BU_:  Airbag BAP_Tester ICAS1_Gateway ICAS1_KommunikationsServer LE1 LE2 Motor_BEV Schaltbetaetigung

BU_:  Airbag BAP_Tester ICAS1_Gateway ICAS1_KommunikationsServer LE1 LE2 Motor_BEV Schaltbetaetigung

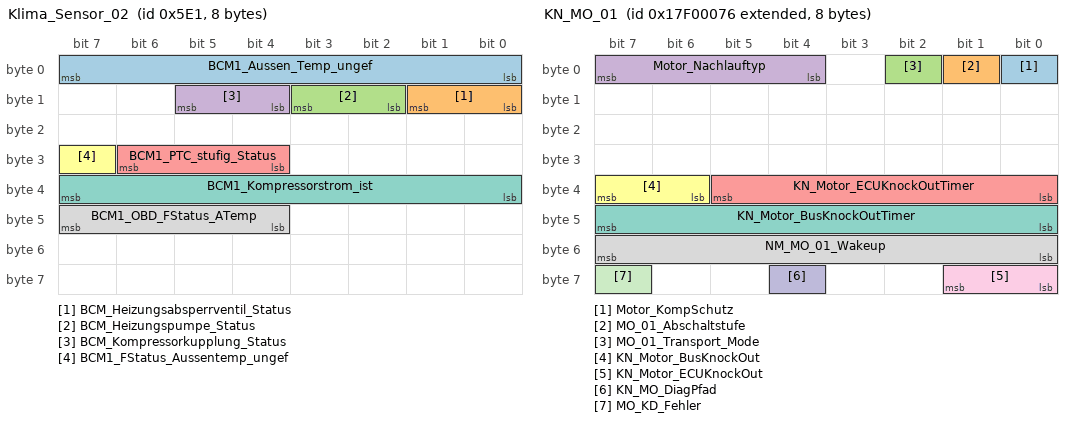
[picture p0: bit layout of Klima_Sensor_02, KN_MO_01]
BO_ 1505 Klima_Sensor_02: 8 ICAS1_Gateway
 SG_ BCM1_Aussen_Temp_ungef  : 0|8@1+ (0.500000,-50.000000) [-50.000000|76.000000] "Unit_DegreCelsi" LE1 LE2 Motor_BEV
 SG_ BCM_Heizungsabsperrventil_Status  : 8|2@1+ (1.000000,0.000000) [0.000000|3.000000] "" Vector__XXX
 SG_ BCM_Heizungspumpe_Status  : 10|2@1+ (1.000000,0.000000) [0.000000|3.000000] "" Vector__XXX
 SG_ BCM_Kompressorkupplung_Status  : 12|2@1+ (1.000000,0.000000) [0.000000|3.000000] "" Vector__XXX
 SG_ BCM1_PTC_stufig_Status  : 28|3@1+ (1.000000,0.000000) [0.000000|7.000000] "" Vector__XXX
 SG_ BCM1_FStatus_Aussentemp_ungef  : 31|1@1+ (1.000000,0.000000) [0.000000|1.000000] "" Vector__XXX
 SG_ BCM1_Kompressorstrom_ist  : 32|8@1+ (4.000000,0.000000) [0.000000|1000.000000] "Unit_MilliAmper" Vector__XXX
 SG_ BCM1_OBD_FStatus_ATemp  : 44|4@1+ (1.000000,0.000000) [0.000000|15.000000] "" Vector__XXX

BO_ 2549088277 KN_Airbag_01: 8 Airbag
 SG_ Airbag_01_KompSchutz  : 0|1@1+ (1.000000,0.000000) [0.000000|1.000000] "" Vector__XXX
 SG_ Airbag_01_Abschaltstufe  : 1|1@1+ (1.000000,0.000000) [0.000000|1.000000] "" Vector__XXX
 SG_ Airbag_01_Transport_Mode  : 2|1@1+ (1.000000,0.000000) [0.000000|1.000000] "" Vector__XXX
 SG_ Airbag_01_Nachlauftyp  : 4|4@1+ (1.000000,0.000000) [0.000000|15.000000] "" ICAS1_Gateway
 SG_ NM_Airbag_01_Wakeup  : 48|8@1+ (1.000000,0.000000) [0.000000|255.000000] "" Vector__XXX
 SG_ KN_AB_DiagPfad  : 60|1@1+ (1.000000,0.000000) [0.000000|1.000000] "" ICAS1_Gateway
 SG_ AB_KD_Fehler  : 63|1@1+ (1.000000,0.000000) [0.000000|1.000000] "" ICAS1_Gateway

BO_ 2549088380 KN_EMotor_01: 8 LE1
 SG_ EMotor_KompSchutz  : 0|1@1+ (1.000000,0.000000) [0.000000|1.000000] "" Vector__XXX
 SG_ EMotor_01_Abschaltstufe  : 1|1@1+ (1.000000,0.000000) [0.000000|1.000000] "" Vector__XXX
 SG_ EMotor_01_Transport_Mode  : 2|1@1+ (1.000000,0.000000) [0.000000|1.000000] "" Vector__XXX
 SG_ EMotor_Nachlauftyp  : 4|4@1+ (1.000000,0.000000) [0.000000|15.000000] "" ICAS1_Gateway
 SG_ NM_EMotor_01_Wakeup  : 48|8@1+ (1.000000,0.000000) [0.000000|255.000000] "" Vector__XXX
 SG_ KN_EM_HYB_DiagPfad  : 60|1@1+ (1.000000,0.000000) [0.000000|1.000000] "" ICAS1_Gateway
 SG_ EM_HYB_KD_Fehler  : 63|1@1+ (1.000000,0.000000) [0.000000|1.000000] "" ICAS1_Gateway

BO_ 2549088272 KN_Gateway: 8 ICAS1_Gateway
 SG_ Gateway_KompSchutz  : 0|1@1+ (1.000000,0.000000) [0.000000|1.000000] "" Vector__XXX
 SG_ Gateway_Abschaltstufe  : 1|1@1+ (1.000000,0.000000) [0.000000|1.000000] "" Vector__XXX
 SG_ Gateway_Transport_Mode  : 2|1@1+ (1.000000,0.000000) [0.000000|1.000000] "" Vector__XXX
 SG_ Gateway_Nachlauftyp  : 4|4@1+ (1.000000,0.000000) [0.000000|15.000000] "" Vector__XXX
 SG_ NM_Gateway_Wakeup  : 48|8@1+ (1.000000,0.000000) [0.000000|255.000000] "" Vector__XXX
 SG_ KN_GW_DiagPfad  : 60|1@1+ (1.000000,0.000000) [0.000000|1.000000] "" Vector__XXX
 SG_ GW_KD_Fehler  : 63|1@1+ (1.000000,0.000000) [0.000000|1.000000] "" Vector__XXX

BO_ 2549088440 KN_LE2: 8 LE2
 SG_ LE2_KompSchutz  : 0|1@1+ (1.000000,0.000000) [0.000000|1.000000] "" Vector__XXX
 SG_ LE2_Abschaltstufe  : 1|1@1+ (1.000000,0.000000) [0.000000|1.000000] "" Vector__XXX
 SG_ LE2_Transport_Mode  : 2|1@1+ (1.000000,0.000000) [0.000000|1.000000] "" Vector__XXX
 SG_ LE2_Nachlauftyp  : 4|4@1+ (1.000000,0.000000) [0.000000|15.000000] "" ICAS1_Gateway
 SG_ NM_LE2_Wakeup  : 48|8@1+ (1.000000,0.000000) [0.000000|255.000000] "" Vector__XXX
 SG_ KN_LE2_DiagPfad  : 60|1@1+ (1.000000,0.000000) [0.000000|1.000000] "" ICAS1_Gateway
 SG_ LE2_KD_Fehler  : 63|1@1+ (1.000000,0.000000) [0.000000|1.000000] "" ICAS1_Gateway

BO_ 2549088374 KN_MO_01: 8 Motor_BEV
 SG_ Motor_KompSchutz  : 0|1@1+ (1.000000,0.000000) [0.000000|1.000000] "" Vector__XXX
 SG_ MO_01_Abschaltstufe  : 1|1@1+ (1.000000,0.000000) [0.000000|1.000000] "" Vector__XXX
 SG_ MO_01_Transport_Mode  : 2|1@1+ (1.000000,0.000000) [0.000000|1.000000] "" Vector__XXX
 SG_ Motor_Nachlauftyp  : 4|4@1+ (1.000000,0.000000) [0.000000|15.000000] "" ICAS1_Gateway
 SG_ KN_Motor_ECUKnockOutTimer  : 32|6@1+ (1.000000,0.000000) [0.000000|62.000000] "Unit_Minut" Vector__XXX
 SG_ KN_Motor_BusKnockOut  : 38|2@1+ (1.000000,0.000000) [0.000000|3.000000] "" Vector__XXX
 SG_ KN_Motor_BusKnockOutTimer  : 40|8@1+ (1.000000,0.000000) [0.000000|254.000000] "" Vector__XXX
 SG_ NM_MO_01_Wakeup  : 48|8@1+ (1.000000,0.000000) [0.000000|255.000000] "" Vector__XXX
 SG_ KN_Motor_ECUKnockOut  : 56|2@1+ (1.000000,0.000000) [0.000000|3.000000] "" Vector__XXX
 SG_ KN_MO_DiagPfad  : 60|1@1+ (1.000000,0.000000) [0.000000|1.000000] "" ICAS1_Gateway
 SG_ MO_KD_Fehler  : 63|1@1+ (1.000000,0.000000) [0.000000|1.000000] "" ICAS1_Gateway

BO_ 2621440277 KS_Airbag_01_Req_FD: 16 ICAS1_Gateway
 SG_ KS_Airbag_01_Req_FD_Data  : 0|128@1+ (1.000000,0.000000) [0.000000|340282366920938463463374607431768211456.000000] "" Airbag

BO_ 2621571349 KS_Airbag_01_Resp_FD: 16 Airbag
 SG_ KS_Airbag_01_Resp_FD_Data  : 0|128@1+ (1.000000,0.000000) [0.000000|340282366920938463463374607431768211456.000000] "" ICAS1_Gateway

BO_ 982 Licht_hinten_01: 8 ICAS1_Gateway
 SG_ Licht_hinten_01_BZ  : 0|4@1+ (1.000000,0.000000) [0.000000|15.000000] "" Vector__XXX
 SG_ LH_Aussenlicht_def  : 7|1@1+ (1.000000,0.000000) [0.000000|1.000000] "" Vector__XXX
 SG_ LH_Standlicht_H_aktiv  : 8|1@1+ (1.000000,0.000000) [0.000000|1.000000] "" Vector__XXX
 SG_ LH_Parklicht_HL_aktiv  : 9|1@1+ (1.000000,0.000000) [0.000000|1.000000] "" Vector__XXX
 SG_ LH_Parklicht_HR_aktiv  : 10|1@1+ (1.000000,0.000000) [0.000000|1.000000] "" Vector__XXX
 SG_ LH_Bremslicht_H_aktiv  : 11|1@1+ (1.000000,0.000000) [0.000000|1.000000] "" Vector__XXX
 SG_ LH_Nebelschluss_aktiv  : 12|1@1+ (1.000000,0.000000) [0.000000|1.000000] "" Vector__XXX
 SG_ LH_Rueckfahrlicht_aktiv  : 13|1@1+ (1.000000,0.000000) [0.000000|1.000000] "" Vector__XXX
 SG_ LH_Blinker_HL_akt  : 14|1@1+ (1.000000,0.000000) [0.000000|1.000000] "" Vector__XXX
 SG_ LH_Blinker_HR_akt  : 15|1@1+ (1.000000,0.000000) [0.000000|1.000000] "" Vector__XXX
 SG_ LH_Blinker_li_def  : 16|1@1+ (1.000000,0.000000) [0.000000|1.000000] "" Vector__XXX
 SG_ LH_Bremsl_li_def  : 17|1@1+ (1.000000,0.000000) [0.000000|1.000000] "" Vector__XXX
 SG_ LH_Schlusslicht_li_def  : 18|1@1+ (1.000000,0.000000) [0.000000|1.000000] "" Vector__XXX
 SG_ LH_Rueckf_li_def  : 19|1@1+ (1.000000,0.000000) [0.000000|1.000000] "" Vector__XXX
 SG_ LH_Nebel_li_def  : 20|1@1+ (1.000000,0.000000) [0.000000|1.000000] "" Vector__XXX
 SG_ LH_Schluss_Brems_Nebel_li_def  : 21|1@1+ (1.000000,0.000000) [0.000000|1.000000] "" Vector__XXX
 SG_ LH_Schluss_Brems_Nebel_re_def  : 22|1@1+ (1.000000,0.000000) [0.000000|1.000000] "" Vector__XXX
 SG_ LH_Zusatzschlussl_def  : 23|1@1+ (1.000000,0.000000) [0.000000|1.000000] "" Vector__XXX
 SG_ LH_Schluss_Brems_li_def  : 24|1@1+ (1.000000,0.000000) [0.000000|1.000000] "" Vector__XXX
 SG_ LH_Schluss_Nebel_li_def  : 25|1@1+ (1.000000,0.000000) [0.000000|1.000000] "" Vector__XXX
 SG_ LH_SL_BRL_BLK_li_def  : 26|1@1+ (1.000000,0.000000) [0.000000|1.000000] "" Vector__XXX
 SG_ LH_Brems_Blk_li_def  : 27|1@1+ (1.000000,0.000000) [0.000000|1.000000] "" Vector__XXX
 SG_ LH_Diag_Status_re_def  : 28|1@1+ (1.000000,0.000000) [0.000000|1.000000] "" Vector__XXX
 SG_ LH_Diag_Status_li_def  : 29|1@1+ (1.000000,0.000000) [0.000000|1.000000] "" Vector__XXX
 SG_ LH_Diag_LED_li_def  : 30|1@1+ (1.000000,0.000000) [0.000000|1.000000] "" Vector__XXX
 SG_ LH_Diag_LED_re_def  : 31|1@1+ (1.000000,0.000000) [0.000000|1.000000] "" Vector__XXX
 SG_ LH_Blinker_re_def  : 32|1@1+ (1.000000,0.000000) [0.000000|1.000000] "" Vector__XXX
 SG_ LH_Bremsl_re_def  : 33|1@1+ (1.000000,0.000000) [0.000000|1.000000] "" Vector__XXX
 SG_ LH_Schlusslicht_re_def  : 34|1@1+ (1.000000,0.000000) [0.000000|1.000000] "" Vector__XXX
 SG_ LH_Rueckf_re_def  : 35|1@1+ (1.000000,0.000000) [0.000000|1.000000] "" Vector__XXX
 SG_ LH_Nebel_re_def  : 36|1@1+ (1.000000,0.000000) [0.000000|1.000000] "" Vector__XXX
 SG_ LH_Schluss_Brems_mi_def  : 37|1@1+ (1.000000,0.000000) [0.000000|1.000000] "" Vector__XXX
 SG_ LH_Schluss_Brems_re_def  : 40|1@1+ (1.000000,0.000000) [0.000000|1.000000] "" Vector__XXX
 SG_ LH_Schluss_Nebel_re_def  : 41|1@1+ (1.000000,0.000000) [0.000000|1.000000] "" Vector__XXX
 SG_ LH_SL_BRL_BLK_re_def  : 42|1@1+ (1.000000,0.000000) [0.000000|1.000000] "" Vector__XXX
 SG_ LH_Brems_Blk_re_def  : 43|1@1+ (1.000000,0.000000) [0.000000|1.000000] "" Vector__XXX
 SG_ LH_Kennzl_def  : 48|1@1+ (1.000000,0.000000) [0.000000|1.000000] "" Vector__XXX
 SG_ LH_3_Bremsl_def  : 49|1@1+ (1.000000,0.000000) [0.000000|1.000000] "" Motor_BEV
 SG_ LH_Nebel_mi_def  : 50|1@1+ (1.000000,0.000000) [0.000000|1.000000] "" Vector__XXX
 SG_ LH_Rueckf_mi_def  : 51|1@1+ (1.000000,0.000000) [0.000000|1.000000] "" Vector__XXX
 SG_ LH_Schlusslicht_mi_def  : 52|1@1+ (1.000000,0.000000) [0.000000|1.000000] "" Vector__XXX
 SG_ LH_Bremsl_li_ges_def  : 54|1@1+ (1.000000,0.000000) [0.000000|1.000000] "" Motor_BEV
 SG_ LH_Bremsl_re_ges_def  : 55|1@1+ (1.000000,0.000000) [0.000000|1.000000] "" Motor_BEV
 SG_ LH_Bremsl_mi_def  : 61|1@1+ (1.000000,0.000000) [0.000000|1.000000] "" Vector__XXX
 SG_ BRL_als_SHL  : 62|1@1+ (1.000000,0.000000) [0.000000|1.000000] "" Vector__XXX

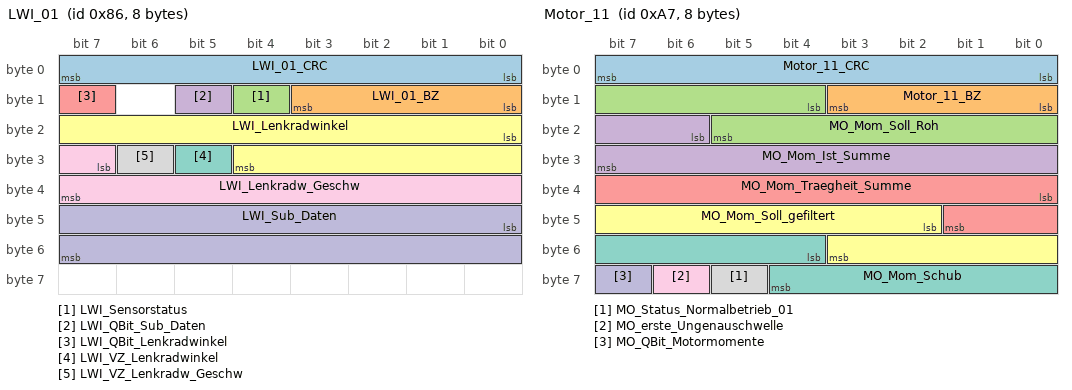
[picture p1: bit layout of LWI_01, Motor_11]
BO_ 134 LWI_01: 8 ICAS1_Gateway
 SG_ LWI_01_CRC  : 0|8@1+ (1.000000,0.000000) [0.000000|255.000000] "" Airbag Motor_BEV
 SG_ LWI_01_BZ  : 8|4@1+ (1.000000,0.000000) [0.000000|15.000000] "" Airbag Motor_BEV
 SG_ LWI_Sensorstatus  : 12|1@1+ (1.000000,0.000000) [0.000000|1.000000] "" Airbag Motor_BEV
 SG_ LWI_QBit_Sub_Daten  : 13|1@1+ (1.000000,0.000000) [0.000000|1.000000] "" Vector__XXX
 SG_ LWI_QBit_Lenkradwinkel  : 15|1@1+ (1.000000,0.000000) [0.000000|1.000000] "" Airbag Motor_BEV
 SG_ LWI_Lenkradwinkel  : 16|13@1+ (0.100000,0.000000) [0.000000|800.000000] "Unit_DegreOfArc" Airbag Motor_BEV
 SG_ LWI_VZ_Lenkradwinkel  : 29|1@1+ (1.000000,0.000000) [0.000000|1.000000] "" Airbag Motor_BEV
 SG_ LWI_VZ_Lenkradw_Geschw  : 30|1@1+ (1.000000,0.000000) [0.000000|1.000000] "" Vector__XXX
 SG_ LWI_Lenkradw_Geschw  : 31|9@1+ (5.000000,0.000000) [0.000000|2500.000000] "Unit_DegreOfArcPerSecon" Airbag
 SG_ LWI_Sub_Daten  : 40|16@1+ (1.000000,0.000000) [0.000000|65535.000000] "" Vector__XXX

BO_ 817 MFL_01: 8 ICAS1_Gateway
 SG_ MFL_Zaehler  : 0|4@1+ (1.000000,0.000000) [0.000000|15.000000] "" Vector__XXX
 SG_ MFL_Toggle  : 4|1@1+ (1.000000,0.000000) [0.000000|1.000000] "" Vector__XXX
 SG_ MFL_Lokalaktiv  : 5|1@1+ (1.000000,0.000000) [0.000000|1.000000] "" Vector__XXX
 SG_ MFL_M_Taste  : 6|1@1+ (1.000000,0.000000) [0.000000|1.000000] "" Vector__XXX
 SG_ MFL_Paddle_Verbau  : 7|1@1+ (1.000000,0.000000) [0.000000|1.000000] "" Vector__XXX
 SG_ MFL_Tastencode_1  : 8|8@1+ (1.000000,0.000000) [0.000000|255.000000] "" Vector__XXX
 SG_ MFL_Tastencode_2  : 16|8@1+ (1.000000,0.000000) [0.000000|255.000000] "" Vector__XXX
 SG_ MFL_Eventcode_1  : 24|4@1+ (1.000000,0.000000) [0.000000|15.000000] "" Vector__XXX
 SG_ MFL_Eventcode_2  : 28|4@1+ (1.000000,0.000000) [0.000000|15.000000] "" Vector__XXX
 SG_ MFL_Marke  : 32|4@1+ (1.000000,0.000000) [0.000000|15.000000] "" Vector__XXX
 SG_ MFL_Variante  : 36|4@1+ (1.000000,0.000000) [0.000000|15.000000] "" Vector__XXX
 SG_ MFL_Dummy_0_Signal_1  : 40|8@1+ (1.000000,0.000000) [0.000000|255.000000] "" Vector__XXX
 SG_ MFL_Tip_Down  : 48|1@1+ (1.000000,0.000000) [0.000000|1.000000] "" Motor_BEV
 SG_ MFL_Tip_Up  : 49|1@1+ (1.000000,0.000000) [0.000000|1.000000] "" Motor_BEV
 SG_ MFL_SatModul_links_Err  : 50|1@1+ (1.000000,0.000000) [0.000000|1.000000] "" Vector__XXX
 SG_ MFL_SatModul_rechts_Err  : 51|1@1+ (1.000000,0.000000) [0.000000|1.000000] "" Vector__XXX
 SG_ MFL_Dummy_0_Signal_2  : 52|1@1+ (1.000000,0.000000) [0.000000|1.000000] "" Vector__XXX
 SG_ MFL_Dummy_0_Signal_3  : 53|1@1+ (1.000000,0.000000) [0.000000|1.000000] "" Vector__XXX
 SG_ MFL_LR_HZG_Status  : 54|1@1+ (1.000000,0.000000) [0.000000|1.000000] "" Vector__XXX
 SG_ MFL_LR_HZG_Err  : 55|1@1+ (1.000000,0.000000) [0.000000|1.000000] "" Vector__XXX
 SG_ MFL_Signalhorn  : 56|1@1+ (1.000000,0.000000) [0.000000|1.000000] "" Vector__XXX
 SG_ MFL_Signalhorn_Err  : 57|1@1+ (1.000000,0.000000) [0.000000|1.000000] "" Vector__XXX
 SG_ MFL_Tip_links_Err  : 58|1@1+ (1.000000,0.000000) [0.000000|1.000000] "" Vector__XXX
 SG_ MFL_Tip_rechts_Err  : 59|1@1+ (1.000000,0.000000) [0.000000|1.000000] "" Vector__XXX
 SG_ MFL_Taste_links_Err  : 60|1@1+ (1.000000,0.000000) [0.000000|1.000000] "" Vector__XXX
 SG_ MFL_Taste_rechts_Err  : 61|1@1+ (1.000000,0.000000) [0.000000|1.000000] "" Vector__XXX
 SG_ MFL_ECU_Err  : 62|1@1+ (1.000000,0.000000) [0.000000|1.000000] "" Vector__XXX
 SG_ MFL_Response_Err  : 63|1@1+ (1.000000,0.000000) [0.000000|1.000000] "" Vector__XXX

BO_ 15 MO_SOPC: 1 Motor_BEV
 SG_ MO_SOPC  : 0|1@1+ (1.000000,0.000000) [0.000000|1.000000] "" Vector__XXX

BO_ 1600 Motor_07: 8 Motor_BEV
 SG_ MO_QBit_Ansaugluft_Temp  : 0|1@1+ (1.000000,0.000000) [0.000000|1.000000] "" Vector__XXX
 SG_ MO_QBit_Oel_Temp  : 1|1@1+ (1.000000,0.000000) [0.000000|1.000000] "" Vector__XXX
 SG_ MO_QBit_Kuehlmittel_Temp  : 2|1@1+ (1.000000,0.000000) [0.000000|1.000000] "" Vector__XXX
 SG_ MO_KL15_Abschaltempfehlung  : 3|1@1+ (1.000000,0.000000) [0.000000|1.000000] "" Vector__XXX
 SG_ MO_HYB_Fehler_HV_Netz  : 4|1@1+ (1.000000,0.000000) [0.000000|1.000000] "" Vector__XXX
 SG_ MO_aktives_Getriebeheizen  : 5|1@1+ (1.000000,0.000000) [0.000000|1.000000] "" Vector__XXX
 SG_ MO_Absperrventil_oeffnen  : 6|2@1+ (1.000000,0.000000) [0.000000|3.000000] "" Vector__XXX
 SG_ MO_Ansaugluft_Temp  : 8|8@1+ (0.750000,-48.000000) [-48.000000|141.750000] "Unit_DegreCelsi" Vector__XXX
 SG_ MO_Oel_Temp  : 16|8@1+ (1.000000,-60.000000) [-60.000000|192.000000] "Unit_DegreCelsi" Vector__XXX
 SG_ MO_Kuehlmittel_Temp  : 24|8@1+ (0.750000,-48.000000) [-48.000000|141.750000] "Unit_DegreCelsi" Vector__XXX
 SG_ MO_Hoeheninfo  : 32|8@1+ (0.007810,0.000000) [0.000000|1.983740] "" Vector__XXX
 SG_ MO_Kennfeldk  : 40|1@1+ (1.000000,0.000000) [0.000000|1.000000] "" Vector__XXX
 SG_ MO_Versionsinfo_02  : 41|5@1+ (1.000000,0.000000) [0.000000|31.000000] "" Vector__XXX
 SG_ MO_QBit_Hoeheninfo  : 46|1@1+ (1.000000,0.000000) [0.000000|1.000000] "" Vector__XXX
 SG_ MO_Getriebe_kuehlen  : 47|1@1+ (1.000000,0.000000) [0.000000|1.000000] "" Vector__XXX
 SG_ MO_Mom_Traegheit_02  : 48|5@1+ (0.010000,0.000000) [0.000000|0.310000] "Unit_KiloGramMeterSquar" Vector__XXX
 SG_ MO_Heizungspumpenansteuerung  : 53|4@1+ (10.000000,0.000000) [0.000000|100.000000] "Unit_PerCent" Vector__XXX
 SG_ MO_SpannungsAnf  : 57|1@1+ (1.000000,0.000000) [0.000000|1.000000] "" Vector__XXX
 SG_ MO_Nachlaufzeit_Heizungspumpe  : 58|6@1+ (15.000000,0.000000) [0.000000|945.000000] "Unit_Secon" Vector__XXX

BO_ 167 Motor_11: 8 Motor_BEV
 SG_ Motor_11_CRC  : 0|8@1+ (1.000000,0.000000) [0.000000|255.000000] "" ICAS1_Gateway
 SG_ Motor_11_BZ  : 8|4@1+ (1.000000,0.000000) [0.000000|15.000000] "" ICAS1_Gateway
 SG_ MO_Mom_Soll_Roh  : 12|10@1+ (1.000000,-509.000000) [-509.000000|509.000000] "" ICAS1_Gateway
 SG_ MO_Mom_Ist_Summe  : 22|10@1+ (1.000000,-509.000000) [-509.000000|509.000000] "" ICAS1_Gateway
 SG_ MO_Mom_Traegheit_Summe  : 32|10@1+ (1.000000,-509.000000) [-509.000000|509.000000] "" ICAS1_Gateway
 SG_ MO_Mom_Soll_gefiltert  : 42|10@1+ (1.000000,-509.000000) [-509.000000|509.000000] "" ICAS1_Gateway
 SG_ MO_Mom_Schub  : 52|9@1+ (1.000000,-509.000000) [-509.000000|0.000000] "" ICAS1_Gateway
 SG_ MO_Status_Normalbetrieb_01  : 61|1@1+ (1.000000,0.000000) [0.000000|1.000000] "" ICAS1_Gateway
 SG_ MO_erste_Ungenauschwelle  : 62|1@1+ (1.000000,0.000000) [0.000000|1.000000] "" ICAS1_Gateway
 SG_ MO_QBit_Motormomente  : 63|1@1+ (1.000000,0.000000) [0.000000|1.000000] "" ICAS1_Gateway

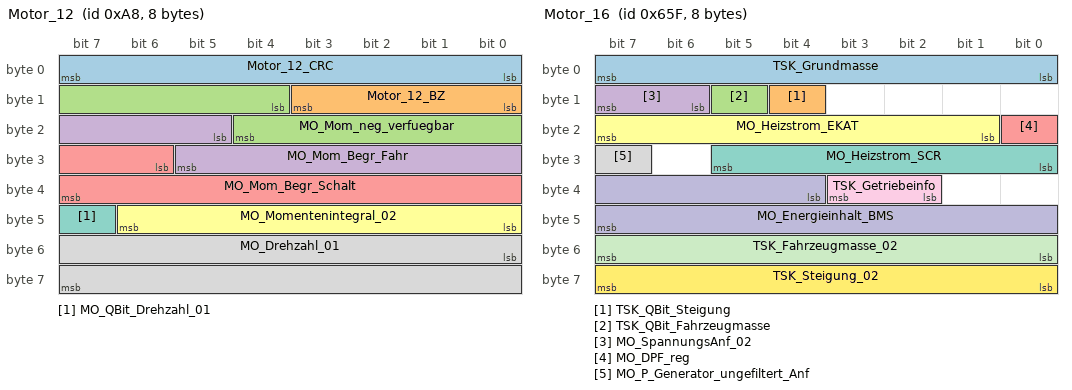
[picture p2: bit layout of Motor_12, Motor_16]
BO_ 168 Motor_12: 8 Motor_BEV
 SG_ Motor_12_CRC  : 0|8@1+ (1.000000,0.000000) [0.000000|255.000000] "" ICAS1_Gateway
 SG_ Motor_12_BZ  : 8|4@1+ (1.000000,0.000000) [0.000000|15.000000] "" ICAS1_Gateway
 SG_ MO_Mom_neg_verfuegbar  : 12|9@1+ (1.000000,-509.000000) [-509.000000|0.000000] "" ICAS1_Gateway
 SG_ MO_Mom_Begr_Fahr  : 21|9@1+ (1.000000,0.000000) [0.000000|509.000000] "" ICAS1_Gateway
 SG_ MO_Mom_Begr_Schalt  : 30|10@1+ (1.000000,-509.000000) [-509.000000|509.000000] "" ICAS1_Gateway
 SG_ MO_Momentenintegral_02  : 40|7@1+ (1.000000,0.000000) [0.000000|100.000000] "Unit_PerCent" ICAS1_Gateway
 SG_ MO_QBit_Drehzahl_01  : 47|1@1+ (1.000000,0.000000) [0.000000|1.000000] "" Airbag ICAS1_Gateway LE2
 SG_ MO_Drehzahl_01  : 48|16@1+ (0.250000,0.000000) [0.000000|16383.000000] "Unit_MinutInver" ICAS1_Gateway

BO_ 958 Motor_14: 8 Motor_BEV
 SG_ Motor_14_CRC  : 0|8@1+ (1.000000,0.000000) [0.000000|255.000000] "" ICAS1_Gateway
 SG_ Motor_14_BZ  : 8|4@1+ (1.000000,0.000000) [0.000000|15.000000] "" ICAS1_Gateway
 SG_ MO_StartStopp_Status  : 12|2@1+ (1.000000,0.000000) [0.000000|3.000000] "" ICAS1_Gateway
 SG_ MO_StartStopp_Wiederstart  : 14|1@1+ (1.000000,0.000000) [0.000000|1.000000] "" ICAS1_Gateway
 SG_ MO_StartStopp_Motorstopp  : 15|1@1+ (1.000000,0.000000) [0.000000|1.000000] "" ICAS1_Gateway
 SG_ MO_Freig_Reku  : 16|2@1+ (1.000000,0.000000) [0.000000|3.000000] "" ICAS1_Gateway
 SG_ MO_Kl_75  : 18|1@1+ (1.000000,0.000000) [0.000000|1.000000] "" ICAS1_Gateway
 SG_ MO_Kl_50  : 19|1@1+ (1.000000,0.000000) [0.000000|1.000000] "" ICAS1_Gateway
 SG_ MO_Gangposition  : 20|4@1+ (1.000000,0.000000) [0.000000|15.000000] "" ICAS1_Gateway
 SG_ MO_StartStopp_Fahrerwunsch  : 24|2@1+ (1.000000,0.000000) [0.000000|3.000000] "" ICAS1_Gateway
 SG_ MO_HYB_Fahrbereitschaft  : 26|1@1+ (1.000000,0.000000) [0.000000|1.000000] "" ICAS1_Gateway
 SG_ MO_Ext_E_Fahrt_aktiv  : 27|1@1+ (1.000000,0.000000) [0.000000|1.000000] "" ICAS1_Gateway
 SG_ MO_Fahrer_bremst  : 28|1@1+ (1.000000,0.000000) [0.000000|1.000000] "" Airbag ICAS1_Gateway
 SG_ MO_QBit_Fahrer_bremst  : 29|1@1+ (1.000000,0.000000) [0.000000|1.000000] "" Airbag ICAS1_Gateway
 SG_ MO_BLS  : 30|1@1+ (1.000000,0.000000) [0.000000|1.000000] "" Airbag ICAS1_Gateway
 SG_ MO_Konsistenz_Bremsped  : 31|1@1+ (1.000000,0.000000) [0.000000|1.000000] "" ICAS1_Gateway
 SG_ MO_Timeout_ESP  : 32|1@1+ (1.000000,0.000000) [0.000000|1.000000] "" ICAS1_Gateway
 SG_ MO_Klima_Eingr  : 33|2@1+ (1.000000,0.000000) [0.000000|3.000000] "" ICAS1_Gateway
 SG_ MO_Aussp_Anlass  : 35|1@1+ (1.000000,0.000000) [0.000000|1.000000] "" ICAS1_Gateway
 SG_ MO_Freig_Anlass  : 36|1@1+ (1.000000,0.000000) [0.000000|1.000000] "" ICAS1_Gateway
 SG_ MO_Kuppl_schalter  : 37|1@1+ (1.000000,0.000000) [0.000000|1.000000] "" ICAS1_Gateway
 SG_ MO_Interlock  : 38|1@1+ (1.000000,0.000000) [0.000000|1.000000] "" ICAS1_Gateway
 SG_ MO_Motor_laeuft  : 39|1@1+ (1.000000,0.000000) [0.000000|1.000000] "" ICAS1_Gateway
 SG_ MO_Kickdown  : 40|1@1+ (1.000000,0.000000) [0.000000|1.000000] "" ICAS1_Gateway ICAS1_KommunikationsServer
 SG_ MO_QBit_KL_75  : 41|1@1+ (1.000000,0.000000) [0.000000|1.000000] "" ICAS1_Gateway
 SG_ MO_EKlKomLeiRed  : 42|2@1+ (1.000000,0.000000) [0.000000|3.000000] "" ICAS1_Gateway
 SG_ MO_Handshake_STH  : 44|1@1+ (1.000000,0.000000) [0.000000|1.000000] "" ICAS1_Gateway
 SG_ MO_BKV_Unterdruckwarnung  : 45|1@1+ (1.000000,0.000000) [0.000000|1.000000] "" ICAS1_Gateway
 SG_ MO_Freigabe_Segeln  : 46|1@1+ (1.000000,0.000000) [0.000000|1.000000] "" ICAS1_Gateway
 SG_ MO_PTC_Status  : 47|3@1+ (1.000000,0.000000) [0.000000|7.000000] "" ICAS1_Gateway
 SG_ MO_QBit_Gangposition  : 50|1@1+ (1.000000,0.000000) [0.000000|1.000000] "" ICAS1_Gateway
 SG_ MO_Signalquelle_Gangposition  : 51|1@1+ (1.000000,0.000000) [0.000000|1.000000] "" ICAS1_Gateway
 SG_ MO_Remotestart_Betrieb  : 52|1@1+ (1.000000,0.000000) [0.000000|1.000000] "" ICAS1_Gateway
 SG_ MO_Remotestart_moeglich  : 53|1@1+ (1.000000,0.000000) [0.000000|1.000000] "" ICAS1_Gateway
 SG_ MO_FMAus_aktiv  : 55|1@1+ (1.000000,0.000000) [0.000000|1.000000] "" ICAS1_Gateway
 SG_ MO_FMAus_Startvariante  : 56|2@1+ (1.000000,0.000000) [0.000000|3.000000] "" ICAS1_Gateway
 SG_ MO_BMS_NV_Anf_stuetzen  : 58|1@1+ (1.000000,0.000000) [0.000000|1.000000] "" ICAS1_Gateway
 SG_ MO_Zylinderabschaltung  : 59|2@1+ (1.000000,0.000000) [0.000000|3.000000] "" ICAS1_Gateway
 SG_ MO_HYB_VM_aktiv  : 61|1@1+ (1.000000,0.000000) [0.000000|1.000000] "" ICAS1_Gateway
 SG_ MO_StartVorauss_erfuellt  : 62|2@1+ (1.000000,0.000000) [0.000000|3.000000] "" ICAS1_Gateway

BO_ 1631 Motor_16: 8 Motor_BEV
 SG_ TSK_Grundmasse  : 0|8@1+ (32.000000,0.000000) [0.000000|8128.000000] "Unit_KiloGram" ICAS1_Gateway
 SG_ TSK_QBit_Steigung  : 12|1@1+ (1.000000,0.000000) [0.000000|1.000000] "" ICAS1_Gateway
 SG_ TSK_QBit_Fahrzeugmasse  : 13|1@1+ (1.000000,0.000000) [0.000000|1.000000] "" ICAS1_Gateway
 SG_ MO_SpannungsAnf_02  : 14|2@1+ (1.000000,0.000000) [0.000000|3.000000] "" ICAS1_Gateway
 SG_ MO_DPF_reg  : 16|1@1+ (1.000000,0.000000) [0.000000|1.000000] "" ICAS1_Gateway
 SG_ MO_Heizstrom_EKAT  : 17|7@1+ (1.000000,0.000000) [0.000000|126.000000] "Unit_Amper" ICAS1_Gateway
 SG_ MO_Heizstrom_SCR  : 24|6@1+ (1.000000,0.000000) [0.000000|62.000000] "Unit_Amper" ICAS1_Gateway
 SG_ MO_P_Generator_ungefiltert_Anf  : 31|1@1+ (1.000000,0.000000) [0.000000|1.000000] "" ICAS1_Gateway
 SG_ TSK_Getriebeinfo  : 34|2@1+ (1.000000,0.000000) [0.000000|3.000000] "" ICAS1_Gateway
 SG_ MO_Energieinhalt_BMS  : 36|12@1+ (25.000000,0.000000) [0.000000|102325.000000] "Unit_WattHour" ICAS1_Gateway
 SG_ TSK_Fahrzeugmasse_02  : 48|8@1+ (32.000000,0.000000) [0.000000|8128.000000] "Unit_KiloGram" ICAS1_Gateway
 SG_ TSK_Steigung_02  : 56|8@1+ (0.800000,-101.600000) [-100.800000|101.600000] "Unit_PerCent" ICAS1_Gateway

BO_ 1648 Motor_18: 8 Motor_BEV
 SG_ MO_max_Ladedruck  : 0|6@1+ (0.100000,0.000000) [0.000000|6.300000] "Unit_Bar" ICAS1_Gateway
 SG_ MO_ANC_Kennfeld_Anf  : 6|2@1+ (1.000000,0.000000) [0.000000|3.000000] "" ICAS1_Gateway
 SG_ MO_Bremslicht_Reku  : 8|1@1+ (1.000000,0.000000) [0.000000|1.000000] "" ICAS1_Gateway
 SG_ MO_StartStopp_PopUp  : 9|2@1+ (1.000000,0.000000) [0.000000|3.000000] "" ICAS1_Gateway
 SG_ MO1_Sperr_Info_WFS  : 11|1@1+ (1.000000,0.000000) [0.000000|1.000000] "" ICAS1_Gateway
 SG_ MO1_Freigabe_Info_WFS  : 12|1@1+ (1.000000,0.000000) [0.000000|1.000000] "" ICAS1_Gateway
 SG_ MO_EPCL  : 13|3@1+ (1.000000,0.000000) [0.000000|7.000000] "" ICAS1_Gateway ICAS1_KommunikationsServer
 SG_ MO_Zylabsch_Texte_02  : 16|4@1+ (1.000000,0.000000) [0.000000|15.000000] "" ICAS1_Gateway
 SG_ MO_Fahrzeugtyp  : 20|3@1+ (1.000000,0.000000) [0.000000|7.000000] "" ICAS1_Gateway ICAS1_KommunikationsServer
 SG_ MO_NMAX_Schaltanzeige  : 23|9@1+ (25.000000,0.000000) [0.000000|12775.000000] "Unit_MinutInver" ICAS1_Gateway
 SG_ MO_Abstellzeit  : 32|8@1+ (8.000000,0.000000) [0.000000|2024.000000] "Unit_Minut" ICAS1_Gateway
 SG_ MO_Abstellzeit_Status  : 40|2@1+ (1.000000,0.000000) [0.000000|3.000000] "" ICAS1_Gateway
 SG_ MO1_Freigabe_Verfallsinfo_WFS  : 42|1@1+ (1.000000,0.000000) [0.000000|1.000000] "" ICAS1_Gateway
 SG_ MO_Hybrid_StartStopp_LED  : 43|2@1+ (1.000000,0.000000) [0.000000|3.000000] "" ICAS1_Gateway
 SG_ MO_Fehler_Zylabsch  : 45|2@1+ (1.000000,0.000000) [0.000000|3.000000] "" ICAS1_Gateway
 SG_ MO_Anzahl_Abgesch_Zyl  : 47|3@1+ (1.000000,0.000000) [0.000000|7.000000] "" ICAS1_Gateway
 SG_ MO_Zylabsch_Texte  : 50|2@1+ (1.000000,0.000000) [0.000000|3.000000] "" ICAS1_Gateway
 SG_ MO_Ethanol_BS_Texte  : 52|3@1+ (1.000000,0.000000) [0.000000|7.000000] "" ICAS1_Gateway
 SG_ MO_Drehzahl_Warnung  : 55|1@1+ (1.000000,0.000000) [0.000000|1.000000] "" ICAS1_Gateway
 SG_ MO_obere_Drehzahlgrenze  : 56|8@1+ (50.000000,0.000000) [50.000000|12750.000000] "Unit_MinutInver" ICAS1_Gateway

BU_:  Airbag BAP_Tester ICAS1_Gateway ICAS1_KommunikationsServer LE1 LE2 Motor_BEV Schaltbetaetigung

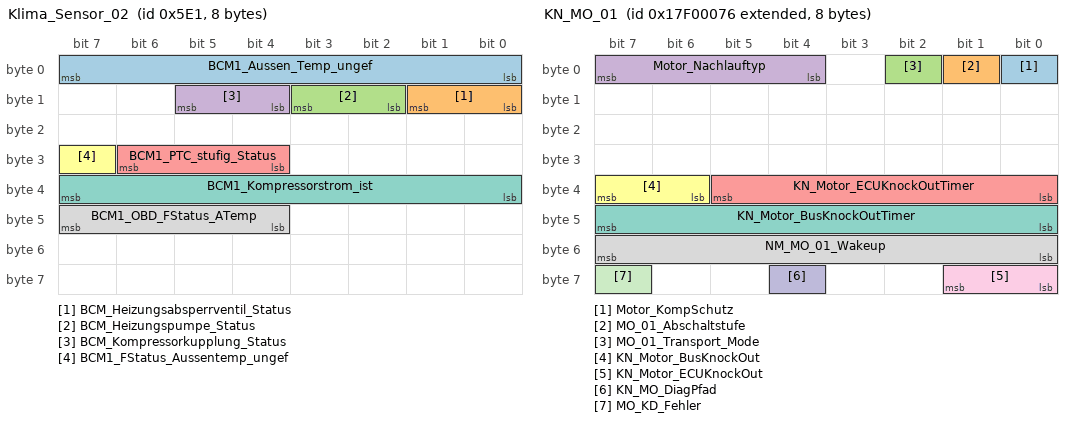
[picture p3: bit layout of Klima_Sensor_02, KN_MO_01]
BO_ 1505 Klima_Sensor_02: 8 ICAS1_Gateway
 SG_ BCM1_Aussen_Temp_ungef  : 0|8@1+ (0.500000,-50.000000) [-50.000000|76.000000] "Unit_DegreCelsi" LE1 LE2 Motor_BEV
 SG_ BCM_Heizungsabsperrventil_Status  : 8|2@1+ (1.000000,0.000000) [0.000000|3.000000] "" Vector__XXX
 SG_ BCM_Heizungspumpe_Status  : 10|2@1+ (1.000000,0.000000) [0.000000|3.000000] "" Vector__XXX
 SG_ BCM_Kompressorkupplung_Status  : 12|2@1+ (1.000000,0.000000) [0.000000|3.000000] "" Vector__XXX
 SG_ BCM1_PTC_stufig_Status  : 28|3@1+ (1.000000,0.000000) [0.000000|7.000000] "" Vector__XXX
 SG_ BCM1_FStatus_Aussentemp_ungef  : 31|1@1+ (1.000000,0.000000) [0.000000|1.000000] "" Vector__XXX
 SG_ BCM1_Kompressorstrom_ist  : 32|8@1+ (4.000000,0.000000) [0.000000|1000.000000] "Unit_MilliAmper" Vector__XXX
 SG_ BCM1_OBD_FStatus_ATemp  : 44|4@1+ (1.000000,0.000000) [0.000000|15.000000] "" Vector__XXX

BO_ 2549088277 KN_Airbag_01: 8 Airbag
 SG_ Airbag_01_KompSchutz  : 0|1@1+ (1.000000,0.000000) [0.000000|1.000000] "" Vector__XXX
 SG_ Airbag_01_Abschaltstufe  : 1|1@1+ (1.000000,0.000000) [0.000000|1.000000] "" Vector__XXX
 SG_ Airbag_01_Transport_Mode  : 2|1@1+ (1.000000,0.000000) [0.000000|1.000000] "" Vector__XXX
 SG_ Airbag_01_Nachlauftyp  : 4|4@1+ (1.000000,0.000000) [0.000000|15.000000] "" ICAS1_Gateway
 SG_ NM_Airbag_01_Wakeup  : 48|8@1+ (1.000000,0.000000) [0.000000|255.000000] "" Vector__XXX
 SG_ KN_AB_DiagPfad  : 60|1@1+ (1.000000,0.000000) [0.000000|1.000000] "" ICAS1_Gateway
 SG_ AB_KD_Fehler  : 63|1@1+ (1.000000,0.000000) [0.000000|1.000000] "" ICAS1_Gateway

BO_ 2549088380 KN_EMotor_01: 8 LE1
 SG_ EMotor_KompSchutz  : 0|1@1+ (1.000000,0.000000) [0.000000|1.000000] "" Vector__XXX
 SG_ EMotor_01_Abschaltstufe  : 1|1@1+ (1.000000,0.000000) [0.000000|1.000000] "" Vector__XXX
 SG_ EMotor_01_Transport_Mode  : 2|1@1+ (1.000000,0.000000) [0.000000|1.000000] "" Vector__XXX
 SG_ EMotor_Nachlauftyp  : 4|4@1+ (1.000000,0.000000) [0.000000|15.000000] "" ICAS1_Gateway
 SG_ NM_EMotor_01_Wakeup  : 48|8@1+ (1.000000,0.000000) [0.000000|255.000000] "" Vector__XXX
 SG_ KN_EM_HYB_DiagPfad  : 60|1@1+ (1.000000,0.000000) [0.000000|1.000000] "" ICAS1_Gateway
 SG_ EM_HYB_KD_Fehler  : 63|1@1+ (1.000000,0.000000) [0.000000|1.000000] "" ICAS1_Gateway

BO_ 2549088272 KN_Gateway: 8 ICAS1_Gateway
 SG_ Gateway_KompSchutz  : 0|1@1+ (1.000000,0.000000) [0.000000|1.000000] "" Vector__XXX
 SG_ Gateway_Abschaltstufe  : 1|1@1+ (1.000000,0.000000) [0.000000|1.000000] "" Vector__XXX
 SG_ Gateway_Transport_Mode  : 2|1@1+ (1.000000,0.000000) [0.000000|1.000000] "" Vector__XXX
 SG_ Gateway_Nachlauftyp  : 4|4@1+ (1.000000,0.000000) [0.000000|15.000000] "" Vector__XXX
 SG_ NM_Gateway_Wakeup  : 48|8@1+ (1.000000,0.000000) [0.000000|255.000000] "" Vector__XXX
 SG_ KN_GW_DiagPfad  : 60|1@1+ (1.000000,0.000000) [0.000000|1.000000] "" Vector__XXX
 SG_ GW_KD_Fehler  : 63|1@1+ (1.000000,0.000000) [0.000000|1.000000] "" Vector__XXX

BO_ 2549088440 KN_LE2: 8 LE2
 SG_ LE2_KompSchutz  : 0|1@1+ (1.000000,0.000000) [0.000000|1.000000] "" Vector__XXX
 SG_ LE2_Abschaltstufe  : 1|1@1+ (1.000000,0.000000) [0.000000|1.000000] "" Vector__XXX
 SG_ LE2_Transport_Mode  : 2|1@1+ (1.000000,0.000000) [0.000000|1.000000] "" Vector__XXX
 SG_ LE2_Nachlauftyp  : 4|4@1+ (1.000000,0.000000) [0.000000|15.000000] "" ICAS1_Gateway
 SG_ NM_LE2_Wakeup  : 48|8@1+ (1.000000,0.000000) [0.000000|255.000000] "" Vector__XXX
 SG_ KN_LE2_DiagPfad  : 60|1@1+ (1.000000,0.000000) [0.000000|1.000000] "" ICAS1_Gateway
 SG_ LE2_KD_Fehler  : 63|1@1+ (1.000000,0.000000) [0.000000|1.000000] "" ICAS1_Gateway

BO_ 2549088374 KN_MO_01: 8 Motor_BEV
 SG_ Motor_KompSchutz  : 0|1@1+ (1.000000,0.000000) [0.000000|1.000000] "" Vector__XXX
 SG_ MO_01_Abschaltstufe  : 1|1@1+ (1.000000,0.000000) [0.000000|1.000000] "" Vector__XXX
 SG_ MO_01_Transport_Mode  : 2|1@1+ (1.000000,0.000000) [0.000000|1.000000] "" Vector__XXX
 SG_ Motor_Nachlauftyp  : 4|4@1+ (1.000000,0.000000) [0.000000|15.000000] "" ICAS1_Gateway
 SG_ KN_Motor_ECUKnockOutTimer  : 32|6@1+ (1.000000,0.000000) [0.000000|62.000000] "Unit_Minut" Vector__XXX
 SG_ KN_Motor_BusKnockOut  : 38|2@1+ (1.000000,0.000000) [0.000000|3.000000] "" Vector__XXX
 SG_ KN_Motor_BusKnockOutTimer  : 40|8@1+ (1.000000,0.000000) [0.000000|254.000000] "" Vector__XXX
 SG_ NM_MO_01_Wakeup  : 48|8@1+ (1.000000,0.000000) [0.000000|255.000000] "" Vector__XXX
 SG_ KN_Motor_ECUKnockOut  : 56|2@1+ (1.000000,0.000000) [0.000000|3.000000] "" Vector__XXX
 SG_ KN_MO_DiagPfad  : 60|1@1+ (1.000000,0.000000) [0.000000|1.000000] "" ICAS1_Gateway
 SG_ MO_KD_Fehler  : 63|1@1+ (1.000000,0.000000) [0.000000|1.000000] "" ICAS1_Gateway

BO_ 2621440277 KS_Airbag_01_Req_FD: 16 ICAS1_Gateway
 SG_ KS_Airbag_01_Req_FD_Data  : 0|128@1+ (1.000000,0.000000) [0.000000|340282366920938463463374607431768211456.000000] "" Airbag

BO_ 2621571349 KS_Airbag_01_Resp_FD: 16 Airbag
 SG_ KS_Airbag_01_Resp_FD_Data  : 0|128@1+ (1.000000,0.000000) [0.000000|340282366920938463463374607431768211456.000000] "" ICAS1_Gateway

BO_ 982 Licht_hinten_01: 8 ICAS1_Gateway
 SG_ Licht_hinten_01_BZ  : 0|4@1+ (1.000000,0.000000) [0.000000|15.000000] "" Vector__XXX
 SG_ LH_Aussenlicht_def  : 7|1@1+ (1.000000,0.000000) [0.000000|1.000000] "" Vector__XXX
 SG_ LH_Standlicht_H_aktiv  : 8|1@1+ (1.000000,0.000000) [0.000000|1.000000] "" Vector__XXX
 SG_ LH_Parklicht_HL_aktiv  : 9|1@1+ (1.000000,0.000000) [0.000000|1.000000] "" Vector__XXX
 SG_ LH_Parklicht_HR_aktiv  : 10|1@1+ (1.000000,0.000000) [0.000000|1.000000] "" Vector__XXX
 SG_ LH_Bremslicht_H_aktiv  : 11|1@1+ (1.000000,0.000000) [0.000000|1.000000] "" Vector__XXX
 SG_ LH_Nebelschluss_aktiv  : 12|1@1+ (1.000000,0.000000) [0.000000|1.000000] "" Vector__XXX
 SG_ LH_Rueckfahrlicht_aktiv  : 13|1@1+ (1.000000,0.000000) [0.000000|1.000000] "" Vector__XXX
 SG_ LH_Blinker_HL_akt  : 14|1@1+ (1.000000,0.000000) [0.000000|1.000000] "" Vector__XXX
 SG_ LH_Blinker_HR_akt  : 15|1@1+ (1.000000,0.000000) [0.000000|1.000000] "" Vector__XXX
 SG_ LH_Blinker_li_def  : 16|1@1+ (1.000000,0.000000) [0.000000|1.000000] "" Vector__XXX
 SG_ LH_Bremsl_li_def  : 17|1@1+ (1.000000,0.000000) [0.000000|1.000000] "" Vector__XXX
 SG_ LH_Schlusslicht_li_def  : 18|1@1+ (1.000000,0.000000) [0.000000|1.000000] "" Vector__XXX
 SG_ LH_Rueckf_li_def  : 19|1@1+ (1.000000,0.000000) [0.000000|1.000000] "" Vector__XXX
 SG_ LH_Nebel_li_def  : 20|1@1+ (1.000000,0.000000) [0.000000|1.000000] "" Vector__XXX
 SG_ LH_Schluss_Brems_Nebel_li_def  : 21|1@1+ (1.000000,0.000000) [0.000000|1.000000] "" Vector__XXX
 SG_ LH_Schluss_Brems_Nebel_re_def  : 22|1@1+ (1.000000,0.000000) [0.000000|1.000000] "" Vector__XXX
 SG_ LH_Zusatzschlussl_def  : 23|1@1+ (1.000000,0.000000) [0.000000|1.000000] "" Vector__XXX
 SG_ LH_Schluss_Brems_li_def  : 24|1@1+ (1.000000,0.000000) [0.000000|1.000000] "" Vector__XXX
 SG_ LH_Schluss_Nebel_li_def  : 25|1@1+ (1.000000,0.000000) [0.000000|1.000000] "" Vector__XXX
 SG_ LH_SL_BRL_BLK_li_def  : 26|1@1+ (1.000000,0.000000) [0.000000|1.000000] "" Vector__XXX
 SG_ LH_Brems_Blk_li_def  : 27|1@1+ (1.000000,0.000000) [0.000000|1.000000] "" Vector__XXX
 SG_ LH_Diag_Status_re_def  : 28|1@1+ (1.000000,0.000000) [0.000000|1.000000] "" Vector__XXX
 SG_ LH_Diag_Status_li_def  : 29|1@1+ (1.000000,0.000000) [0.000000|1.000000] "" Vector__XXX
 SG_ LH_Diag_LED_li_def  : 30|1@1+ (1.000000,0.000000) [0.000000|1.000000] "" Vector__XXX
 SG_ LH_Diag_LED_re_def  : 31|1@1+ (1.000000,0.000000) [0.000000|1.000000] "" Vector__XXX
 SG_ LH_Blinker_re_def  : 32|1@1+ (1.000000,0.000000) [0.000000|1.000000] "" Vector__XXX
 SG_ LH_Bremsl_re_def  : 33|1@1+ (1.000000,0.000000) [0.000000|1.000000] "" Vector__XXX
 SG_ LH_Schlusslicht_re_def  : 34|1@1+ (1.000000,0.000000) [0.000000|1.000000] "" Vector__XXX
 SG_ LH_Rueckf_re_def  : 35|1@1+ (1.000000,0.000000) [0.000000|1.000000] "" Vector__XXX
 SG_ LH_Nebel_re_def  : 36|1@1+ (1.000000,0.000000) [0.000000|1.000000] "" Vector__XXX
 SG_ LH_Schluss_Brems_mi_def  : 37|1@1+ (1.000000,0.000000) [0.000000|1.000000] "" Vector__XXX
 SG_ LH_Schluss_Brems_re_def  : 40|1@1+ (1.000000,0.000000) [0.000000|1.000000] "" Vector__XXX
 SG_ LH_Schluss_Nebel_re_def  : 41|1@1+ (1.000000,0.000000) [0.000000|1.000000] "" Vector__XXX
 SG_ LH_SL_BRL_BLK_re_def  : 42|1@1+ (1.000000,0.000000) [0.000000|1.000000] "" Vector__XXX
 SG_ LH_Brems_Blk_re_def  : 43|1@1+ (1.000000,0.000000) [0.000000|1.000000] "" Vector__XXX
 SG_ LH_Kennzl_def  : 48|1@1+ (1.000000,0.000000) [0.000000|1.000000] "" Vector__XXX
 SG_ LH_3_Bremsl_def  : 49|1@1+ (1.000000,0.000000) [0.000000|1.000000] "" Motor_BEV
 SG_ LH_Nebel_mi_def  : 50|1@1+ (1.000000,0.000000) [0.000000|1.000000] "" Vector__XXX
 SG_ LH_Rueckf_mi_def  : 51|1@1+ (1.000000,0.000000) [0.000000|1.000000] "" Vector__XXX
 SG_ LH_Schlusslicht_mi_def  : 52|1@1+ (1.000000,0.000000) [0.000000|1.000000] "" Vector__XXX
 SG_ LH_Bremsl_li_ges_def  : 54|1@1+ (1.000000,0.000000) [0.000000|1.000000] "" Motor_BEV
 SG_ LH_Bremsl_re_ges_def  : 55|1@1+ (1.000000,0.000000) [0.000000|1.000000] "" Motor_BEV
 SG_ LH_Bremsl_mi_def  : 61|1@1+ (1.000000,0.000000) [0.000000|1.000000] "" Vector__XXX
 SG_ BRL_als_SHL  : 62|1@1+ (1.000000,0.000000) [0.000000|1.000000] "" Vector__XXX

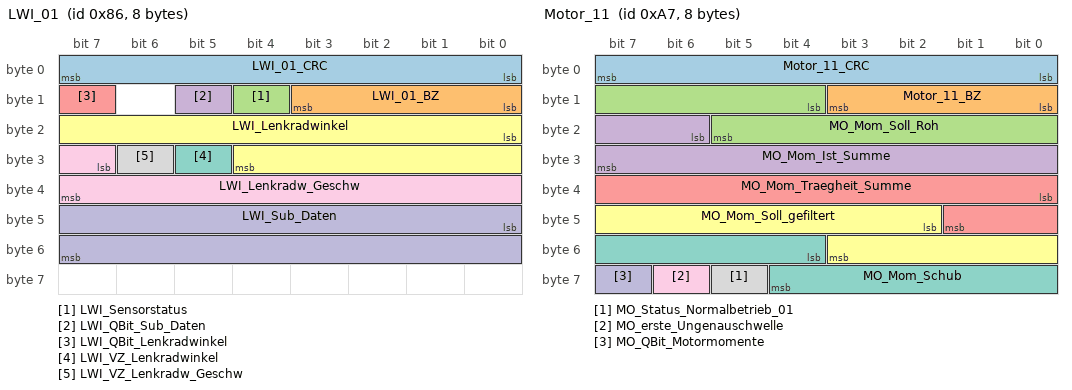
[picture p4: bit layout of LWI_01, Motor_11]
BO_ 134 LWI_01: 8 ICAS1_Gateway
 SG_ LWI_01_CRC  : 0|8@1+ (1.000000,0.000000) [0.000000|255.000000] "" Airbag Motor_BEV
 SG_ LWI_01_BZ  : 8|4@1+ (1.000000,0.000000) [0.000000|15.000000] "" Airbag Motor_BEV
 SG_ LWI_Sensorstatus  : 12|1@1+ (1.000000,0.000000) [0.000000|1.000000] "" Airbag Motor_BEV
 SG_ LWI_QBit_Sub_Daten  : 13|1@1+ (1.000000,0.000000) [0.000000|1.000000] "" Vector__XXX
 SG_ LWI_QBit_Lenkradwinkel  : 15|1@1+ (1.000000,0.000000) [0.000000|1.000000] "" Airbag Motor_BEV
 SG_ LWI_Lenkradwinkel  : 16|13@1+ (0.100000,0.000000) [0.000000|800.000000] "Unit_DegreOfArc" Airbag Motor_BEV
 SG_ LWI_VZ_Lenkradwinkel  : 29|1@1+ (1.000000,0.000000) [0.000000|1.000000] "" Airbag Motor_BEV
 SG_ LWI_VZ_Lenkradw_Geschw  : 30|1@1+ (1.000000,0.000000) [0.000000|1.000000] "" Vector__XXX
 SG_ LWI_Lenkradw_Geschw  : 31|9@1+ (5.000000,0.000000) [0.000000|2500.000000] "Unit_DegreOfArcPerSecon" Airbag
 SG_ LWI_Sub_Daten  : 40|16@1+ (1.000000,0.000000) [0.000000|65535.000000] "" Vector__XXX

BO_ 817 MFL_01: 8 ICAS1_Gateway
 SG_ MFL_Zaehler  : 0|4@1+ (1.000000,0.000000) [0.000000|15.000000] "" Vector__XXX
 SG_ MFL_Toggle  : 4|1@1+ (1.000000,0.000000) [0.000000|1.000000] "" Vector__XXX
 SG_ MFL_Lokalaktiv  : 5|1@1+ (1.000000,0.000000) [0.000000|1.000000] "" Vector__XXX
 SG_ MFL_M_Taste  : 6|1@1+ (1.000000,0.000000) [0.000000|1.000000] "" Vector__XXX
 SG_ MFL_Paddle_Verbau  : 7|1@1+ (1.000000,0.000000) [0.000000|1.000000] "" Vector__XXX
 SG_ MFL_Tastencode_1  : 8|8@1+ (1.000000,0.000000) [0.000000|255.000000] "" Vector__XXX
 SG_ MFL_Tastencode_2  : 16|8@1+ (1.000000,0.000000) [0.000000|255.000000] "" Vector__XXX
 SG_ MFL_Eventcode_1  : 24|4@1+ (1.000000,0.000000) [0.000000|15.000000] "" Vector__XXX
 SG_ MFL_Eventcode_2  : 28|4@1+ (1.000000,0.000000) [0.000000|15.000000] "" Vector__XXX
 SG_ MFL_Marke  : 32|4@1+ (1.000000,0.000000) [0.000000|15.000000] "" Vector__XXX
 SG_ MFL_Variante  : 36|4@1+ (1.000000,0.000000) [0.000000|15.000000] "" Vector__XXX
 SG_ MFL_Dummy_0_Signal_1  : 40|8@1+ (1.000000,0.000000) [0.000000|255.000000] "" Vector__XXX
 SG_ MFL_Tip_Down  : 48|1@1+ (1.000000,0.000000) [0.000000|1.000000] "" Motor_BEV
 SG_ MFL_Tip_Up  : 49|1@1+ (1.000000,0.000000) [0.000000|1.000000] "" Motor_BEV
 SG_ MFL_SatModul_links_Err  : 50|1@1+ (1.000000,0.000000) [0.000000|1.000000] "" Vector__XXX
 SG_ MFL_SatModul_rechts_Err  : 51|1@1+ (1.000000,0.000000) [0.000000|1.000000] "" Vector__XXX
 SG_ MFL_Dummy_0_Signal_2  : 52|1@1+ (1.000000,0.000000) [0.000000|1.000000] "" Vector__XXX
 SG_ MFL_Dummy_0_Signal_3  : 53|1@1+ (1.000000,0.000000) [0.000000|1.000000] "" Vector__XXX
 SG_ MFL_LR_HZG_Status  : 54|1@1+ (1.000000,0.000000) [0.000000|1.000000] "" Vector__XXX
 SG_ MFL_LR_HZG_Err  : 55|1@1+ (1.000000,0.000000) [0.000000|1.000000] "" Vector__XXX
 SG_ MFL_Signalhorn  : 56|1@1+ (1.000000,0.000000) [0.000000|1.000000] "" Vector__XXX
 SG_ MFL_Signalhorn_Err  : 57|1@1+ (1.000000,0.000000) [0.000000|1.000000] "" Vector__XXX
 SG_ MFL_Tip_links_Err  : 58|1@1+ (1.000000,0.000000) [0.000000|1.000000] "" Vector__XXX
 SG_ MFL_Tip_rechts_Err  : 59|1@1+ (1.000000,0.000000) [0.000000|1.000000] "" Vector__XXX
 SG_ MFL_Taste_links_Err  : 60|1@1+ (1.000000,0.000000) [0.000000|1.000000] "" Vector__XXX
 SG_ MFL_Taste_rechts_Err  : 61|1@1+ (1.000000,0.000000) [0.000000|1.000000] "" Vector__XXX
 SG_ MFL_ECU_Err  : 62|1@1+ (1.000000,0.000000) [0.000000|1.000000] "" Vector__XXX
 SG_ MFL_Response_Err  : 63|1@1+ (1.000000,0.000000) [0.000000|1.000000] "" Vector__XXX

BO_ 15 MO_SOPC: 1 Motor_BEV
 SG_ MO_SOPC  : 0|1@1+ (1.000000,0.000000) [0.000000|1.000000] "" Vector__XXX

BO_ 1600 Motor_07: 8 Motor_BEV
 SG_ MO_QBit_Ansaugluft_Temp  : 0|1@1+ (1.000000,0.000000) [0.000000|1.000000] "" Vector__XXX
 SG_ MO_QBit_Oel_Temp  : 1|1@1+ (1.000000,0.000000) [0.000000|1.000000] "" Vector__XXX
 SG_ MO_QBit_Kuehlmittel_Temp  : 2|1@1+ (1.000000,0.000000) [0.000000|1.000000] "" Vector__XXX
 SG_ MO_KL15_Abschaltempfehlung  : 3|1@1+ (1.000000,0.000000) [0.000000|1.000000] "" Vector__XXX
 SG_ MO_HYB_Fehler_HV_Netz  : 4|1@1+ (1.000000,0.000000) [0.000000|1.000000] "" Vector__XXX
 SG_ MO_aktives_Getriebeheizen  : 5|1@1+ (1.000000,0.000000) [0.000000|1.000000] "" Vector__XXX
 SG_ MO_Absperrventil_oeffnen  : 6|2@1+ (1.000000,0.000000) [0.000000|3.000000] "" Vector__XXX
 SG_ MO_Ansaugluft_Temp  : 8|8@1+ (0.750000,-48.000000) [-48.000000|141.750000] "Unit_DegreCelsi" Vector__XXX
 SG_ MO_Oel_Temp  : 16|8@1+ (1.000000,-60.000000) [-60.000000|192.000000] "Unit_DegreCelsi" Vector__XXX
 SG_ MO_Kuehlmittel_Temp  : 24|8@1+ (0.750000,-48.000000) [-48.000000|141.750000] "Unit_DegreCelsi" Vector__XXX
 SG_ MO_Hoeheninfo  : 32|8@1+ (0.007810,0.000000) [0.000000|1.983740] "" Vector__XXX
 SG_ MO_Kennfeldk  : 40|1@1+ (1.000000,0.000000) [0.000000|1.000000] "" Vector__XXX
 SG_ MO_Versionsinfo_02  : 41|5@1+ (1.000000,0.000000) [0.000000|31.000000] "" Vector__XXX
 SG_ MO_QBit_Hoeheninfo  : 46|1@1+ (1.000000,0.000000) [0.000000|1.000000] "" Vector__XXX
 SG_ MO_Getriebe_kuehlen  : 47|1@1+ (1.000000,0.000000) [0.000000|1.000000] "" Vector__XXX
 SG_ MO_Mom_Traegheit_02  : 48|5@1+ (0.010000,0.000000) [0.000000|0.310000] "Unit_KiloGramMeterSquar" Vector__XXX
 SG_ MO_Heizungspumpenansteuerung  : 53|4@1+ (10.000000,0.000000) [0.000000|100.000000] "Unit_PerCent" Vector__XXX
 SG_ MO_SpannungsAnf  : 57|1@1+ (1.000000,0.000000) [0.000000|1.000000] "" Vector__XXX
 SG_ MO_Nachlaufzeit_Heizungspumpe  : 58|6@1+ (15.000000,0.000000) [0.000000|945.000000] "Unit_Secon" Vector__XXX

BO_ 167 Motor_11: 8 Motor_BEV
 SG_ Motor_11_CRC  : 0|8@1+ (1.000000,0.000000) [0.000000|255.000000] "" ICAS1_Gateway
 SG_ Motor_11_BZ  : 8|4@1+ (1.000000,0.000000) [0.000000|15.000000] "" ICAS1_Gateway
 SG_ MO_Mom_Soll_Roh  : 12|10@1+ (1.000000,-509.000000) [-509.000000|509.000000] "" ICAS1_Gateway
 SG_ MO_Mom_Ist_Summe  : 22|10@1+ (1.000000,-509.000000) [-509.000000|509.000000] "" ICAS1_Gateway
 SG_ MO_Mom_Traegheit_Summe  : 32|10@1+ (1.000000,-509.000000) [-509.000000|509.000000] "" ICAS1_Gateway
 SG_ MO_Mom_Soll_gefiltert  : 42|10@1+ (1.000000,-509.000000) [-509.000000|509.000000] "" ICAS1_Gateway
 SG_ MO_Mom_Schub  : 52|9@1+ (1.000000,-509.000000) [-509.000000|0.000000] "" ICAS1_Gateway
 SG_ MO_Status_Normalbetrieb_01  : 61|1@1+ (1.000000,0.000000) [0.000000|1.000000] "" ICAS1_Gateway
 SG_ MO_erste_Ungenauschwelle  : 62|1@1+ (1.000000,0.000000) [0.000000|1.000000] "" ICAS1_Gateway
 SG_ MO_QBit_Motormomente  : 63|1@1+ (1.000000,0.000000) [0.000000|1.000000] "" ICAS1_Gateway

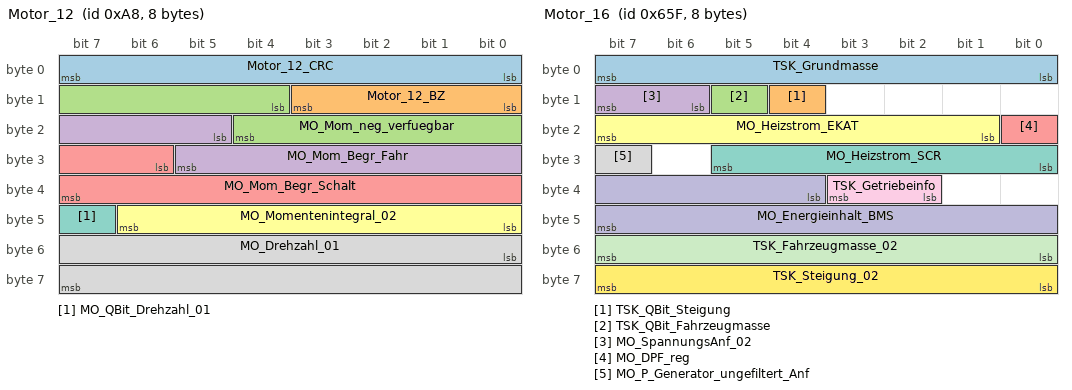
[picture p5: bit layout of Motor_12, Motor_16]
BO_ 168 Motor_12: 8 Motor_BEV
 SG_ Motor_12_CRC  : 0|8@1+ (1.000000,0.000000) [0.000000|255.000000] "" ICAS1_Gateway
 SG_ Motor_12_BZ  : 8|4@1+ (1.000000,0.000000) [0.000000|15.000000] "" ICAS1_Gateway
 SG_ MO_Mom_neg_verfuegbar  : 12|9@1+ (1.000000,-509.000000) [-509.000000|0.000000] "" ICAS1_Gateway
 SG_ MO_Mom_Begr_Fahr  : 21|9@1+ (1.000000,0.000000) [0.000000|509.000000] "" ICAS1_Gateway
 SG_ MO_Mom_Begr_Schalt  : 30|10@1+ (1.000000,-509.000000) [-509.000000|509.000000] "" ICAS1_Gateway
 SG_ MO_Momentenintegral_02  : 40|7@1+ (1.000000,0.000000) [0.000000|100.000000] "Unit_PerCent" ICAS1_Gateway
 SG_ MO_QBit_Drehzahl_01  : 47|1@1+ (1.000000,0.000000) [0.000000|1.000000] "" Airbag ICAS1_Gateway LE2
 SG_ MO_Drehzahl_01  : 48|16@1+ (0.250000,0.000000) [0.000000|16383.000000] "Unit_MinutInver" ICAS1_Gateway

BO_ 958 Motor_14: 8 Motor_BEV
 SG_ Motor_14_CRC  : 0|8@1+ (1.000000,0.000000) [0.000000|255.000000] "" ICAS1_Gateway
 SG_ Motor_14_BZ  : 8|4@1+ (1.000000,0.000000) [0.000000|15.000000] "" ICAS1_Gateway
 SG_ MO_StartStopp_Status  : 12|2@1+ (1.000000,0.000000) [0.000000|3.000000] "" ICAS1_Gateway
 SG_ MO_StartStopp_Wiederstart  : 14|1@1+ (1.000000,0.000000) [0.000000|1.000000] "" ICAS1_Gateway
 SG_ MO_StartStopp_Motorstopp  : 15|1@1+ (1.000000,0.000000) [0.000000|1.000000] "" ICAS1_Gateway
 SG_ MO_Freig_Reku  : 16|2@1+ (1.000000,0.000000) [0.000000|3.000000] "" ICAS1_Gateway
 SG_ MO_Kl_75  : 18|1@1+ (1.000000,0.000000) [0.000000|1.000000] "" ICAS1_Gateway
 SG_ MO_Kl_50  : 19|1@1+ (1.000000,0.000000) [0.000000|1.000000] "" ICAS1_Gateway
 SG_ MO_Gangposition  : 20|4@1+ (1.000000,0.000000) [0.000000|15.000000] "" ICAS1_Gateway
 SG_ MO_StartStopp_Fahrerwunsch  : 24|2@1+ (1.000000,0.000000) [0.000000|3.000000] "" ICAS1_Gateway
 SG_ MO_HYB_Fahrbereitschaft  : 26|1@1+ (1.000000,0.000000) [0.000000|1.000000] "" ICAS1_Gateway
 SG_ MO_Ext_E_Fahrt_aktiv  : 27|1@1+ (1.000000,0.000000) [0.000000|1.000000] "" ICAS1_Gateway
 SG_ MO_Fahrer_bremst  : 28|1@1+ (1.000000,0.000000) [0.000000|1.000000] "" Airbag ICAS1_Gateway
 SG_ MO_QBit_Fahrer_bremst  : 29|1@1+ (1.000000,0.000000) [0.000000|1.000000] "" Airbag ICAS1_Gateway
 SG_ MO_BLS  : 30|1@1+ (1.000000,0.000000) [0.000000|1.000000] "" Airbag ICAS1_Gateway
 SG_ MO_Konsistenz_Bremsped  : 31|1@1+ (1.000000,0.000000) [0.000000|1.000000] "" ICAS1_Gateway
 SG_ MO_Timeout_ESP  : 32|1@1+ (1.000000,0.000000) [0.000000|1.000000] "" ICAS1_Gateway
 SG_ MO_Klima_Eingr  : 33|2@1+ (1.000000,0.000000) [0.000000|3.000000] "" ICAS1_Gateway
 SG_ MO_Aussp_Anlass  : 35|1@1+ (1.000000,0.000000) [0.000000|1.000000] "" ICAS1_Gateway
 SG_ MO_Freig_Anlass  : 36|1@1+ (1.000000,0.000000) [0.000000|1.000000] "" ICAS1_Gateway
 SG_ MO_Kuppl_schalter  : 37|1@1+ (1.000000,0.000000) [0.000000|1.000000] "" ICAS1_Gateway
 SG_ MO_Interlock  : 38|1@1+ (1.000000,0.000000) [0.000000|1.000000] "" ICAS1_Gateway
 SG_ MO_Motor_laeuft  : 39|1@1+ (1.000000,0.000000) [0.000000|1.000000] "" ICAS1_Gateway
 SG_ MO_Kickdown  : 40|1@1+ (1.000000,0.000000) [0.000000|1.000000] "" ICAS1_Gateway ICAS1_KommunikationsServer
 SG_ MO_QBit_KL_75  : 41|1@1+ (1.000000,0.000000) [0.000000|1.000000] "" ICAS1_Gateway
 SG_ MO_EKlKomLeiRed  : 42|2@1+ (1.000000,0.000000) [0.000000|3.000000] "" ICAS1_Gateway
 SG_ MO_Handshake_STH  : 44|1@1+ (1.000000,0.000000) [0.000000|1.000000] "" ICAS1_Gateway
 SG_ MO_BKV_Unterdruckwarnung  : 45|1@1+ (1.000000,0.000000) [0.000000|1.000000] "" ICAS1_Gateway
 SG_ MO_Freigabe_Segeln  : 46|1@1+ (1.000000,0.000000) [0.000000|1.000000] "" ICAS1_Gateway
 SG_ MO_PTC_Status  : 47|3@1+ (1.000000,0.000000) [0.000000|7.000000] "" ICAS1_Gateway
 SG_ MO_QBit_Gangposition  : 50|1@1+ (1.000000,0.000000) [0.000000|1.000000] "" ICAS1_Gateway
 SG_ MO_Signalquelle_Gangposition  : 51|1@1+ (1.000000,0.000000) [0.000000|1.000000] "" ICAS1_Gateway
 SG_ MO_Remotestart_Betrieb  : 52|1@1+ (1.000000,0.000000) [0.000000|1.000000] "" ICAS1_Gateway
 SG_ MO_Remotestart_moeglich  : 53|1@1+ (1.000000,0.000000) [0.000000|1.000000] "" ICAS1_Gateway
 SG_ MO_FMAus_aktiv  : 55|1@1+ (1.000000,0.000000) [0.000000|1.000000] "" ICAS1_Gateway
 SG_ MO_FMAus_Startvariante  : 56|2@1+ (1.000000,0.000000) [0.000000|3.000000] "" ICAS1_Gateway
 SG_ MO_BMS_NV_Anf_stuetzen  : 58|1@1+ (1.000000,0.000000) [0.000000|1.000000] "" ICAS1_Gateway
 SG_ MO_Zylinderabschaltung  : 59|2@1+ (1.000000,0.000000) [0.000000|3.000000] "" ICAS1_Gateway
 SG_ MO_HYB_VM_aktiv  : 61|1@1+ (1.000000,0.000000) [0.000000|1.000000] "" ICAS1_Gateway
 SG_ MO_StartVorauss_erfuellt  : 62|2@1+ (1.000000,0.000000) [0.000000|3.000000] "" ICAS1_Gateway

BO_ 1631 Motor_16: 8 Motor_BEV
 SG_ TSK_Grundmasse  : 0|8@1+ (32.000000,0.000000) [0.000000|8128.000000] "Unit_KiloGram" ICAS1_Gateway
 SG_ TSK_QBit_Steigung  : 12|1@1+ (1.000000,0.000000) [0.000000|1.000000] "" ICAS1_Gateway
 SG_ TSK_QBit_Fahrzeugmasse  : 13|1@1+ (1.000000,0.000000) [0.000000|1.000000] "" ICAS1_Gateway
 SG_ MO_SpannungsAnf_02  : 14|2@1+ (1.000000,0.000000) [0.000000|3.000000] "" ICAS1_Gateway
 SG_ MO_DPF_reg  : 16|1@1+ (1.000000,0.000000) [0.000000|1.000000] "" ICAS1_Gateway
 SG_ MO_Heizstrom_EKAT  : 17|7@1+ (1.000000,0.000000) [0.000000|126.000000] "Unit_Amper" ICAS1_Gateway
 SG_ MO_Heizstrom_SCR  : 24|6@1+ (1.000000,0.000000) [0.000000|62.000000] "Unit_Amper" ICAS1_Gateway
 SG_ MO_P_Generator_ungefiltert_Anf  : 31|1@1+ (1.000000,0.000000) [0.000000|1.000000] "" ICAS1_Gateway
 SG_ TSK_Getriebeinfo  : 34|2@1+ (1.000000,0.000000) [0.000000|3.000000] "" ICAS1_Gateway
 SG_ MO_Energieinhalt_BMS  : 36|12@1+ (25.000000,0.000000) [0.000000|102325.000000] "Unit_WattHour" ICAS1_Gateway
 SG_ TSK_Fahrzeugmasse_02  : 48|8@1+ (32.000000,0.000000) [0.000000|8128.000000] "Unit_KiloGram" ICAS1_Gateway
 SG_ TSK_Steigung_02  : 56|8@1+ (0.800000,-101.600000) [-100.800000|101.600000] "Unit_PerCent" ICAS1_Gateway

BO_ 1648 Motor_18: 8 Motor_BEV
 SG_ MO_max_Ladedruck  : 0|6@1+ (0.100000,0.000000) [0.000000|6.300000] "Unit_Bar" ICAS1_Gateway
 SG_ MO_ANC_Kennfeld_Anf  : 6|2@1+ (1.000000,0.000000) [0.000000|3.000000] "" ICAS1_Gateway
 SG_ MO_Bremslicht_Reku  : 8|1@1+ (1.000000,0.000000) [0.000000|1.000000] "" ICAS1_Gateway
 SG_ MO_StartStopp_PopUp  : 9|2@1+ (1.000000,0.000000) [0.000000|3.000000] "" ICAS1_Gateway
 SG_ MO1_Sperr_Info_WFS  : 11|1@1+ (1.000000,0.000000) [0.000000|1.000000] "" ICAS1_Gateway
 SG_ MO1_Freigabe_Info_WFS  : 12|1@1+ (1.000000,0.000000) [0.000000|1.000000] "" ICAS1_Gateway
 SG_ MO_EPCL  : 13|3@1+ (1.000000,0.000000) [0.000000|7.000000] "" ICAS1_Gateway ICAS1_KommunikationsServer
 SG_ MO_Zylabsch_Texte_02  : 16|4@1+ (1.000000,0.000000) [0.000000|15.000000] "" ICAS1_Gateway
 SG_ MO_Fahrzeugtyp  : 20|3@1+ (1.000000,0.000000) [0.000000|7.000000] "" ICAS1_Gateway ICAS1_KommunikationsServer
 SG_ MO_NMAX_Schaltanzeige  : 23|9@1+ (25.000000,0.000000) [0.000000|12775.000000] "Unit_MinutInver" ICAS1_Gateway
 SG_ MO_Abstellzeit  : 32|8@1+ (8.000000,0.000000) [0.000000|2024.000000] "Unit_Minut" ICAS1_Gateway
 SG_ MO_Abstellzeit_Status  : 40|2@1+ (1.000000,0.000000) [0.000000|3.000000] "" ICAS1_Gateway
 SG_ MO1_Freigabe_Verfallsinfo_WFS  : 42|1@1+ (1.000000,0.000000) [0.000000|1.000000] "" ICAS1_Gateway
 SG_ MO_Hybrid_StartStopp_LED  : 43|2@1+ (1.000000,0.000000) [0.000000|3.000000] "" ICAS1_Gateway
 SG_ MO_Fehler_Zylabsch  : 45|2@1+ (1.000000,0.000000) [0.000000|3.000000] "" ICAS1_Gateway
 SG_ MO_Anzahl_Abgesch_Zyl  : 47|3@1+ (1.000000,0.000000) [0.000000|7.000000] "" ICAS1_Gateway
 SG_ MO_Zylabsch_Texte  : 50|2@1+ (1.000000,0.000000) [0.000000|3.000000] "" ICAS1_Gateway
 SG_ MO_Ethanol_BS_Texte  : 52|3@1+ (1.000000,0.000000) [0.000000|7.000000] "" ICAS1_Gateway
 SG_ MO_Drehzahl_Warnung  : 55|1@1+ (1.000000,0.000000) [0.000000|1.000000] "" ICAS1_Gateway
 SG_ MO_obere_Drehzahlgrenze  : 56|8@1+ (50.000000,0.000000) [50.000000|12750.000000] "Unit_MinutInver" ICAS1_Gateway

BU_:  Airbag BAP_Tester ICAS1_Gateway ICAS1_KommunikationsServer LE1 LE2 Motor_BEV Schaltbetaetigung

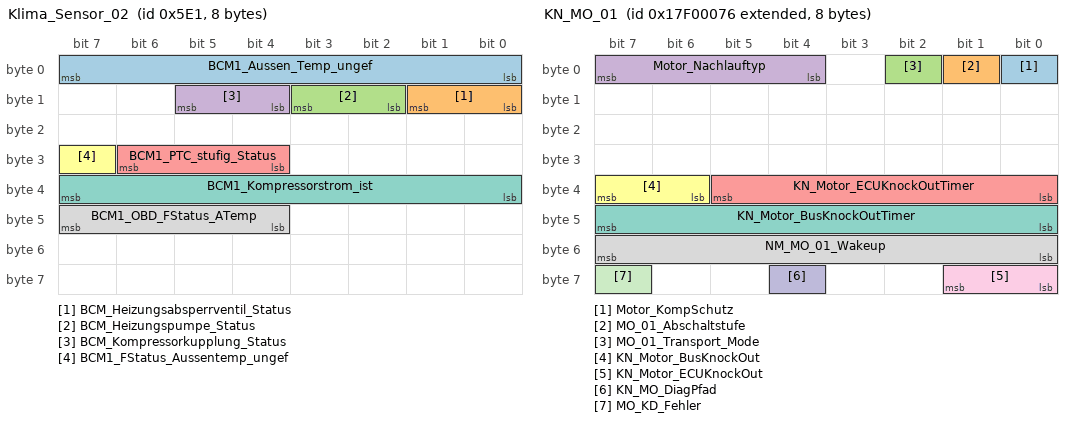
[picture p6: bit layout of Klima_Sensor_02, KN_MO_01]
BO_ 1505 Klima_Sensor_02: 8 ICAS1_Gateway
 SG_ BCM1_Aussen_Temp_ungef  : 0|8@1+ (0.500000,-50.000000) [-50.000000|76.000000] "Unit_DegreCelsi" LE1 LE2 Motor_BEV
 SG_ BCM_Heizungsabsperrventil_Status  : 8|2@1+ (1.000000,0.000000) [0.000000|3.000000] "" Vector__XXX
 SG_ BCM_Heizungspumpe_Status  : 10|2@1+ (1.000000,0.000000) [0.000000|3.000000] "" Vector__XXX
 SG_ BCM_Kompressorkupplung_Status  : 12|2@1+ (1.000000,0.000000) [0.000000|3.000000] "" Vector__XXX
 SG_ BCM1_PTC_stufig_Status  : 28|3@1+ (1.000000,0.000000) [0.000000|7.000000] "" Vector__XXX
 SG_ BCM1_FStatus_Aussentemp_ungef  : 31|1@1+ (1.000000,0.000000) [0.000000|1.000000] "" Vector__XXX
 SG_ BCM1_Kompressorstrom_ist  : 32|8@1+ (4.000000,0.000000) [0.000000|1000.000000] "Unit_MilliAmper" Vector__XXX
 SG_ BCM1_OBD_FStatus_ATemp  : 44|4@1+ (1.000000,0.000000) [0.000000|15.000000] "" Vector__XXX

BO_ 2549088277 KN_Airbag_01: 8 Airbag
 SG_ Airbag_01_KompSchutz  : 0|1@1+ (1.000000,0.000000) [0.000000|1.000000] "" Vector__XXX
 SG_ Airbag_01_Abschaltstufe  : 1|1@1+ (1.000000,0.000000) [0.000000|1.000000] "" Vector__XXX
 SG_ Airbag_01_Transport_Mode  : 2|1@1+ (1.000000,0.000000) [0.000000|1.000000] "" Vector__XXX
 SG_ Airbag_01_Nachlauftyp  : 4|4@1+ (1.000000,0.000000) [0.000000|15.000000] "" ICAS1_Gateway
 SG_ NM_Airbag_01_Wakeup  : 48|8@1+ (1.000000,0.000000) [0.000000|255.000000] "" Vector__XXX
 SG_ KN_AB_DiagPfad  : 60|1@1+ (1.000000,0.000000) [0.000000|1.000000] "" ICAS1_Gateway
 SG_ AB_KD_Fehler  : 63|1@1+ (1.000000,0.000000) [0.000000|1.000000] "" ICAS1_Gateway

BO_ 2549088380 KN_EMotor_01: 8 LE1
 SG_ EMotor_KompSchutz  : 0|1@1+ (1.000000,0.000000) [0.000000|1.000000] "" Vector__XXX
 SG_ EMotor_01_Abschaltstufe  : 1|1@1+ (1.000000,0.000000) [0.000000|1.000000] "" Vector__XXX
 SG_ EMotor_01_Transport_Mode  : 2|1@1+ (1.000000,0.000000) [0.000000|1.000000] "" Vector__XXX
 SG_ EMotor_Nachlauftyp  : 4|4@1+ (1.000000,0.000000) [0.000000|15.000000] "" ICAS1_Gateway
 SG_ NM_EMotor_01_Wakeup  : 48|8@1+ (1.000000,0.000000) [0.000000|255.000000] "" Vector__XXX
 SG_ KN_EM_HYB_DiagPfad  : 60|1@1+ (1.000000,0.000000) [0.000000|1.000000] "" ICAS1_Gateway
 SG_ EM_HYB_KD_Fehler  : 63|1@1+ (1.000000,0.000000) [0.000000|1.000000] "" ICAS1_Gateway

BO_ 2549088272 KN_Gateway: 8 ICAS1_Gateway
 SG_ Gateway_KompSchutz  : 0|1@1+ (1.000000,0.000000) [0.000000|1.000000] "" Vector__XXX
 SG_ Gateway_Abschaltstufe  : 1|1@1+ (1.000000,0.000000) [0.000000|1.000000] "" Vector__XXX
 SG_ Gateway_Transport_Mode  : 2|1@1+ (1.000000,0.000000) [0.000000|1.000000] "" Vector__XXX
 SG_ Gateway_Nachlauftyp  : 4|4@1+ (1.000000,0.000000) [0.000000|15.000000] "" Vector__XXX
 SG_ NM_Gateway_Wakeup  : 48|8@1+ (1.000000,0.000000) [0.000000|255.000000] "" Vector__XXX
 SG_ KN_GW_DiagPfad  : 60|1@1+ (1.000000,0.000000) [0.000000|1.000000] "" Vector__XXX
 SG_ GW_KD_Fehler  : 63|1@1+ (1.000000,0.000000) [0.000000|1.000000] "" Vector__XXX

BO_ 2549088440 KN_LE2: 8 LE2
 SG_ LE2_KompSchutz  : 0|1@1+ (1.000000,0.000000) [0.000000|1.000000] "" Vector__XXX
 SG_ LE2_Abschaltstufe  : 1|1@1+ (1.000000,0.000000) [0.000000|1.000000] "" Vector__XXX
 SG_ LE2_Transport_Mode  : 2|1@1+ (1.000000,0.000000) [0.000000|1.000000] "" Vector__XXX
 SG_ LE2_Nachlauftyp  : 4|4@1+ (1.000000,0.000000) [0.000000|15.000000] "" ICAS1_Gateway
 SG_ NM_LE2_Wakeup  : 48|8@1+ (1.000000,0.000000) [0.000000|255.000000] "" Vector__XXX
 SG_ KN_LE2_DiagPfad  : 60|1@1+ (1.000000,0.000000) [0.000000|1.000000] "" ICAS1_Gateway
 SG_ LE2_KD_Fehler  : 63|1@1+ (1.000000,0.000000) [0.000000|1.000000] "" ICAS1_Gateway

BO_ 2549088374 KN_MO_01: 8 Motor_BEV
 SG_ Motor_KompSchutz  : 0|1@1+ (1.000000,0.000000) [0.000000|1.000000] "" Vector__XXX
 SG_ MO_01_Abschaltstufe  : 1|1@1+ (1.000000,0.000000) [0.000000|1.000000] "" Vector__XXX
 SG_ MO_01_Transport_Mode  : 2|1@1+ (1.000000,0.000000) [0.000000|1.000000] "" Vector__XXX
 SG_ Motor_Nachlauftyp  : 4|4@1+ (1.000000,0.000000) [0.000000|15.000000] "" ICAS1_Gateway
 SG_ KN_Motor_ECUKnockOutTimer  : 32|6@1+ (1.000000,0.000000) [0.000000|62.000000] "Unit_Minut" Vector__XXX
 SG_ KN_Motor_BusKnockOut  : 38|2@1+ (1.000000,0.000000) [0.000000|3.000000] "" Vector__XXX
 SG_ KN_Motor_BusKnockOutTimer  : 40|8@1+ (1.000000,0.000000) [0.000000|254.000000] "" Vector__XXX
 SG_ NM_MO_01_Wakeup  : 48|8@1+ (1.000000,0.000000) [0.000000|255.000000] "" Vector__XXX
 SG_ KN_Motor_ECUKnockOut  : 56|2@1+ (1.000000,0.000000) [0.000000|3.000000] "" Vector__XXX
 SG_ KN_MO_DiagPfad  : 60|1@1+ (1.000000,0.000000) [0.000000|1.000000] "" ICAS1_Gateway
 SG_ MO_KD_Fehler  : 63|1@1+ (1.000000,0.000000) [0.000000|1.000000] "" ICAS1_Gateway

BO_ 2621440277 KS_Airbag_01_Req_FD: 16 ICAS1_Gateway
 SG_ KS_Airbag_01_Req_FD_Data  : 0|128@1+ (1.000000,0.000000) [0.000000|340282366920938463463374607431768211456.000000] "" Airbag

BO_ 2621571349 KS_Airbag_01_Resp_FD: 16 Airbag
 SG_ KS_Airbag_01_Resp_FD_Data  : 0|128@1+ (1.000000,0.000000) [0.000000|340282366920938463463374607431768211456.000000] "" ICAS1_Gateway

BO_ 982 Licht_hinten_01: 8 ICAS1_Gateway
 SG_ Licht_hinten_01_BZ  : 0|4@1+ (1.000000,0.000000) [0.000000|15.000000] "" Vector__XXX
 SG_ LH_Aussenlicht_def  : 7|1@1+ (1.000000,0.000000) [0.000000|1.000000] "" Vector__XXX
 SG_ LH_Standlicht_H_aktiv  : 8|1@1+ (1.000000,0.000000) [0.000000|1.000000] "" Vector__XXX
 SG_ LH_Parklicht_HL_aktiv  : 9|1@1+ (1.000000,0.000000) [0.000000|1.000000] "" Vector__XXX
 SG_ LH_Parklicht_HR_aktiv  : 10|1@1+ (1.000000,0.000000) [0.000000|1.000000] "" Vector__XXX
 SG_ LH_Bremslicht_H_aktiv  : 11|1@1+ (1.000000,0.000000) [0.000000|1.000000] "" Vector__XXX
 SG_ LH_Nebelschluss_aktiv  : 12|1@1+ (1.000000,0.000000) [0.000000|1.000000] "" Vector__XXX
 SG_ LH_Rueckfahrlicht_aktiv  : 13|1@1+ (1.000000,0.000000) [0.000000|1.000000] "" Vector__XXX
 SG_ LH_Blinker_HL_akt  : 14|1@1+ (1.000000,0.000000) [0.000000|1.000000] "" Vector__XXX
 SG_ LH_Blinker_HR_akt  : 15|1@1+ (1.000000,0.000000) [0.000000|1.000000] "" Vector__XXX
 SG_ LH_Blinker_li_def  : 16|1@1+ (1.000000,0.000000) [0.000000|1.000000] "" Vector__XXX
 SG_ LH_Bremsl_li_def  : 17|1@1+ (1.000000,0.000000) [0.000000|1.000000] "" Vector__XXX
 SG_ LH_Schlusslicht_li_def  : 18|1@1+ (1.000000,0.000000) [0.000000|1.000000] "" Vector__XXX
 SG_ LH_Rueckf_li_def  : 19|1@1+ (1.000000,0.000000) [0.000000|1.000000] "" Vector__XXX
 SG_ LH_Nebel_li_def  : 20|1@1+ (1.000000,0.000000) [0.000000|1.000000] "" Vector__XXX
 SG_ LH_Schluss_Brems_Nebel_li_def  : 21|1@1+ (1.000000,0.000000) [0.000000|1.000000] "" Vector__XXX
 SG_ LH_Schluss_Brems_Nebel_re_def  : 22|1@1+ (1.000000,0.000000) [0.000000|1.000000] "" Vector__XXX
 SG_ LH_Zusatzschlussl_def  : 23|1@1+ (1.000000,0.000000) [0.000000|1.000000] "" Vector__XXX
 SG_ LH_Schluss_Brems_li_def  : 24|1@1+ (1.000000,0.000000) [0.000000|1.000000] "" Vector__XXX
 SG_ LH_Schluss_Nebel_li_def  : 25|1@1+ (1.000000,0.000000) [0.000000|1.000000] "" Vector__XXX
 SG_ LH_SL_BRL_BLK_li_def  : 26|1@1+ (1.000000,0.000000) [0.000000|1.000000] "" Vector__XXX
 SG_ LH_Brems_Blk_li_def  : 27|1@1+ (1.000000,0.000000) [0.000000|1.000000] "" Vector__XXX
 SG_ LH_Diag_Status_re_def  : 28|1@1+ (1.000000,0.000000) [0.000000|1.000000] "" Vector__XXX
 SG_ LH_Diag_Status_li_def  : 29|1@1+ (1.000000,0.000000) [0.000000|1.000000] "" Vector__XXX
 SG_ LH_Diag_LED_li_def  : 30|1@1+ (1.000000,0.000000) [0.000000|1.000000] "" Vector__XXX
 SG_ LH_Diag_LED_re_def  : 31|1@1+ (1.000000,0.000000) [0.000000|1.000000] "" Vector__XXX
 SG_ LH_Blinker_re_def  : 32|1@1+ (1.000000,0.000000) [0.000000|1.000000] "" Vector__XXX
 SG_ LH_Bremsl_re_def  : 33|1@1+ (1.000000,0.000000) [0.000000|1.000000] "" Vector__XXX
 SG_ LH_Schlusslicht_re_def  : 34|1@1+ (1.000000,0.000000) [0.000000|1.000000] "" Vector__XXX
 SG_ LH_Rueckf_re_def  : 35|1@1+ (1.000000,0.000000) [0.000000|1.000000] "" Vector__XXX
 SG_ LH_Nebel_re_def  : 36|1@1+ (1.000000,0.000000) [0.000000|1.000000] "" Vector__XXX
 SG_ LH_Schluss_Brems_mi_def  : 37|1@1+ (1.000000,0.000000) [0.000000|1.000000] "" Vector__XXX
 SG_ LH_Schluss_Brems_re_def  : 40|1@1+ (1.000000,0.000000) [0.000000|1.000000] "" Vector__XXX
 SG_ LH_Schluss_Nebel_re_def  : 41|1@1+ (1.000000,0.000000) [0.000000|1.000000] "" Vector__XXX
 SG_ LH_SL_BRL_BLK_re_def  : 42|1@1+ (1.000000,0.000000) [0.000000|1.000000] "" Vector__XXX
 SG_ LH_Brems_Blk_re_def  : 43|1@1+ (1.000000,0.000000) [0.000000|1.000000] "" Vector__XXX
 SG_ LH_Kennzl_def  : 48|1@1+ (1.000000,0.000000) [0.000000|1.000000] "" Vector__XXX
 SG_ LH_3_Bremsl_def  : 49|1@1+ (1.000000,0.000000) [0.000000|1.000000] "" Motor_BEV
 SG_ LH_Nebel_mi_def  : 50|1@1+ (1.000000,0.000000) [0.000000|1.000000] "" Vector__XXX
 SG_ LH_Rueckf_mi_def  : 51|1@1+ (1.000000,0.000000) [0.000000|1.000000] "" Vector__XXX
 SG_ LH_Schlusslicht_mi_def  : 52|1@1+ (1.000000,0.000000) [0.000000|1.000000] "" Vector__XXX
 SG_ LH_Bremsl_li_ges_def  : 54|1@1+ (1.000000,0.000000) [0.000000|1.000000] "" Motor_BEV
 SG_ LH_Bremsl_re_ges_def  : 55|1@1+ (1.000000,0.000000) [0.000000|1.000000] "" Motor_BEV
 SG_ LH_Bremsl_mi_def  : 61|1@1+ (1.000000,0.000000) [0.000000|1.000000] "" Vector__XXX
 SG_ BRL_als_SHL  : 62|1@1+ (1.000000,0.000000) [0.000000|1.000000] "" Vector__XXX

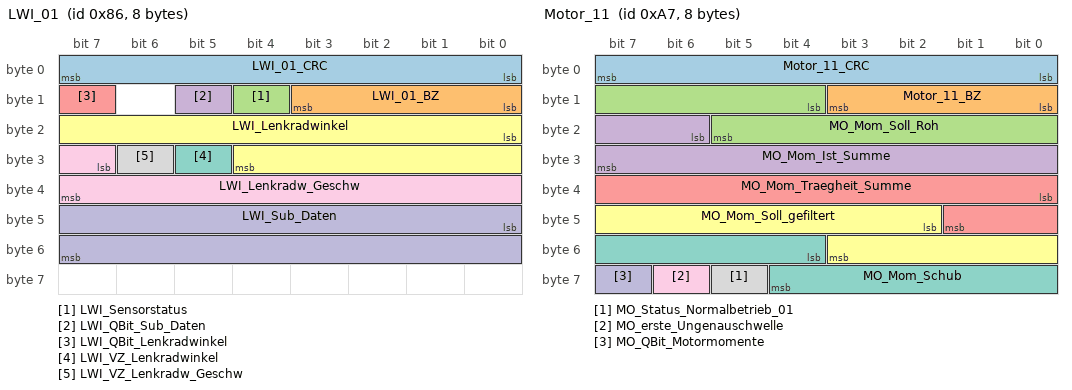
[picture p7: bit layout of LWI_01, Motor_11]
BO_ 134 LWI_01: 8 ICAS1_Gateway
 SG_ LWI_01_CRC  : 0|8@1+ (1.000000,0.000000) [0.000000|255.000000] "" Airbag Motor_BEV
 SG_ LWI_01_BZ  : 8|4@1+ (1.000000,0.000000) [0.000000|15.000000] "" Airbag Motor_BEV
 SG_ LWI_Sensorstatus  : 12|1@1+ (1.000000,0.000000) [0.000000|1.000000] "" Airbag Motor_BEV
 SG_ LWI_QBit_Sub_Daten  : 13|1@1+ (1.000000,0.000000) [0.000000|1.000000] "" Vector__XXX
 SG_ LWI_QBit_Lenkradwinkel  : 15|1@1+ (1.000000,0.000000) [0.000000|1.000000] "" Airbag Motor_BEV
 SG_ LWI_Lenkradwinkel  : 16|13@1+ (0.100000,0.000000) [0.000000|800.000000] "Unit_DegreOfArc" Airbag Motor_BEV
 SG_ LWI_VZ_Lenkradwinkel  : 29|1@1+ (1.000000,0.000000) [0.000000|1.000000] "" Airbag Motor_BEV
 SG_ LWI_VZ_Lenkradw_Geschw  : 30|1@1+ (1.000000,0.000000) [0.000000|1.000000] "" Vector__XXX
 SG_ LWI_Lenkradw_Geschw  : 31|9@1+ (5.000000,0.000000) [0.000000|2500.000000] "Unit_DegreOfArcPerSecon" Airbag
 SG_ LWI_Sub_Daten  : 40|16@1+ (1.000000,0.000000) [0.000000|65535.000000] "" Vector__XXX

BO_ 817 MFL_01: 8 ICAS1_Gateway
 SG_ MFL_Zaehler  : 0|4@1+ (1.000000,0.000000) [0.000000|15.000000] "" Vector__XXX
 SG_ MFL_Toggle  : 4|1@1+ (1.000000,0.000000) [0.000000|1.000000] "" Vector__XXX
 SG_ MFL_Lokalaktiv  : 5|1@1+ (1.000000,0.000000) [0.000000|1.000000] "" Vector__XXX
 SG_ MFL_M_Taste  : 6|1@1+ (1.000000,0.000000) [0.000000|1.000000] "" Vector__XXX
 SG_ MFL_Paddle_Verbau  : 7|1@1+ (1.000000,0.000000) [0.000000|1.000000] "" Vector__XXX
 SG_ MFL_Tastencode_1  : 8|8@1+ (1.000000,0.000000) [0.000000|255.000000] "" Vector__XXX
 SG_ MFL_Tastencode_2  : 16|8@1+ (1.000000,0.000000) [0.000000|255.000000] "" Vector__XXX
 SG_ MFL_Eventcode_1  : 24|4@1+ (1.000000,0.000000) [0.000000|15.000000] "" Vector__XXX
 SG_ MFL_Eventcode_2  : 28|4@1+ (1.000000,0.000000) [0.000000|15.000000] "" Vector__XXX
 SG_ MFL_Marke  : 32|4@1+ (1.000000,0.000000) [0.000000|15.000000] "" Vector__XXX
 SG_ MFL_Variante  : 36|4@1+ (1.000000,0.000000) [0.000000|15.000000] "" Vector__XXX
 SG_ MFL_Dummy_0_Signal_1  : 40|8@1+ (1.000000,0.000000) [0.000000|255.000000] "" Vector__XXX
 SG_ MFL_Tip_Down  : 48|1@1+ (1.000000,0.000000) [0.000000|1.000000] "" Motor_BEV
 SG_ MFL_Tip_Up  : 49|1@1+ (1.000000,0.000000) [0.000000|1.000000] "" Motor_BEV
 SG_ MFL_SatModul_links_Err  : 50|1@1+ (1.000000,0.000000) [0.000000|1.000000] "" Vector__XXX
 SG_ MFL_SatModul_rechts_Err  : 51|1@1+ (1.000000,0.000000) [0.000000|1.000000] "" Vector__XXX
 SG_ MFL_Dummy_0_Signal_2  : 52|1@1+ (1.000000,0.000000) [0.000000|1.000000] "" Vector__XXX
 SG_ MFL_Dummy_0_Signal_3  : 53|1@1+ (1.000000,0.000000) [0.000000|1.000000] "" Vector__XXX
 SG_ MFL_LR_HZG_Status  : 54|1@1+ (1.000000,0.000000) [0.000000|1.000000] "" Vector__XXX
 SG_ MFL_LR_HZG_Err  : 55|1@1+ (1.000000,0.000000) [0.000000|1.000000] "" Vector__XXX
 SG_ MFL_Signalhorn  : 56|1@1+ (1.000000,0.000000) [0.000000|1.000000] "" Vector__XXX
 SG_ MFL_Signalhorn_Err  : 57|1@1+ (1.000000,0.000000) [0.000000|1.000000] "" Vector__XXX
 SG_ MFL_Tip_links_Err  : 58|1@1+ (1.000000,0.000000) [0.000000|1.000000] "" Vector__XXX
 SG_ MFL_Tip_rechts_Err  : 59|1@1+ (1.000000,0.000000) [0.000000|1.000000] "" Vector__XXX
 SG_ MFL_Taste_links_Err  : 60|1@1+ (1.000000,0.000000) [0.000000|1.000000] "" Vector__XXX
 SG_ MFL_Taste_rechts_Err  : 61|1@1+ (1.000000,0.000000) [0.000000|1.000000] "" Vector__XXX
 SG_ MFL_ECU_Err  : 62|1@1+ (1.000000,0.000000) [0.000000|1.000000] "" Vector__XXX
 SG_ MFL_Response_Err  : 63|1@1+ (1.000000,0.000000) [0.000000|1.000000] "" Vector__XXX

BO_ 15 MO_SOPC: 1 Motor_BEV
 SG_ MO_SOPC  : 0|1@1+ (1.000000,0.000000) [0.000000|1.000000] "" Vector__XXX

BO_ 1600 Motor_07: 8 Motor_BEV
 SG_ MO_QBit_Ansaugluft_Temp  : 0|1@1+ (1.000000,0.000000) [0.000000|1.000000] "" Vector__XXX
 SG_ MO_QBit_Oel_Temp  : 1|1@1+ (1.000000,0.000000) [0.000000|1.000000] "" Vector__XXX
 SG_ MO_QBit_Kuehlmittel_Temp  : 2|1@1+ (1.000000,0.000000) [0.000000|1.000000] "" Vector__XXX
 SG_ MO_KL15_Abschaltempfehlung  : 3|1@1+ (1.000000,0.000000) [0.000000|1.000000] "" Vector__XXX
 SG_ MO_HYB_Fehler_HV_Netz  : 4|1@1+ (1.000000,0.000000) [0.000000|1.000000] "" Vector__XXX
 SG_ MO_aktives_Getriebeheizen  : 5|1@1+ (1.000000,0.000000) [0.000000|1.000000] "" Vector__XXX
 SG_ MO_Absperrventil_oeffnen  : 6|2@1+ (1.000000,0.000000) [0.000000|3.000000] "" Vector__XXX
 SG_ MO_Ansaugluft_Temp  : 8|8@1+ (0.750000,-48.000000) [-48.000000|141.750000] "Unit_DegreCelsi" Vector__XXX
 SG_ MO_Oel_Temp  : 16|8@1+ (1.000000,-60.000000) [-60.000000|192.000000] "Unit_DegreCelsi" Vector__XXX
 SG_ MO_Kuehlmittel_Temp  : 24|8@1+ (0.750000,-48.000000) [-48.000000|141.750000] "Unit_DegreCelsi" Vector__XXX
 SG_ MO_Hoeheninfo  : 32|8@1+ (0.007810,0.000000) [0.000000|1.983740] "" Vector__XXX
 SG_ MO_Kennfeldk  : 40|1@1+ (1.000000,0.000000) [0.000000|1.000000] "" Vector__XXX
 SG_ MO_Versionsinfo_02  : 41|5@1+ (1.000000,0.000000) [0.000000|31.000000] "" Vector__XXX
 SG_ MO_QBit_Hoeheninfo  : 46|1@1+ (1.000000,0.000000) [0.000000|1.000000] "" Vector__XXX
 SG_ MO_Getriebe_kuehlen  : 47|1@1+ (1.000000,0.000000) [0.000000|1.000000] "" Vector__XXX
 SG_ MO_Mom_Traegheit_02  : 48|5@1+ (0.010000,0.000000) [0.000000|0.310000] "Unit_KiloGramMeterSquar" Vector__XXX
 SG_ MO_Heizungspumpenansteuerung  : 53|4@1+ (10.000000,0.000000) [0.000000|100.000000] "Unit_PerCent" Vector__XXX
 SG_ MO_SpannungsAnf  : 57|1@1+ (1.000000,0.000000) [0.000000|1.000000] "" Vector__XXX
 SG_ MO_Nachlaufzeit_Heizungspumpe  : 58|6@1+ (15.000000,0.000000) [0.000000|945.000000] "Unit_Secon" Vector__XXX

BO_ 167 Motor_11: 8 Motor_BEV
 SG_ Motor_11_CRC  : 0|8@1+ (1.000000,0.000000) [0.000000|255.000000] "" ICAS1_Gateway
 SG_ Motor_11_BZ  : 8|4@1+ (1.000000,0.000000) [0.000000|15.000000] "" ICAS1_Gateway
 SG_ MO_Mom_Soll_Roh  : 12|10@1+ (1.000000,-509.000000) [-509.000000|509.000000] "" ICAS1_Gateway
 SG_ MO_Mom_Ist_Summe  : 22|10@1+ (1.000000,-509.000000) [-509.000000|509.000000] "" ICAS1_Gateway
 SG_ MO_Mom_Traegheit_Summe  : 32|10@1+ (1.000000,-509.000000) [-509.000000|509.000000] "" ICAS1_Gateway
 SG_ MO_Mom_Soll_gefiltert  : 42|10@1+ (1.000000,-509.000000) [-509.000000|509.000000] "" ICAS1_Gateway
 SG_ MO_Mom_Schub  : 52|9@1+ (1.000000,-509.000000) [-509.000000|0.000000] "" ICAS1_Gateway
 SG_ MO_Status_Normalbetrieb_01  : 61|1@1+ (1.000000,0.000000) [0.000000|1.000000] "" ICAS1_Gateway
 SG_ MO_erste_Ungenauschwelle  : 62|1@1+ (1.000000,0.000000) [0.000000|1.000000] "" ICAS1_Gateway
 SG_ MO_QBit_Motormomente  : 63|1@1+ (1.000000,0.000000) [0.000000|1.000000] "" ICAS1_Gateway

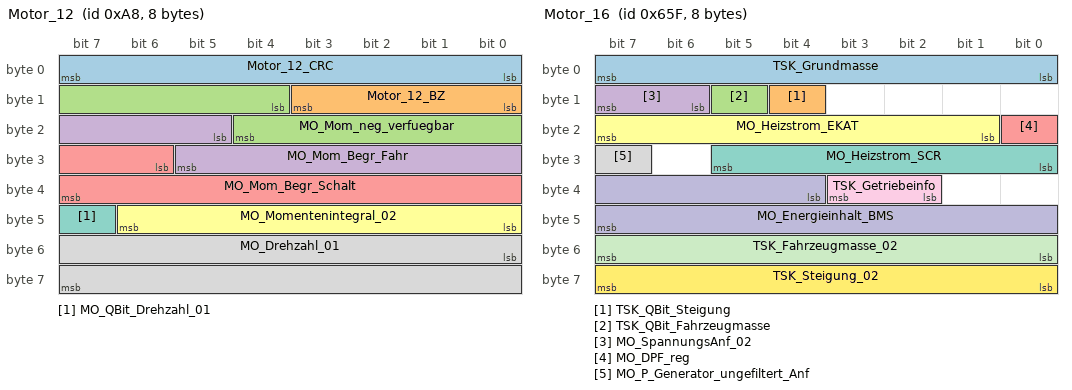
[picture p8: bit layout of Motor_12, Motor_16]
BO_ 168 Motor_12: 8 Motor_BEV
 SG_ Motor_12_CRC  : 0|8@1+ (1.000000,0.000000) [0.000000|255.000000] "" ICAS1_Gateway
 SG_ Motor_12_BZ  : 8|4@1+ (1.000000,0.000000) [0.000000|15.000000] "" ICAS1_Gateway
 SG_ MO_Mom_neg_verfuegbar  : 12|9@1+ (1.000000,-509.000000) [-509.000000|0.000000] "" ICAS1_Gateway
 SG_ MO_Mom_Begr_Fahr  : 21|9@1+ (1.000000,0.000000) [0.000000|509.000000] "" ICAS1_Gateway
 SG_ MO_Mom_Begr_Schalt  : 30|10@1+ (1.000000,-509.000000) [-509.000000|509.000000] "" ICAS1_Gateway
 SG_ MO_Momentenintegral_02  : 40|7@1+ (1.000000,0.000000) [0.000000|100.000000] "Unit_PerCent" ICAS1_Gateway
 SG_ MO_QBit_Drehzahl_01  : 47|1@1+ (1.000000,0.000000) [0.000000|1.000000] "" Airbag ICAS1_Gateway LE2
 SG_ MO_Drehzahl_01  : 48|16@1+ (0.250000,0.000000) [0.000000|16383.000000] "Unit_MinutInver" ICAS1_Gateway

BO_ 958 Motor_14: 8 Motor_BEV
 SG_ Motor_14_CRC  : 0|8@1+ (1.000000,0.000000) [0.000000|255.000000] "" ICAS1_Gateway
 SG_ Motor_14_BZ  : 8|4@1+ (1.000000,0.000000) [0.000000|15.000000] "" ICAS1_Gateway
 SG_ MO_StartStopp_Status  : 12|2@1+ (1.000000,0.000000) [0.000000|3.000000] "" ICAS1_Gateway
 SG_ MO_StartStopp_Wiederstart  : 14|1@1+ (1.000000,0.000000) [0.000000|1.000000] "" ICAS1_Gateway
 SG_ MO_StartStopp_Motorstopp  : 15|1@1+ (1.000000,0.000000) [0.000000|1.000000] "" ICAS1_Gateway
 SG_ MO_Freig_Reku  : 16|2@1+ (1.000000,0.000000) [0.000000|3.000000] "" ICAS1_Gateway
 SG_ MO_Kl_75  : 18|1@1+ (1.000000,0.000000) [0.000000|1.000000] "" ICAS1_Gateway
 SG_ MO_Kl_50  : 19|1@1+ (1.000000,0.000000) [0.000000|1.000000] "" ICAS1_Gateway
 SG_ MO_Gangposition  : 20|4@1+ (1.000000,0.000000) [0.000000|15.000000] "" ICAS1_Gateway
 SG_ MO_StartStopp_Fahrerwunsch  : 24|2@1+ (1.000000,0.000000) [0.000000|3.000000] "" ICAS1_Gateway
 SG_ MO_HYB_Fahrbereitschaft  : 26|1@1+ (1.000000,0.000000) [0.000000|1.000000] "" ICAS1_Gateway
 SG_ MO_Ext_E_Fahrt_aktiv  : 27|1@1+ (1.000000,0.000000) [0.000000|1.000000] "" ICAS1_Gateway
 SG_ MO_Fahrer_bremst  : 28|1@1+ (1.000000,0.000000) [0.000000|1.000000] "" Airbag ICAS1_Gateway
 SG_ MO_QBit_Fahrer_bremst  : 29|1@1+ (1.000000,0.000000) [0.000000|1.000000] "" Airbag ICAS1_Gateway
 SG_ MO_BLS  : 30|1@1+ (1.000000,0.000000) [0.000000|1.000000] "" Airbag ICAS1_Gateway
 SG_ MO_Konsistenz_Bremsped  : 31|1@1+ (1.000000,0.000000) [0.000000|1.000000] "" ICAS1_Gateway
 SG_ MO_Timeout_ESP  : 32|1@1+ (1.000000,0.000000) [0.000000|1.000000] "" ICAS1_Gateway
 SG_ MO_Klima_Eingr  : 33|2@1+ (1.000000,0.000000) [0.000000|3.000000] "" ICAS1_Gateway
 SG_ MO_Aussp_Anlass  : 35|1@1+ (1.000000,0.000000) [0.000000|1.000000] "" ICAS1_Gateway
 SG_ MO_Freig_Anlass  : 36|1@1+ (1.000000,0.000000) [0.000000|1.000000] "" ICAS1_Gateway
 SG_ MO_Kuppl_schalter  : 37|1@1+ (1.000000,0.000000) [0.000000|1.000000] "" ICAS1_Gateway
 SG_ MO_Interlock  : 38|1@1+ (1.000000,0.000000) [0.000000|1.000000] "" ICAS1_Gateway
 SG_ MO_Motor_laeuft  : 39|1@1+ (1.000000,0.000000) [0.000000|1.000000] "" ICAS1_Gateway
 SG_ MO_Kickdown  : 40|1@1+ (1.000000,0.000000) [0.000000|1.000000] "" ICAS1_Gateway ICAS1_KommunikationsServer
 SG_ MO_QBit_KL_75  : 41|1@1+ (1.000000,0.000000) [0.000000|1.000000] "" ICAS1_Gateway
 SG_ MO_EKlKomLeiRed  : 42|2@1+ (1.000000,0.000000) [0.000000|3.000000] "" ICAS1_Gateway
 SG_ MO_Handshake_STH  : 44|1@1+ (1.000000,0.000000) [0.000000|1.000000] "" ICAS1_Gateway
 SG_ MO_BKV_Unterdruckwarnung  : 45|1@1+ (1.000000,0.000000) [0.000000|1.000000] "" ICAS1_Gateway
 SG_ MO_Freigabe_Segeln  : 46|1@1+ (1.000000,0.000000) [0.000000|1.000000] "" ICAS1_Gateway
 SG_ MO_PTC_Status  : 47|3@1+ (1.000000,0.000000) [0.000000|7.000000] "" ICAS1_Gateway
 SG_ MO_QBit_Gangposition  : 50|1@1+ (1.000000,0.000000) [0.000000|1.000000] "" ICAS1_Gateway
 SG_ MO_Signalquelle_Gangposition  : 51|1@1+ (1.000000,0.000000) [0.000000|1.000000] "" ICAS1_Gateway
 SG_ MO_Remotestart_Betrieb  : 52|1@1+ (1.000000,0.000000) [0.000000|1.000000] "" ICAS1_Gateway
 SG_ MO_Remotestart_moeglich  : 53|1@1+ (1.000000,0.000000) [0.000000|1.000000] "" ICAS1_Gateway
 SG_ MO_FMAus_aktiv  : 55|1@1+ (1.000000,0.000000) [0.000000|1.000000] "" ICAS1_Gateway
 SG_ MO_FMAus_Startvariante  : 56|2@1+ (1.000000,0.000000) [0.000000|3.000000] "" ICAS1_Gateway
 SG_ MO_BMS_NV_Anf_stuetzen  : 58|1@1+ (1.000000,0.000000) [0.000000|1.000000] "" ICAS1_Gateway
 SG_ MO_Zylinderabschaltung  : 59|2@1+ (1.000000,0.000000) [0.000000|3.000000] "" ICAS1_Gateway
 SG_ MO_HYB_VM_aktiv  : 61|1@1+ (1.000000,0.000000) [0.000000|1.000000] "" ICAS1_Gateway
 SG_ MO_StartVorauss_erfuellt  : 62|2@1+ (1.000000,0.000000) [0.000000|3.000000] "" ICAS1_Gateway

BO_ 1631 Motor_16: 8 Motor_BEV
 SG_ TSK_Grundmasse  : 0|8@1+ (32.000000,0.000000) [0.000000|8128.000000] "Unit_KiloGram" ICAS1_Gateway
 SG_ TSK_QBit_Steigung  : 12|1@1+ (1.000000,0.000000) [0.000000|1.000000] "" ICAS1_Gateway
 SG_ TSK_QBit_Fahrzeugmasse  : 13|1@1+ (1.000000,0.000000) [0.000000|1.000000] "" ICAS1_Gateway
 SG_ MO_SpannungsAnf_02  : 14|2@1+ (1.000000,0.000000) [0.000000|3.000000] "" ICAS1_Gateway
 SG_ MO_DPF_reg  : 16|1@1+ (1.000000,0.000000) [0.000000|1.000000] "" ICAS1_Gateway
 SG_ MO_Heizstrom_EKAT  : 17|7@1+ (1.000000,0.000000) [0.000000|126.000000] "Unit_Amper" ICAS1_Gateway
 SG_ MO_Heizstrom_SCR  : 24|6@1+ (1.000000,0.000000) [0.000000|62.000000] "Unit_Amper" ICAS1_Gateway
 SG_ MO_P_Generator_ungefiltert_Anf  : 31|1@1+ (1.000000,0.000000) [0.000000|1.000000] "" ICAS1_Gateway
 SG_ TSK_Getriebeinfo  : 34|2@1+ (1.000000,0.000000) [0.000000|3.000000] "" ICAS1_Gateway
 SG_ MO_Energieinhalt_BMS  : 36|12@1+ (25.000000,0.000000) [0.000000|102325.000000] "Unit_WattHour" ICAS1_Gateway
 SG_ TSK_Fahrzeugmasse_02  : 48|8@1+ (32.000000,0.000000) [0.000000|8128.000000] "Unit_KiloGram" ICAS1_Gateway
 SG_ TSK_Steigung_02  : 56|8@1+ (0.800000,-101.600000) [-100.800000|101.600000] "Unit_PerCent" ICAS1_Gateway

BO_ 1648 Motor_18: 8 Motor_BEV
 SG_ MO_max_Ladedruck  : 0|6@1+ (0.100000,0.000000) [0.000000|6.300000] "Unit_Bar" ICAS1_Gateway
 SG_ MO_ANC_Kennfeld_Anf  : 6|2@1+ (1.000000,0.000000) [0.000000|3.000000] "" ICAS1_Gateway
 SG_ MO_Bremslicht_Reku  : 8|1@1+ (1.000000,0.000000) [0.000000|1.000000] "" ICAS1_Gateway
 SG_ MO_StartStopp_PopUp  : 9|2@1+ (1.000000,0.000000) [0.000000|3.000000] "" ICAS1_Gateway
 SG_ MO1_Sperr_Info_WFS  : 11|1@1+ (1.000000,0.000000) [0.000000|1.000000] "" ICAS1_Gateway
 SG_ MO1_Freigabe_Info_WFS  : 12|1@1+ (1.000000,0.000000) [0.000000|1.000000] "" ICAS1_Gateway
 SG_ MO_EPCL  : 13|3@1+ (1.000000,0.000000) [0.000000|7.000000] "" ICAS1_Gateway ICAS1_KommunikationsServer
 SG_ MO_Zylabsch_Texte_02  : 16|4@1+ (1.000000,0.000000) [0.000000|15.000000] "" ICAS1_Gateway
 SG_ MO_Fahrzeugtyp  : 20|3@1+ (1.000000,0.000000) [0.000000|7.000000] "" ICAS1_Gateway ICAS1_KommunikationsServer
 SG_ MO_NMAX_Schaltanzeige  : 23|9@1+ (25.000000,0.000000) [0.000000|12775.000000] "Unit_MinutInver" ICAS1_Gateway
 SG_ MO_Abstellzeit  : 32|8@1+ (8.000000,0.000000) [0.000000|2024.000000] "Unit_Minut" ICAS1_Gateway
 SG_ MO_Abstellzeit_Status  : 40|2@1+ (1.000000,0.000000) [0.000000|3.000000] "" ICAS1_Gateway
 SG_ MO1_Freigabe_Verfallsinfo_WFS  : 42|1@1+ (1.000000,0.000000) [0.000000|1.000000] "" ICAS1_Gateway
 SG_ MO_Hybrid_StartStopp_LED  : 43|2@1+ (1.000000,0.000000) [0.000000|3.000000] "" ICAS1_Gateway
 SG_ MO_Fehler_Zylabsch  : 45|2@1+ (1.000000,0.000000) [0.000000|3.000000] "" ICAS1_Gateway
 SG_ MO_Anzahl_Abgesch_Zyl  : 47|3@1+ (1.000000,0.000000) [0.000000|7.000000] "" ICAS1_Gateway
 SG_ MO_Zylabsch_Texte  : 50|2@1+ (1.000000,0.000000) [0.000000|3.000000] "" ICAS1_Gateway
 SG_ MO_Ethanol_BS_Texte  : 52|3@1+ (1.000000,0.000000) [0.000000|7.000000] "" ICAS1_Gateway
 SG_ MO_Drehzahl_Warnung  : 55|1@1+ (1.000000,0.000000) [0.000000|1.000000] "" ICAS1_Gateway
 SG_ MO_obere_Drehzahlgrenze  : 56|8@1+ (50.000000,0.000000) [50.000000|12750.000000] "Unit_MinutInver" ICAS1_Gateway

BU_:  Airbag BAP_Tester ICAS1_Gateway ICAS1_KommunikationsServer LE1 LE2 Motor_BEV Schaltbetaetigung

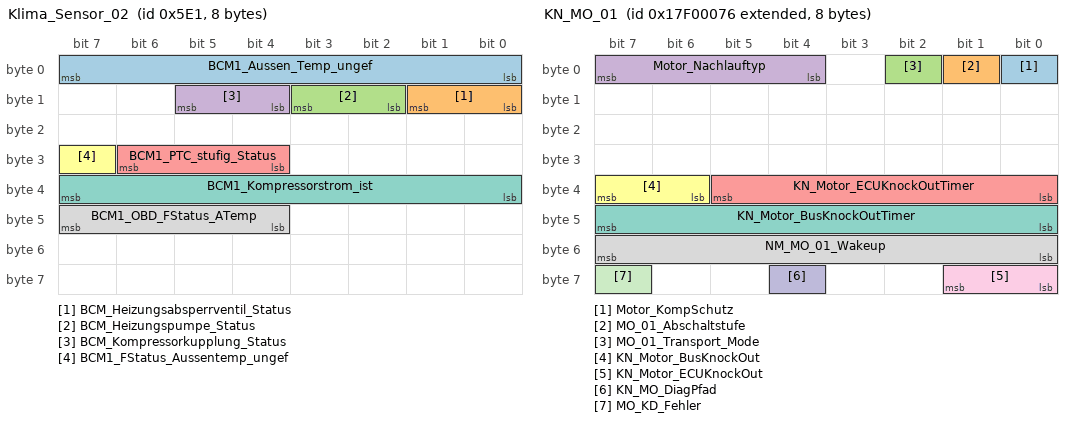
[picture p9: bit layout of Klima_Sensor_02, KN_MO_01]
BO_ 1505 Klima_Sensor_02: 8 ICAS1_Gateway
 SG_ BCM1_Aussen_Temp_ungef  : 0|8@1+ (0.500000,-50.000000) [-50.000000|76.000000] "Unit_DegreCelsi" LE1 LE2 Motor_BEV
 SG_ BCM_Heizungsabsperrventil_Status  : 8|2@1+ (1.000000,0.000000) [0.000000|3.000000] "" Vector__XXX
 SG_ BCM_Heizungspumpe_Status  : 10|2@1+ (1.000000,0.000000) [0.000000|3.000000] "" Vector__XXX
 SG_ BCM_Kompressorkupplung_Status  : 12|2@1+ (1.000000,0.000000) [0.000000|3.000000] "" Vector__XXX
 SG_ BCM1_PTC_stufig_Status  : 28|3@1+ (1.000000,0.000000) [0.000000|7.000000] "" Vector__XXX
 SG_ BCM1_FStatus_Aussentemp_ungef  : 31|1@1+ (1.000000,0.000000) [0.000000|1.000000] "" Vector__XXX
 SG_ BCM1_Kompressorstrom_ist  : 32|8@1+ (4.000000,0.000000) [0.000000|1000.000000] "Unit_MilliAmper" Vector__XXX
 SG_ BCM1_OBD_FStatus_ATemp  : 44|4@1+ (1.000000,0.000000) [0.000000|15.000000] "" Vector__XXX

BO_ 2549088277 KN_Airbag_01: 8 Airbag
 SG_ Airbag_01_KompSchutz  : 0|1@1+ (1.000000,0.000000) [0.000000|1.000000] "" Vector__XXX
 SG_ Airbag_01_Abschaltstufe  : 1|1@1+ (1.000000,0.000000) [0.000000|1.000000] "" Vector__XXX
 SG_ Airbag_01_Transport_Mode  : 2|1@1+ (1.000000,0.000000) [0.000000|1.000000] "" Vector__XXX
 SG_ Airbag_01_Nachlauftyp  : 4|4@1+ (1.000000,0.000000) [0.000000|15.000000] "" ICAS1_Gateway
 SG_ NM_Airbag_01_Wakeup  : 48|8@1+ (1.000000,0.000000) [0.000000|255.000000] "" Vector__XXX
 SG_ KN_AB_DiagPfad  : 60|1@1+ (1.000000,0.000000) [0.000000|1.000000] "" ICAS1_Gateway
 SG_ AB_KD_Fehler  : 63|1@1+ (1.000000,0.000000) [0.000000|1.000000] "" ICAS1_Gateway

BO_ 2549088380 KN_EMotor_01: 8 LE1
 SG_ EMotor_KompSchutz  : 0|1@1+ (1.000000,0.000000) [0.000000|1.000000] "" Vector__XXX
 SG_ EMotor_01_Abschaltstufe  : 1|1@1+ (1.000000,0.000000) [0.000000|1.000000] "" Vector__XXX
 SG_ EMotor_01_Transport_Mode  : 2|1@1+ (1.000000,0.000000) [0.000000|1.000000] "" Vector__XXX
 SG_ EMotor_Nachlauftyp  : 4|4@1+ (1.000000,0.000000) [0.000000|15.000000] "" ICAS1_Gateway
 SG_ NM_EMotor_01_Wakeup  : 48|8@1+ (1.000000,0.000000) [0.000000|255.000000] "" Vector__XXX
 SG_ KN_EM_HYB_DiagPfad  : 60|1@1+ (1.000000,0.000000) [0.000000|1.000000] "" ICAS1_Gateway
 SG_ EM_HYB_KD_Fehler  : 63|1@1+ (1.000000,0.000000) [0.000000|1.000000] "" ICAS1_Gateway

BO_ 2549088272 KN_Gateway: 8 ICAS1_Gateway
 SG_ Gateway_KompSchutz  : 0|1@1+ (1.000000,0.000000) [0.000000|1.000000] "" Vector__XXX
 SG_ Gateway_Abschaltstufe  : 1|1@1+ (1.000000,0.000000) [0.000000|1.000000] "" Vector__XXX
 SG_ Gateway_Transport_Mode  : 2|1@1+ (1.000000,0.000000) [0.000000|1.000000] "" Vector__XXX
 SG_ Gateway_Nachlauftyp  : 4|4@1+ (1.000000,0.000000) [0.000000|15.000000] "" Vector__XXX
 SG_ NM_Gateway_Wakeup  : 48|8@1+ (1.000000,0.000000) [0.000000|255.000000] "" Vector__XXX
 SG_ KN_GW_DiagPfad  : 60|1@1+ (1.000000,0.000000) [0.000000|1.000000] "" Vector__XXX
 SG_ GW_KD_Fehler  : 63|1@1+ (1.000000,0.000000) [0.000000|1.000000] "" Vector__XXX

BO_ 2549088440 KN_LE2: 8 LE2
 SG_ LE2_KompSchutz  : 0|1@1+ (1.000000,0.000000) [0.000000|1.000000] "" Vector__XXX
 SG_ LE2_Abschaltstufe  : 1|1@1+ (1.000000,0.000000) [0.000000|1.000000] "" Vector__XXX
 SG_ LE2_Transport_Mode  : 2|1@1+ (1.000000,0.000000) [0.000000|1.000000] "" Vector__XXX
 SG_ LE2_Nachlauftyp  : 4|4@1+ (1.000000,0.000000) [0.000000|15.000000] "" ICAS1_Gateway
 SG_ NM_LE2_Wakeup  : 48|8@1+ (1.000000,0.000000) [0.000000|255.000000] "" Vector__XXX
 SG_ KN_LE2_DiagPfad  : 60|1@1+ (1.000000,0.000000) [0.000000|1.000000] "" ICAS1_Gateway
 SG_ LE2_KD_Fehler  : 63|1@1+ (1.000000,0.000000) [0.000000|1.000000] "" ICAS1_Gateway

BO_ 2549088374 KN_MO_01: 8 Motor_BEV
 SG_ Motor_KompSchutz  : 0|1@1+ (1.000000,0.000000) [0.000000|1.000000] "" Vector__XXX
 SG_ MO_01_Abschaltstufe  : 1|1@1+ (1.000000,0.000000) [0.000000|1.000000] "" Vector__XXX
 SG_ MO_01_Transport_Mode  : 2|1@1+ (1.000000,0.000000) [0.000000|1.000000] "" Vector__XXX
 SG_ Motor_Nachlauftyp  : 4|4@1+ (1.000000,0.000000) [0.000000|15.000000] "" ICAS1_Gateway
 SG_ KN_Motor_ECUKnockOutTimer  : 32|6@1+ (1.000000,0.000000) [0.000000|62.000000] "Unit_Minut" Vector__XXX
 SG_ KN_Motor_BusKnockOut  : 38|2@1+ (1.000000,0.000000) [0.000000|3.000000] "" Vector__XXX
 SG_ KN_Motor_BusKnockOutTimer  : 40|8@1+ (1.000000,0.000000) [0.000000|254.000000] "" Vector__XXX
 SG_ NM_MO_01_Wakeup  : 48|8@1+ (1.000000,0.000000) [0.000000|255.000000] "" Vector__XXX
 SG_ KN_Motor_ECUKnockOut  : 56|2@1+ (1.000000,0.000000) [0.000000|3.000000] "" Vector__XXX
 SG_ KN_MO_DiagPfad  : 60|1@1+ (1.000000,0.000000) [0.000000|1.000000] "" ICAS1_Gateway
 SG_ MO_KD_Fehler  : 63|1@1+ (1.000000,0.000000) [0.000000|1.000000] "" ICAS1_Gateway

BO_ 2621440277 KS_Airbag_01_Req_FD: 16 ICAS1_Gateway
 SG_ KS_Airbag_01_Req_FD_Data  : 0|128@1+ (1.000000,0.000000) [0.000000|340282366920938463463374607431768211456.000000] "" Airbag

BO_ 2621571349 KS_Airbag_01_Resp_FD: 16 Airbag
 SG_ KS_Airbag_01_Resp_FD_Data  : 0|128@1+ (1.000000,0.000000) [0.000000|340282366920938463463374607431768211456.000000] "" ICAS1_Gateway

BO_ 982 Licht_hinten_01: 8 ICAS1_Gateway
 SG_ Licht_hinten_01_BZ  : 0|4@1+ (1.000000,0.000000) [0.000000|15.000000] "" Vector__XXX
 SG_ LH_Aussenlicht_def  : 7|1@1+ (1.000000,0.000000) [0.000000|1.000000] "" Vector__XXX
 SG_ LH_Standlicht_H_aktiv  : 8|1@1+ (1.000000,0.000000) [0.000000|1.000000] "" Vector__XXX
 SG_ LH_Parklicht_HL_aktiv  : 9|1@1+ (1.000000,0.000000) [0.000000|1.000000] "" Vector__XXX
 SG_ LH_Parklicht_HR_aktiv  : 10|1@1+ (1.000000,0.000000) [0.000000|1.000000] "" Vector__XXX
 SG_ LH_Bremslicht_H_aktiv  : 11|1@1+ (1.000000,0.000000) [0.000000|1.000000] "" Vector__XXX
 SG_ LH_Nebelschluss_aktiv  : 12|1@1+ (1.000000,0.000000) [0.000000|1.000000] "" Vector__XXX
 SG_ LH_Rueckfahrlicht_aktiv  : 13|1@1+ (1.000000,0.000000) [0.000000|1.000000] "" Vector__XXX
 SG_ LH_Blinker_HL_akt  : 14|1@1+ (1.000000,0.000000) [0.000000|1.000000] "" Vector__XXX
 SG_ LH_Blinker_HR_akt  : 15|1@1+ (1.000000,0.000000) [0.000000|1.000000] "" Vector__XXX
 SG_ LH_Blinker_li_def  : 16|1@1+ (1.000000,0.000000) [0.000000|1.000000] "" Vector__XXX
 SG_ LH_Bremsl_li_def  : 17|1@1+ (1.000000,0.000000) [0.000000|1.000000] "" Vector__XXX
 SG_ LH_Schlusslicht_li_def  : 18|1@1+ (1.000000,0.000000) [0.000000|1.000000] "" Vector__XXX
 SG_ LH_Rueckf_li_def  : 19|1@1+ (1.000000,0.000000) [0.000000|1.000000] "" Vector__XXX
 SG_ LH_Nebel_li_def  : 20|1@1+ (1.000000,0.000000) [0.000000|1.000000] "" Vector__XXX
 SG_ LH_Schluss_Brems_Nebel_li_def  : 21|1@1+ (1.000000,0.000000) [0.000000|1.000000] "" Vector__XXX
 SG_ LH_Schluss_Brems_Nebel_re_def  : 22|1@1+ (1.000000,0.000000) [0.000000|1.000000] "" Vector__XXX
 SG_ LH_Zusatzschlussl_def  : 23|1@1+ (1.000000,0.000000) [0.000000|1.000000] "" Vector__XXX
 SG_ LH_Schluss_Brems_li_def  : 24|1@1+ (1.000000,0.000000) [0.000000|1.000000] "" Vector__XXX
 SG_ LH_Schluss_Nebel_li_def  : 25|1@1+ (1.000000,0.000000) [0.000000|1.000000] "" Vector__XXX
 SG_ LH_SL_BRL_BLK_li_def  : 26|1@1+ (1.000000,0.000000) [0.000000|1.000000] "" Vector__XXX
 SG_ LH_Brems_Blk_li_def  : 27|1@1+ (1.000000,0.000000) [0.000000|1.000000] "" Vector__XXX
 SG_ LH_Diag_Status_re_def  : 28|1@1+ (1.000000,0.000000) [0.000000|1.000000] "" Vector__XXX
 SG_ LH_Diag_Status_li_def  : 29|1@1+ (1.000000,0.000000) [0.000000|1.000000] "" Vector__XXX
 SG_ LH_Diag_LED_li_def  : 30|1@1+ (1.000000,0.000000) [0.000000|1.000000] "" Vector__XXX
 SG_ LH_Diag_LED_re_def  : 31|1@1+ (1.000000,0.000000) [0.000000|1.000000] "" Vector__XXX
 SG_ LH_Blinker_re_def  : 32|1@1+ (1.000000,0.000000) [0.000000|1.000000] "" Vector__XXX
 SG_ LH_Bremsl_re_def  : 33|1@1+ (1.000000,0.000000) [0.000000|1.000000] "" Vector__XXX
 SG_ LH_Schlusslicht_re_def  : 34|1@1+ (1.000000,0.000000) [0.000000|1.000000] "" Vector__XXX
 SG_ LH_Rueckf_re_def  : 35|1@1+ (1.000000,0.000000) [0.000000|1.000000] "" Vector__XXX
 SG_ LH_Nebel_re_def  : 36|1@1+ (1.000000,0.000000) [0.000000|1.000000] "" Vector__XXX
 SG_ LH_Schluss_Brems_mi_def  : 37|1@1+ (1.000000,0.000000) [0.000000|1.000000] "" Vector__XXX
 SG_ LH_Schluss_Brems_re_def  : 40|1@1+ (1.000000,0.000000) [0.000000|1.000000] "" Vector__XXX
 SG_ LH_Schluss_Nebel_re_def  : 41|1@1+ (1.000000,0.000000) [0.000000|1.000000] "" Vector__XXX
 SG_ LH_SL_BRL_BLK_re_def  : 42|1@1+ (1.000000,0.000000) [0.000000|1.000000] "" Vector__XXX
 SG_ LH_Brems_Blk_re_def  : 43|1@1+ (1.000000,0.000000) [0.000000|1.000000] "" Vector__XXX
 SG_ LH_Kennzl_def  : 48|1@1+ (1.000000,0.000000) [0.000000|1.000000] "" Vector__XXX
 SG_ LH_3_Bremsl_def  : 49|1@1+ (1.000000,0.000000) [0.000000|1.000000] "" Motor_BEV
 SG_ LH_Nebel_mi_def  : 50|1@1+ (1.000000,0.000000) [0.000000|1.000000] "" Vector__XXX
 SG_ LH_Rueckf_mi_def  : 51|1@1+ (1.000000,0.000000) [0.000000|1.000000] "" Vector__XXX
 SG_ LH_Schlusslicht_mi_def  : 52|1@1+ (1.000000,0.000000) [0.000000|1.000000] "" Vector__XXX
 SG_ LH_Bremsl_li_ges_def  : 54|1@1+ (1.000000,0.000000) [0.000000|1.000000] "" Motor_BEV
 SG_ LH_Bremsl_re_ges_def  : 55|1@1+ (1.000000,0.000000) [0.000000|1.000000] "" Motor_BEV
 SG_ LH_Bremsl_mi_def  : 61|1@1+ (1.000000,0.000000) [0.000000|1.000000] "" Vector__XXX
 SG_ BRL_als_SHL  : 62|1@1+ (1.000000,0.000000) [0.000000|1.000000] "" Vector__XXX

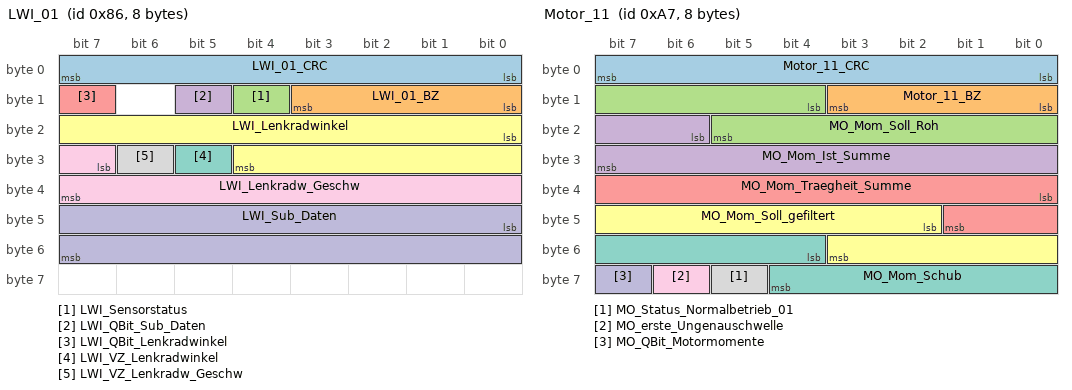
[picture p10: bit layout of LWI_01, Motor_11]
BO_ 134 LWI_01: 8 ICAS1_Gateway
 SG_ LWI_01_CRC  : 0|8@1+ (1.000000,0.000000) [0.000000|255.000000] "" Airbag Motor_BEV
 SG_ LWI_01_BZ  : 8|4@1+ (1.000000,0.000000) [0.000000|15.000000] "" Airbag Motor_BEV
 SG_ LWI_Sensorstatus  : 12|1@1+ (1.000000,0.000000) [0.000000|1.000000] "" Airbag Motor_BEV
 SG_ LWI_QBit_Sub_Daten  : 13|1@1+ (1.000000,0.000000) [0.000000|1.000000] "" Vector__XXX
 SG_ LWI_QBit_Lenkradwinkel  : 15|1@1+ (1.000000,0.000000) [0.000000|1.000000] "" Airbag Motor_BEV
 SG_ LWI_Lenkradwinkel  : 16|13@1+ (0.100000,0.000000) [0.000000|800.000000] "Unit_DegreOfArc" Airbag Motor_BEV
 SG_ LWI_VZ_Lenkradwinkel  : 29|1@1+ (1.000000,0.000000) [0.000000|1.000000] "" Airbag Motor_BEV
 SG_ LWI_VZ_Lenkradw_Geschw  : 30|1@1+ (1.000000,0.000000) [0.000000|1.000000] "" Vector__XXX
 SG_ LWI_Lenkradw_Geschw  : 31|9@1+ (5.000000,0.000000) [0.000000|2500.000000] "Unit_DegreOfArcPerSecon" Airbag
 SG_ LWI_Sub_Daten  : 40|16@1+ (1.000000,0.000000) [0.000000|65535.000000] "" Vector__XXX

BO_ 817 MFL_01: 8 ICAS1_Gateway
 SG_ MFL_Zaehler  : 0|4@1+ (1.000000,0.000000) [0.000000|15.000000] "" Vector__XXX
 SG_ MFL_Toggle  : 4|1@1+ (1.000000,0.000000) [0.000000|1.000000] "" Vector__XXX
 SG_ MFL_Lokalaktiv  : 5|1@1+ (1.000000,0.000000) [0.000000|1.000000] "" Vector__XXX
 SG_ MFL_M_Taste  : 6|1@1+ (1.000000,0.000000) [0.000000|1.000000] "" Vector__XXX
 SG_ MFL_Paddle_Verbau  : 7|1@1+ (1.000000,0.000000) [0.000000|1.000000] "" Vector__XXX
 SG_ MFL_Tastencode_1  : 8|8@1+ (1.000000,0.000000) [0.000000|255.000000] "" Vector__XXX
 SG_ MFL_Tastencode_2  : 16|8@1+ (1.000000,0.000000) [0.000000|255.000000] "" Vector__XXX
 SG_ MFL_Eventcode_1  : 24|4@1+ (1.000000,0.000000) [0.000000|15.000000] "" Vector__XXX
 SG_ MFL_Eventcode_2  : 28|4@1+ (1.000000,0.000000) [0.000000|15.000000] "" Vector__XXX
 SG_ MFL_Marke  : 32|4@1+ (1.000000,0.000000) [0.000000|15.000000] "" Vector__XXX
 SG_ MFL_Variante  : 36|4@1+ (1.000000,0.000000) [0.000000|15.000000] "" Vector__XXX
 SG_ MFL_Dummy_0_Signal_1  : 40|8@1+ (1.000000,0.000000) [0.000000|255.000000] "" Vector__XXX
 SG_ MFL_Tip_Down  : 48|1@1+ (1.000000,0.000000) [0.000000|1.000000] "" Motor_BEV
 SG_ MFL_Tip_Up  : 49|1@1+ (1.000000,0.000000) [0.000000|1.000000] "" Motor_BEV
 SG_ MFL_SatModul_links_Err  : 50|1@1+ (1.000000,0.000000) [0.000000|1.000000] "" Vector__XXX
 SG_ MFL_SatModul_rechts_Err  : 51|1@1+ (1.000000,0.000000) [0.000000|1.000000] "" Vector__XXX
 SG_ MFL_Dummy_0_Signal_2  : 52|1@1+ (1.000000,0.000000) [0.000000|1.000000] "" Vector__XXX
 SG_ MFL_Dummy_0_Signal_3  : 53|1@1+ (1.000000,0.000000) [0.000000|1.000000] "" Vector__XXX
 SG_ MFL_LR_HZG_Status  : 54|1@1+ (1.000000,0.000000) [0.000000|1.000000] "" Vector__XXX
 SG_ MFL_LR_HZG_Err  : 55|1@1+ (1.000000,0.000000) [0.000000|1.000000] "" Vector__XXX
 SG_ MFL_Signalhorn  : 56|1@1+ (1.000000,0.000000) [0.000000|1.000000] "" Vector__XXX
 SG_ MFL_Signalhorn_Err  : 57|1@1+ (1.000000,0.000000) [0.000000|1.000000] "" Vector__XXX
 SG_ MFL_Tip_links_Err  : 58|1@1+ (1.000000,0.000000) [0.000000|1.000000] "" Vector__XXX
 SG_ MFL_Tip_rechts_Err  : 59|1@1+ (1.000000,0.000000) [0.000000|1.000000] "" Vector__XXX
 SG_ MFL_Taste_links_Err  : 60|1@1+ (1.000000,0.000000) [0.000000|1.000000] "" Vector__XXX
 SG_ MFL_Taste_rechts_Err  : 61|1@1+ (1.000000,0.000000) [0.000000|1.000000] "" Vector__XXX
 SG_ MFL_ECU_Err  : 62|1@1+ (1.000000,0.000000) [0.000000|1.000000] "" Vector__XXX
 SG_ MFL_Response_Err  : 63|1@1+ (1.000000,0.000000) [0.000000|1.000000] "" Vector__XXX

BO_ 15 MO_SOPC: 1 Motor_BEV
 SG_ MO_SOPC  : 0|1@1+ (1.000000,0.000000) [0.000000|1.000000] "" Vector__XXX

BO_ 1600 Motor_07: 8 Motor_BEV
 SG_ MO_QBit_Ansaugluft_Temp  : 0|1@1+ (1.000000,0.000000) [0.000000|1.000000] "" Vector__XXX
 SG_ MO_QBit_Oel_Temp  : 1|1@1+ (1.000000,0.000000) [0.000000|1.000000] "" Vector__XXX
 SG_ MO_QBit_Kuehlmittel_Temp  : 2|1@1+ (1.000000,0.000000) [0.000000|1.000000] "" Vector__XXX
 SG_ MO_KL15_Abschaltempfehlung  : 3|1@1+ (1.000000,0.000000) [0.000000|1.000000] "" Vector__XXX
 SG_ MO_HYB_Fehler_HV_Netz  : 4|1@1+ (1.000000,0.000000) [0.000000|1.000000] "" Vector__XXX
 SG_ MO_aktives_Getriebeheizen  : 5|1@1+ (1.000000,0.000000) [0.000000|1.000000] "" Vector__XXX
 SG_ MO_Absperrventil_oeffnen  : 6|2@1+ (1.000000,0.000000) [0.000000|3.000000] "" Vector__XXX
 SG_ MO_Ansaugluft_Temp  : 8|8@1+ (0.750000,-48.000000) [-48.000000|141.750000] "Unit_DegreCelsi" Vector__XXX
 SG_ MO_Oel_Temp  : 16|8@1+ (1.000000,-60.000000) [-60.000000|192.000000] "Unit_DegreCelsi" Vector__XXX
 SG_ MO_Kuehlmittel_Temp  : 24|8@1+ (0.750000,-48.000000) [-48.000000|141.750000] "Unit_DegreCelsi" Vector__XXX
 SG_ MO_Hoeheninfo  : 32|8@1+ (0.007810,0.000000) [0.000000|1.983740] "" Vector__XXX
 SG_ MO_Kennfeldk  : 40|1@1+ (1.000000,0.000000) [0.000000|1.000000] "" Vector__XXX
 SG_ MO_Versionsinfo_02  : 41|5@1+ (1.000000,0.000000) [0.000000|31.000000] "" Vector__XXX
 SG_ MO_QBit_Hoeheninfo  : 46|1@1+ (1.000000,0.000000) [0.000000|1.000000] "" Vector__XXX
 SG_ MO_Getriebe_kuehlen  : 47|1@1+ (1.000000,0.000000) [0.000000|1.000000] "" Vector__XXX
 SG_ MO_Mom_Traegheit_02  : 48|5@1+ (0.010000,0.000000) [0.000000|0.310000] "Unit_KiloGramMeterSquar" Vector__XXX
 SG_ MO_Heizungspumpenansteuerung  : 53|4@1+ (10.000000,0.000000) [0.000000|100.000000] "Unit_PerCent" Vector__XXX
 SG_ MO_SpannungsAnf  : 57|1@1+ (1.000000,0.000000) [0.000000|1.000000] "" Vector__XXX
 SG_ MO_Nachlaufzeit_Heizungspumpe  : 58|6@1+ (15.000000,0.000000) [0.000000|945.000000] "Unit_Secon" Vector__XXX

BO_ 167 Motor_11: 8 Motor_BEV
 SG_ Motor_11_CRC  : 0|8@1+ (1.000000,0.000000) [0.000000|255.000000] "" ICAS1_Gateway
 SG_ Motor_11_BZ  : 8|4@1+ (1.000000,0.000000) [0.000000|15.000000] "" ICAS1_Gateway
 SG_ MO_Mom_Soll_Roh  : 12|10@1+ (1.000000,-509.000000) [-509.000000|509.000000] "" ICAS1_Gateway
 SG_ MO_Mom_Ist_Summe  : 22|10@1+ (1.000000,-509.000000) [-509.000000|509.000000] "" ICAS1_Gateway
 SG_ MO_Mom_Traegheit_Summe  : 32|10@1+ (1.000000,-509.000000) [-509.000000|509.000000] "" ICAS1_Gateway
 SG_ MO_Mom_Soll_gefiltert  : 42|10@1+ (1.000000,-509.000000) [-509.000000|509.000000] "" ICAS1_Gateway
 SG_ MO_Mom_Schub  : 52|9@1+ (1.000000,-509.000000) [-509.000000|0.000000] "" ICAS1_Gateway
 SG_ MO_Status_Normalbetrieb_01  : 61|1@1+ (1.000000,0.000000) [0.000000|1.000000] "" ICAS1_Gateway
 SG_ MO_erste_Ungenauschwelle  : 62|1@1+ (1.000000,0.000000) [0.000000|1.000000] "" ICAS1_Gateway
 SG_ MO_QBit_Motormomente  : 63|1@1+ (1.000000,0.000000) [0.000000|1.000000] "" ICAS1_Gateway

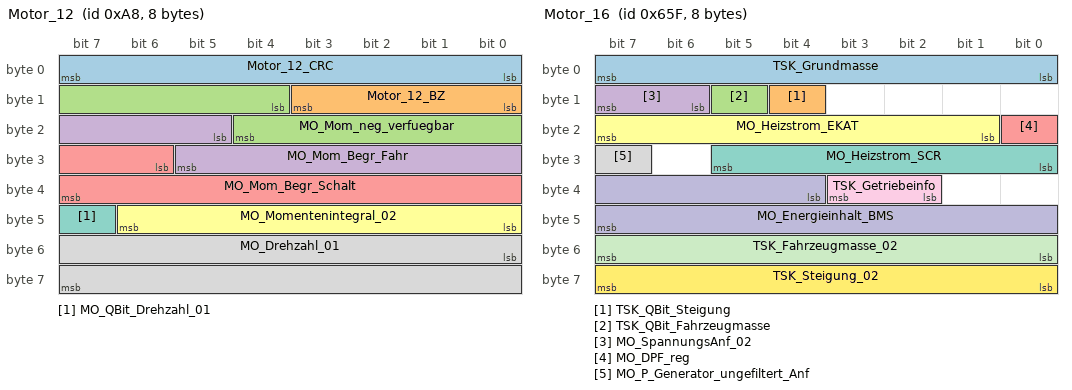
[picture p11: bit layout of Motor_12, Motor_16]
BO_ 168 Motor_12: 8 Motor_BEV
 SG_ Motor_12_CRC  : 0|8@1+ (1.000000,0.000000) [0.000000|255.000000] "" ICAS1_Gateway
 SG_ Motor_12_BZ  : 8|4@1+ (1.000000,0.000000) [0.000000|15.000000] "" ICAS1_Gateway
 SG_ MO_Mom_neg_verfuegbar  : 12|9@1+ (1.000000,-509.000000) [-509.000000|0.000000] "" ICAS1_Gateway
 SG_ MO_Mom_Begr_Fahr  : 21|9@1+ (1.000000,0.000000) [0.000000|509.000000] "" ICAS1_Gateway
 SG_ MO_Mom_Begr_Schalt  : 30|10@1+ (1.000000,-509.000000) [-509.000000|509.000000] "" ICAS1_Gateway
 SG_ MO_Momentenintegral_02  : 40|7@1+ (1.000000,0.000000) [0.000000|100.000000] "Unit_PerCent" ICAS1_Gateway
 SG_ MO_QBit_Drehzahl_01  : 47|1@1+ (1.000000,0.000000) [0.000000|1.000000] "" Airbag ICAS1_Gateway LE2
 SG_ MO_Drehzahl_01  : 48|16@1+ (0.250000,0.000000) [0.000000|16383.000000] "Unit_MinutInver" ICAS1_Gateway

BO_ 958 Motor_14: 8 Motor_BEV
 SG_ Motor_14_CRC  : 0|8@1+ (1.000000,0.000000) [0.000000|255.000000] "" ICAS1_Gateway
 SG_ Motor_14_BZ  : 8|4@1+ (1.000000,0.000000) [0.000000|15.000000] "" ICAS1_Gateway
 SG_ MO_StartStopp_Status  : 12|2@1+ (1.000000,0.000000) [0.000000|3.000000] "" ICAS1_Gateway
 SG_ MO_StartStopp_Wiederstart  : 14|1@1+ (1.000000,0.000000) [0.000000|1.000000] "" ICAS1_Gateway
 SG_ MO_StartStopp_Motorstopp  : 15|1@1+ (1.000000,0.000000) [0.000000|1.000000] "" ICAS1_Gateway
 SG_ MO_Freig_Reku  : 16|2@1+ (1.000000,0.000000) [0.000000|3.000000] "" ICAS1_Gateway
 SG_ MO_Kl_75  : 18|1@1+ (1.000000,0.000000) [0.000000|1.000000] "" ICAS1_Gateway
 SG_ MO_Kl_50  : 19|1@1+ (1.000000,0.000000) [0.000000|1.000000] "" ICAS1_Gateway
 SG_ MO_Gangposition  : 20|4@1+ (1.000000,0.000000) [0.000000|15.000000] "" ICAS1_Gateway
 SG_ MO_StartStopp_Fahrerwunsch  : 24|2@1+ (1.000000,0.000000) [0.000000|3.000000] "" ICAS1_Gateway
 SG_ MO_HYB_Fahrbereitschaft  : 26|1@1+ (1.000000,0.000000) [0.000000|1.000000] "" ICAS1_Gateway
 SG_ MO_Ext_E_Fahrt_aktiv  : 27|1@1+ (1.000000,0.000000) [0.000000|1.000000] "" ICAS1_Gateway
 SG_ MO_Fahrer_bremst  : 28|1@1+ (1.000000,0.000000) [0.000000|1.000000] "" Airbag ICAS1_Gateway
 SG_ MO_QBit_Fahrer_bremst  : 29|1@1+ (1.000000,0.000000) [0.000000|1.000000] "" Airbag ICAS1_Gateway
 SG_ MO_BLS  : 30|1@1+ (1.000000,0.000000) [0.000000|1.000000] "" Airbag ICAS1_Gateway
 SG_ MO_Konsistenz_Bremsped  : 31|1@1+ (1.000000,0.000000) [0.000000|1.000000] "" ICAS1_Gateway
 SG_ MO_Timeout_ESP  : 32|1@1+ (1.000000,0.000000) [0.000000|1.000000] "" ICAS1_Gateway
 SG_ MO_Klima_Eingr  : 33|2@1+ (1.000000,0.000000) [0.000000|3.000000] "" ICAS1_Gateway
 SG_ MO_Aussp_Anlass  : 35|1@1+ (1.000000,0.000000) [0.000000|1.000000] "" ICAS1_Gateway
 SG_ MO_Freig_Anlass  : 36|1@1+ (1.000000,0.000000) [0.000000|1.000000] "" ICAS1_Gateway
 SG_ MO_Kuppl_schalter  : 37|1@1+ (1.000000,0.000000) [0.000000|1.000000] "" ICAS1_Gateway
 SG_ MO_Interlock  : 38|1@1+ (1.000000,0.000000) [0.000000|1.000000] "" ICAS1_Gateway
 SG_ MO_Motor_laeuft  : 39|1@1+ (1.000000,0.000000) [0.000000|1.000000] "" ICAS1_Gateway
 SG_ MO_Kickdown  : 40|1@1+ (1.000000,0.000000) [0.000000|1.000000] "" ICAS1_Gateway ICAS1_KommunikationsServer
 SG_ MO_QBit_KL_75  : 41|1@1+ (1.000000,0.000000) [0.000000|1.000000] "" ICAS1_Gateway
 SG_ MO_EKlKomLeiRed  : 42|2@1+ (1.000000,0.000000) [0.000000|3.000000] "" ICAS1_Gateway
 SG_ MO_Handshake_STH  : 44|1@1+ (1.000000,0.000000) [0.000000|1.000000] "" ICAS1_Gateway
 SG_ MO_BKV_Unterdruckwarnung  : 45|1@1+ (1.000000,0.000000) [0.000000|1.000000] "" ICAS1_Gateway
 SG_ MO_Freigabe_Segeln  : 46|1@1+ (1.000000,0.000000) [0.000000|1.000000] "" ICAS1_Gateway
 SG_ MO_PTC_Status  : 47|3@1+ (1.000000,0.000000) [0.000000|7.000000] "" ICAS1_Gateway
 SG_ MO_QBit_Gangposition  : 50|1@1+ (1.000000,0.000000) [0.000000|1.000000] "" ICAS1_Gateway
 SG_ MO_Signalquelle_Gangposition  : 51|1@1+ (1.000000,0.000000) [0.000000|1.000000] "" ICAS1_Gateway
 SG_ MO_Remotestart_Betrieb  : 52|1@1+ (1.000000,0.000000) [0.000000|1.000000] "" ICAS1_Gateway
 SG_ MO_Remotestart_moeglich  : 53|1@1+ (1.000000,0.000000) [0.000000|1.000000] "" ICAS1_Gateway
 SG_ MO_FMAus_aktiv  : 55|1@1+ (1.000000,0.000000) [0.000000|1.000000] "" ICAS1_Gateway
 SG_ MO_FMAus_Startvariante  : 56|2@1+ (1.000000,0.000000) [0.000000|3.000000] "" ICAS1_Gateway
 SG_ MO_BMS_NV_Anf_stuetzen  : 58|1@1+ (1.000000,0.000000) [0.000000|1.000000] "" ICAS1_Gateway
 SG_ MO_Zylinderabschaltung  : 59|2@1+ (1.000000,0.000000) [0.000000|3.000000] "" ICAS1_Gateway
 SG_ MO_HYB_VM_aktiv  : 61|1@1+ (1.000000,0.000000) [0.000000|1.000000] "" ICAS1_Gateway
 SG_ MO_StartVorauss_erfuellt  : 62|2@1+ (1.000000,0.000000) [0.000000|3.000000] "" ICAS1_Gateway

BO_ 1631 Motor_16: 8 Motor_BEV
 SG_ TSK_Grundmasse  : 0|8@1+ (32.000000,0.000000) [0.000000|8128.000000] "Unit_KiloGram" ICAS1_Gateway
 SG_ TSK_QBit_Steigung  : 12|1@1+ (1.000000,0.000000) [0.000000|1.000000] "" ICAS1_Gateway
 SG_ TSK_QBit_Fahrzeugmasse  : 13|1@1+ (1.000000,0.000000) [0.000000|1.000000] "" ICAS1_Gateway
 SG_ MO_SpannungsAnf_02  : 14|2@1+ (1.000000,0.000000) [0.000000|3.000000] "" ICAS1_Gateway
 SG_ MO_DPF_reg  : 16|1@1+ (1.000000,0.000000) [0.000000|1.000000] "" ICAS1_Gateway
 SG_ MO_Heizstrom_EKAT  : 17|7@1+ (1.000000,0.000000) [0.000000|126.000000] "Unit_Amper" ICAS1_Gateway
 SG_ MO_Heizstrom_SCR  : 24|6@1+ (1.000000,0.000000) [0.000000|62.000000] "Unit_Amper" ICAS1_Gateway
 SG_ MO_P_Generator_ungefiltert_Anf  : 31|1@1+ (1.000000,0.000000) [0.000000|1.000000] "" ICAS1_Gateway
 SG_ TSK_Getriebeinfo  : 34|2@1+ (1.000000,0.000000) [0.000000|3.000000] "" ICAS1_Gateway
 SG_ MO_Energieinhalt_BMS  : 36|12@1+ (25.000000,0.000000) [0.000000|102325.000000] "Unit_WattHour" ICAS1_Gateway
 SG_ TSK_Fahrzeugmasse_02  : 48|8@1+ (32.000000,0.000000) [0.000000|8128.000000] "Unit_KiloGram" ICAS1_Gateway
 SG_ TSK_Steigung_02  : 56|8@1+ (0.800000,-101.600000) [-100.800000|101.600000] "Unit_PerCent" ICAS1_Gateway

BO_ 1648 Motor_18: 8 Motor_BEV
 SG_ MO_max_Ladedruck  : 0|6@1+ (0.100000,0.000000) [0.000000|6.300000] "Unit_Bar" ICAS1_Gateway
 SG_ MO_ANC_Kennfeld_Anf  : 6|2@1+ (1.000000,0.000000) [0.000000|3.000000] "" ICAS1_Gateway
 SG_ MO_Bremslicht_Reku  : 8|1@1+ (1.000000,0.000000) [0.000000|1.000000] "" ICAS1_Gateway
 SG_ MO_StartStopp_PopUp  : 9|2@1+ (1.000000,0.000000) [0.000000|3.000000] "" ICAS1_Gateway
 SG_ MO1_Sperr_Info_WFS  : 11|1@1+ (1.000000,0.000000) [0.000000|1.000000] "" ICAS1_Gateway
 SG_ MO1_Freigabe_Info_WFS  : 12|1@1+ (1.000000,0.000000) [0.000000|1.000000] "" ICAS1_Gateway
 SG_ MO_EPCL  : 13|3@1+ (1.000000,0.000000) [0.000000|7.000000] "" ICAS1_Gateway ICAS1_KommunikationsServer
 SG_ MO_Zylabsch_Texte_02  : 16|4@1+ (1.000000,0.000000) [0.000000|15.000000] "" ICAS1_Gateway
 SG_ MO_Fahrzeugtyp  : 20|3@1+ (1.000000,0.000000) [0.000000|7.000000] "" ICAS1_Gateway ICAS1_KommunikationsServer
 SG_ MO_NMAX_Schaltanzeige  : 23|9@1+ (25.000000,0.000000) [0.000000|12775.000000] "Unit_MinutInver" ICAS1_Gateway
 SG_ MO_Abstellzeit  : 32|8@1+ (8.000000,0.000000) [0.000000|2024.000000] "Unit_Minut" ICAS1_Gateway
 SG_ MO_Abstellzeit_Status  : 40|2@1+ (1.000000,0.000000) [0.000000|3.000000] "" ICAS1_Gateway
 SG_ MO1_Freigabe_Verfallsinfo_WFS  : 42|1@1+ (1.000000,0.000000) [0.000000|1.000000] "" ICAS1_Gateway
 SG_ MO_Hybrid_StartStopp_LED  : 43|2@1+ (1.000000,0.000000) [0.000000|3.000000] "" ICAS1_Gateway
 SG_ MO_Fehler_Zylabsch  : 45|2@1+ (1.000000,0.000000) [0.000000|3.000000] "" ICAS1_Gateway
 SG_ MO_Anzahl_Abgesch_Zyl  : 47|3@1+ (1.000000,0.000000) [0.000000|7.000000] "" ICAS1_Gateway
 SG_ MO_Zylabsch_Texte  : 50|2@1+ (1.000000,0.000000) [0.000000|3.000000] "" ICAS1_Gateway
 SG_ MO_Ethanol_BS_Texte  : 52|3@1+ (1.000000,0.000000) [0.000000|7.000000] "" ICAS1_Gateway
 SG_ MO_Drehzahl_Warnung  : 55|1@1+ (1.000000,0.000000) [0.000000|1.000000] "" ICAS1_Gateway
 SG_ MO_obere_Drehzahlgrenze  : 56|8@1+ (50.000000,0.000000) [50.000000|12750.000000] "Unit_MinutInver" ICAS1_Gateway

BU_:  Airbag BAP_Tester ICAS1_Gateway ICAS1_KommunikationsServer LE1 LE2 Motor_BEV Schaltbetaetigung

BO_ 1505 Klima_Sensor_02: 8 ICAS1_Gateway
 SG_ BCM1_Aussen_Temp_ungef  : 0|8@1+ (0.500000,-50.000000) [-50.000000|76.000000] "Unit_DegreCelsi" LE1 LE2 Motor_BEV
 SG_ BCM_Heizungsabsperrventil_Status  : 8|2@1+ (1.000000,0.000000) [0.000000|3.000000] "" Vector__XXX
 SG_ BCM_Heizungspumpe_Status  : 10|2@1+ (1.000000,0.000000) [0.000000|3.000000] "" Vector__XXX
 SG_ BCM_Kompressorkupplung_Status  : 12|2@1+ (1.000000,0.000000) [0.000000|3.000000] "" Vector__XXX
 SG_ BCM1_PTC_stufig_Status  : 28|3@1+ (1.000000,0.000000) [0.000000|7.000000] "" Vector__XXX
 SG_ BCM1_FStatus_Aussentemp_ungef  : 31|1@1+ (1.000000,0.000000) [0.000000|1.000000] "" Vector__XXX
 SG_ BCM1_Kompressorstrom_ist  : 32|8@1+ (4.000000,0.000000) [0.000000|1000.000000] "Unit_MilliAmper" Vector__XXX
 SG_ BCM1_OBD_FStatus_ATemp  : 44|4@1+ (1.000000,0.000000) [0.000000|15.000000] "" Vector__XXX

BO_ 2549088277 KN_Airbag_01: 8 Airbag
 SG_ Airbag_01_KompSchutz  : 0|1@1+ (1.000000,0.000000) [0.000000|1.000000] "" Vector__XXX
 SG_ Airbag_01_Abschaltstufe  : 1|1@1+ (1.000000,0.000000) [0.000000|1.000000] "" Vector__XXX
 SG_ Airbag_01_Transport_Mode  : 2|1@1+ (1.000000,0.000000) [0.000000|1.000000] "" Vector__XXX
 SG_ Airbag_01_Nachlauftyp  : 4|4@1+ (1.000000,0.000000) [0.000000|15.000000] "" ICAS1_Gateway
 SG_ NM_Airbag_01_Wakeup  : 48|8@1+ (1.000000,0.000000) [0.000000|255.000000] "" Vector__XXX
 SG_ KN_AB_DiagPfad  : 60|1@1+ (1.000000,0.000000) [0.000000|1.000000] "" ICAS1_Gateway
 SG_ AB_KD_Fehler  : 63|1@1+ (1.000000,0.000000) [0.000000|1.000000] "" ICAS1_Gateway

BO_ 2549088380 KN_EMotor_01: 8 LE1
 SG_ EMotor_KompSchutz  : 0|1@1+ (1.000000,0.000000) [0.000000|1.000000] "" Vector__XXX
 SG_ EMotor_01_Abschaltstufe  : 1|1@1+ (1.000000,0.000000) [0.000000|1.000000] "" Vector__XXX
 SG_ EMotor_01_Transport_Mode  : 2|1@1+ (1.000000,0.000000) [0.000000|1.000000] "" Vector__XXX
 SG_ EMotor_Nachlauftyp  : 4|4@1+ (1.000000,0.000000) [0.000000|15.000000] "" ICAS1_Gateway
 SG_ NM_EMotor_01_Wakeup  : 48|8@1+ (1.000000,0.000000) [0.000000|255.000000] "" Vector__XXX
 SG_ KN_EM_HYB_DiagPfad  : 60|1@1+ (1.000000,0.000000) [0.000000|1.000000] "" ICAS1_Gateway
 SG_ EM_HYB_KD_Fehler  : 63|1@1+ (1.000000,0.000000) [0.000000|1.000000] "" ICAS1_Gateway

BO_ 2549088272 KN_Gateway: 8 ICAS1_Gateway
 SG_ Gateway_KompSchutz  : 0|1@1+ (1.000000,0.000000) [0.000000|1.000000] "" Vector__XXX
 SG_ Gateway_Abschaltstufe  : 1|1@1+ (1.000000,0.000000) [0.000000|1.000000] "" Vector__XXX
 SG_ Gateway_Transport_Mode  : 2|1@1+ (1.000000,0.000000) [0.000000|1.000000] "" Vector__XXX
 SG_ Gateway_Nachlauftyp  : 4|4@1+ (1.000000,0.000000) [0.000000|15.000000] "" Vector__XXX
 SG_ NM_Gateway_Wakeup  : 48|8@1+ (1.000000,0.000000) [0.000000|255.000000] "" Vector__XXX
 SG_ KN_GW_DiagPfad  : 60|1@1+ (1.000000,0.000000) [0.000000|1.000000] "" Vector__XXX
 SG_ GW_KD_Fehler  : 63|1@1+ (1.000000,0.000000) [0.000000|1.000000] "" Vector__XXX

BO_ 2549088440 KN_LE2: 8 LE2
 SG_ LE2_KompSchutz  : 0|1@1+ (1.000000,0.000000) [0.000000|1.000000] "" Vector__XXX
 SG_ LE2_Abschaltstufe  : 1|1@1+ (1.000000,0.000000) [0.000000|1.000000] "" Vector__XXX
 SG_ LE2_Transport_Mode  : 2|1@1+ (1.000000,0.000000) [0.000000|1.000000] "" Vector__XXX
 SG_ LE2_Nachlauftyp  : 4|4@1+ (1.000000,0.000000) [0.000000|15.000000] "" ICAS1_Gateway
 SG_ NM_LE2_Wakeup  : 48|8@1+ (1.000000,0.000000) [0.000000|255.000000] "" Vector__XXX
 SG_ KN_LE2_DiagPfad  : 60|1@1+ (1.000000,0.000000) [0.000000|1.000000] "" ICAS1_Gateway
 SG_ LE2_KD_Fehler  : 63|1@1+ (1.000000,0.000000) [0.000000|1.000000] "" ICAS1_Gateway

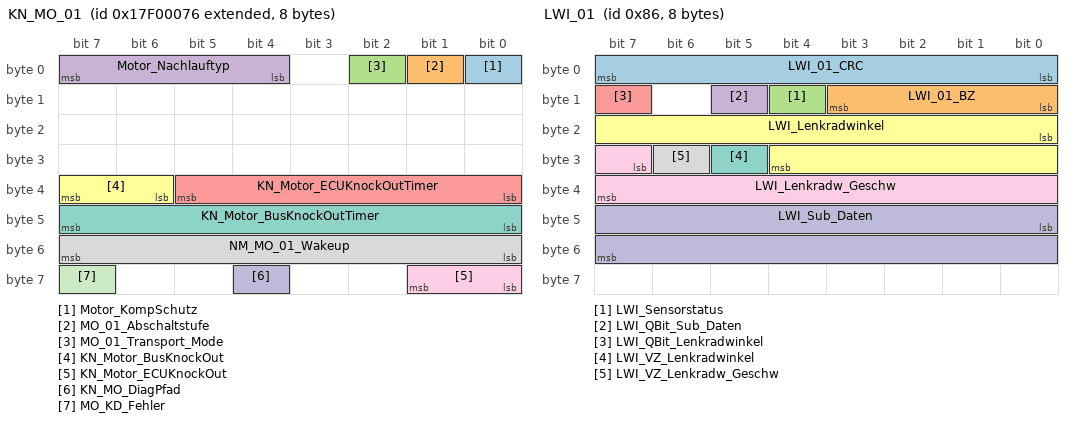
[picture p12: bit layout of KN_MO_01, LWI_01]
BO_ 2549088374 KN_MO_01: 8 Motor_BEV
 SG_ Motor_KompSchutz  : 0|1@1+ (1.000000,0.000000) [0.000000|1.000000] "" Vector__XXX
 SG_ MO_01_Abschaltstufe  : 1|1@1+ (1.000000,0.000000) [0.000000|1.000000] "" Vector__XXX
 SG_ MO_01_Transport_Mode  : 2|1@1+ (1.000000,0.000000) [0.000000|1.000000] "" Vector__XXX
 SG_ Motor_Nachlauftyp  : 4|4@1+ (1.000000,0.000000) [0.000000|15.000000] "" ICAS1_Gateway
 SG_ KN_Motor_ECUKnockOutTimer  : 32|6@1+ (1.000000,0.000000) [0.000000|62.000000] "Unit_Minut" Vector__XXX
 SG_ KN_Motor_BusKnockOut  : 38|2@1+ (1.000000,0.000000) [0.000000|3.000000] "" Vector__XXX
 SG_ KN_Motor_BusKnockOutTimer  : 40|8@1+ (1.000000,0.000000) [0.000000|254.000000] "" Vector__XXX
 SG_ NM_MO_01_Wakeup  : 48|8@1+ (1.000000,0.000000) [0.000000|255.000000] "" Vector__XXX
 SG_ KN_Motor_ECUKnockOut  : 56|2@1+ (1.000000,0.000000) [0.000000|3.000000] "" Vector__XXX
 SG_ KN_MO_DiagPfad  : 60|1@1+ (1.000000,0.000000) [0.000000|1.000000] "" ICAS1_Gateway
 SG_ MO_KD_Fehler  : 63|1@1+ (1.000000,0.000000) [0.000000|1.000000] "" ICAS1_Gateway

BO_ 2621440277 KS_Airbag_01_Req_FD: 16 ICAS1_Gateway
 SG_ KS_Airbag_01_Req_FD_Data  : 0|128@1+ (1.000000,0.000000) [0.000000|340282366920938463463374607431768211456.000000] "" Airbag

BO_ 2621571349 KS_Airbag_01_Resp_FD: 16 Airbag
 SG_ KS_Airbag_01_Resp_FD_Data  : 0|128@1+ (1.000000,0.000000) [0.000000|340282366920938463463374607431768211456.000000] "" ICAS1_Gateway

BO_ 982 Licht_hinten_01: 8 ICAS1_Gateway
 SG_ Licht_hinten_01_BZ  : 0|4@1+ (1.000000,0.000000) [0.000000|15.000000] "" Vector__XXX
 SG_ LH_Aussenlicht_def  : 7|1@1+ (1.000000,0.000000) [0.000000|1.000000] "" Vector__XXX
 SG_ LH_Standlicht_H_aktiv  : 8|1@1+ (1.000000,0.000000) [0.000000|1.000000] "" Vector__XXX
 SG_ LH_Parklicht_HL_aktiv  : 9|1@1+ (1.000000,0.000000) [0.000000|1.000000] "" Vector__XXX
 SG_ LH_Parklicht_HR_aktiv  : 10|1@1+ (1.000000,0.000000) [0.000000|1.000000] "" Vector__XXX
 SG_ LH_Bremslicht_H_aktiv  : 11|1@1+ (1.000000,0.000000) [0.000000|1.000000] "" Vector__XXX
 SG_ LH_Nebelschluss_aktiv  : 12|1@1+ (1.000000,0.000000) [0.000000|1.000000] "" Vector__XXX
 SG_ LH_Rueckfahrlicht_aktiv  : 13|1@1+ (1.000000,0.000000) [0.000000|1.000000] "" Vector__XXX
 SG_ LH_Blinker_HL_akt  : 14|1@1+ (1.000000,0.000000) [0.000000|1.000000] "" Vector__XXX
 SG_ LH_Blinker_HR_akt  : 15|1@1+ (1.000000,0.000000) [0.000000|1.000000] "" Vector__XXX
 SG_ LH_Blinker_li_def  : 16|1@1+ (1.000000,0.000000) [0.000000|1.000000] "" Vector__XXX
 SG_ LH_Bremsl_li_def  : 17|1@1+ (1.000000,0.000000) [0.000000|1.000000] "" Vector__XXX
 SG_ LH_Schlusslicht_li_def  : 18|1@1+ (1.000000,0.000000) [0.000000|1.000000] "" Vector__XXX
 SG_ LH_Rueckf_li_def  : 19|1@1+ (1.000000,0.000000) [0.000000|1.000000] "" Vector__XXX
 SG_ LH_Nebel_li_def  : 20|1@1+ (1.000000,0.000000) [0.000000|1.000000] "" Vector__XXX
 SG_ LH_Schluss_Brems_Nebel_li_def  : 21|1@1+ (1.000000,0.000000) [0.000000|1.000000] "" Vector__XXX
 SG_ LH_Schluss_Brems_Nebel_re_def  : 22|1@1+ (1.000000,0.000000) [0.000000|1.000000] "" Vector__XXX
 SG_ LH_Zusatzschlussl_def  : 23|1@1+ (1.000000,0.000000) [0.000000|1.000000] "" Vector__XXX
 SG_ LH_Schluss_Brems_li_def  : 24|1@1+ (1.000000,0.000000) [0.000000|1.000000] "" Vector__XXX
 SG_ LH_Schluss_Nebel_li_def  : 25|1@1+ (1.000000,0.000000) [0.000000|1.000000] "" Vector__XXX
 SG_ LH_SL_BRL_BLK_li_def  : 26|1@1+ (1.000000,0.000000) [0.000000|1.000000] "" Vector__XXX
 SG_ LH_Brems_Blk_li_def  : 27|1@1+ (1.000000,0.000000) [0.000000|1.000000] "" Vector__XXX
 SG_ LH_Diag_Status_re_def  : 28|1@1+ (1.000000,0.000000) [0.000000|1.000000] "" Vector__XXX
 SG_ LH_Diag_Status_li_def  : 29|1@1+ (1.000000,0.000000) [0.000000|1.000000] "" Vector__XXX
 SG_ LH_Diag_LED_li_def  : 30|1@1+ (1.000000,0.000000) [0.000000|1.000000] "" Vector__XXX
 SG_ LH_Diag_LED_re_def  : 31|1@1+ (1.000000,0.000000) [0.000000|1.000000] "" Vector__XXX
 SG_ LH_Blinker_re_def  : 32|1@1+ (1.000000,0.000000) [0.000000|1.000000] "" Vector__XXX
 SG_ LH_Bremsl_re_def  : 33|1@1+ (1.000000,0.000000) [0.000000|1.000000] "" Vector__XXX
 SG_ LH_Schlusslicht_re_def  : 34|1@1+ (1.000000,0.000000) [0.000000|1.000000] "" Vector__XXX
 SG_ LH_Rueckf_re_def  : 35|1@1+ (1.000000,0.000000) [0.000000|1.000000] "" Vector__XXX
 SG_ LH_Nebel_re_def  : 36|1@1+ (1.000000,0.000000) [0.000000|1.000000] "" Vector__XXX
 SG_ LH_Schluss_Brems_mi_def  : 37|1@1+ (1.000000,0.000000) [0.000000|1.000000] "" Vector__XXX
 SG_ LH_Schluss_Brems_re_def  : 40|1@1+ (1.000000,0.000000) [0.000000|1.000000] "" Vector__XXX
 SG_ LH_Schluss_Nebel_re_def  : 41|1@1+ (1.000000,0.000000) [0.000000|1.000000] "" Vector__XXX
 SG_ LH_SL_BRL_BLK_re_def  : 42|1@1+ (1.000000,0.000000) [0.000000|1.000000] "" Vector__XXX
 SG_ LH_Brems_Blk_re_def  : 43|1@1+ (1.000000,0.000000) [0.000000|1.000000] "" Vector__XXX
 SG_ LH_Kennzl_def  : 48|1@1+ (1.000000,0.000000) [0.000000|1.000000] "" Vector__XXX
 SG_ LH_3_Bremsl_def  : 49|1@1+ (1.000000,0.000000) [0.000000|1.000000] "" Motor_BEV
 SG_ LH_Nebel_mi_def  : 50|1@1+ (1.000000,0.000000) [0.000000|1.000000] "" Vector__XXX
 SG_ LH_Rueckf_mi_def  : 51|1@1+ (1.000000,0.000000) [0.000000|1.000000] "" Vector__XXX
 SG_ LH_Schlusslicht_mi_def  : 52|1@1+ (1.000000,0.000000) [0.000000|1.000000] "" Vector__XXX
 SG_ LH_Bremsl_li_ges_def  : 54|1@1+ (1.000000,0.000000) [0.000000|1.000000] "" Motor_BEV
 SG_ LH_Bremsl_re_ges_def  : 55|1@1+ (1.000000,0.000000) [0.000000|1.000000] "" Motor_BEV
 SG_ LH_Bremsl_mi_def  : 61|1@1+ (1.000000,0.000000) [0.000000|1.000000] "" Vector__XXX
 SG_ BRL_als_SHL  : 62|1@1+ (1.000000,0.000000) [0.000000|1.000000] "" Vector__XXX

BO_ 134 LWI_01: 8 ICAS1_Gateway
 SG_ LWI_01_CRC  : 0|8@1+ (1.000000,0.000000) [0.000000|255.000000] "" Airbag Motor_BEV
 SG_ LWI_01_BZ  : 8|4@1+ (1.000000,0.000000) [0.000000|15.000000] "" Airbag Motor_BEV
 SG_ LWI_Sensorstatus  : 12|1@1+ (1.000000,0.000000) [0.000000|1.000000] "" Airbag Motor_BEV
 SG_ LWI_QBit_Sub_Daten  : 13|1@1+ (1.000000,0.000000) [0.000000|1.000000] "" Vector__XXX
 SG_ LWI_QBit_Lenkradwinkel  : 15|1@1+ (1.000000,0.000000) [0.000000|1.000000] "" Airbag Motor_BEV
 SG_ LWI_Lenkradwinkel  : 16|13@1+ (0.100000,0.000000) [0.000000|800.000000] "Unit_DegreOfArc" Airbag Motor_BEV
 SG_ LWI_VZ_Lenkradwinkel  : 29|1@1+ (1.000000,0.000000) [0.000000|1.000000] "" Airbag Motor_BEV
 SG_ LWI_VZ_Lenkradw_Geschw  : 30|1@1+ (1.000000,0.000000) [0.000000|1.000000] "" Vector__XXX
 SG_ LWI_Lenkradw_Geschw  : 31|9@1+ (5.000000,0.000000) [0.000000|2500.000000] "Unit_DegreOfArcPerSecon" Airbag
 SG_ LWI_Sub_Daten  : 40|16@1+ (1.000000,0.000000) [0.000000|65535.000000] "" Vector__XXX

BO_ 817 MFL_01: 8 ICAS1_Gateway
 SG_ MFL_Zaehler  : 0|4@1+ (1.000000,0.000000) [0.000000|15.000000] "" Vector__XXX
 SG_ MFL_Toggle  : 4|1@1+ (1.000000,0.000000) [0.000000|1.000000] "" Vector__XXX
 SG_ MFL_Lokalaktiv  : 5|1@1+ (1.000000,0.000000) [0.000000|1.000000] "" Vector__XXX
 SG_ MFL_M_Taste  : 6|1@1+ (1.000000,0.000000) [0.000000|1.000000] "" Vector__XXX
 SG_ MFL_Paddle_Verbau  : 7|1@1+ (1.000000,0.000000) [0.000000|1.000000] "" Vector__XXX
 SG_ MFL_Tastencode_1  : 8|8@1+ (1.000000,0.000000) [0.000000|255.000000] "" Vector__XXX
 SG_ MFL_Tastencode_2  : 16|8@1+ (1.000000,0.000000) [0.000000|255.000000] "" Vector__XXX
 SG_ MFL_Eventcode_1  : 24|4@1+ (1.000000,0.000000) [0.000000|15.000000] "" Vector__XXX
 SG_ MFL_Eventcode_2  : 28|4@1+ (1.000000,0.000000) [0.000000|15.000000] "" Vector__XXX
 SG_ MFL_Marke  : 32|4@1+ (1.000000,0.000000) [0.000000|15.000000] "" Vector__XXX
 SG_ MFL_Variante  : 36|4@1+ (1.000000,0.000000) [0.000000|15.000000] "" Vector__XXX
 SG_ MFL_Dummy_0_Signal_1  : 40|8@1+ (1.000000,0.000000) [0.000000|255.000000] "" Vector__XXX
 SG_ MFL_Tip_Down  : 48|1@1+ (1.000000,0.000000) [0.000000|1.000000] "" Motor_BEV
 SG_ MFL_Tip_Up  : 49|1@1+ (1.000000,0.000000) [0.000000|1.000000] "" Motor_BEV
 SG_ MFL_SatModul_links_Err  : 50|1@1+ (1.000000,0.000000) [0.000000|1.000000] "" Vector__XXX
 SG_ MFL_SatModul_rechts_Err  : 51|1@1+ (1.000000,0.000000) [0.000000|1.000000] "" Vector__XXX
 SG_ MFL_Dummy_0_Signal_2  : 52|1@1+ (1.000000,0.000000) [0.000000|1.000000] "" Vector__XXX
 SG_ MFL_Dummy_0_Signal_3  : 53|1@1+ (1.000000,0.000000) [0.000000|1.000000] "" Vector__XXX
 SG_ MFL_LR_HZG_Status  : 54|1@1+ (1.000000,0.000000) [0.000000|1.000000] "" Vector__XXX
 SG_ MFL_LR_HZG_Err  : 55|1@1+ (1.000000,0.000000) [0.000000|1.000000] "" Vector__XXX
 SG_ MFL_Signalhorn  : 56|1@1+ (1.000000,0.000000) [0.000000|1.000000] "" Vector__XXX
 SG_ MFL_Signalhorn_Err  : 57|1@1+ (1.000000,0.000000) [0.000000|1.000000] "" Vector__XXX
 SG_ MFL_Tip_links_Err  : 58|1@1+ (1.000000,0.000000) [0.000000|1.000000] "" Vector__XXX
 SG_ MFL_Tip_rechts_Err  : 59|1@1+ (1.000000,0.000000) [0.000000|1.000000] "" Vector__XXX
 SG_ MFL_Taste_links_Err  : 60|1@1+ (1.000000,0.000000) [0.000000|1.000000] "" Vector__XXX
 SG_ MFL_Taste_rechts_Err  : 61|1@1+ (1.000000,0.000000) [0.000000|1.000000] "" Vector__XXX
 SG_ MFL_ECU_Err  : 62|1@1+ (1.000000,0.000000) [0.000000|1.000000] "" Vector__XXX
 SG_ MFL_Response_Err  : 63|1@1+ (1.000000,0.000000) [0.000000|1.000000] "" Vector__XXX

BO_ 15 MO_SOPC: 1 Motor_BEV
 SG_ MO_SOPC  : 0|1@1+ (1.000000,0.000000) [0.000000|1.000000] "" Vector__XXX

BO_ 1600 Motor_07: 8 Motor_BEV
 SG_ MO_QBit_Ansaugluft_Temp  : 0|1@1+ (1.000000,0.000000) [0.000000|1.000000] "" Vector__XXX
 SG_ MO_QBit_Oel_Temp  : 1|1@1+ (1.000000,0.000000) [0.000000|1.000000] "" Vector__XXX
 SG_ MO_QBit_Kuehlmittel_Temp  : 2|1@1+ (1.000000,0.000000) [0.000000|1.000000] "" Vector__XXX
 SG_ MO_KL15_Abschaltempfehlung  : 3|1@1+ (1.000000,0.000000) [0.000000|1.000000] "" Vector__XXX
 SG_ MO_HYB_Fehler_HV_Netz  : 4|1@1+ (1.000000,0.000000) [0.000000|1.000000] "" Vector__XXX
 SG_ MO_aktives_Getriebeheizen  : 5|1@1+ (1.000000,0.000000) [0.000000|1.000000] "" Vector__XXX
 SG_ MO_Absperrventil_oeffnen  : 6|2@1+ (1.000000,0.000000) [0.000000|3.000000] "" Vector__XXX
 SG_ MO_Ansaugluft_Temp  : 8|8@1+ (0.750000,-48.000000) [-48.000000|141.750000] "Unit_DegreCelsi" Vector__XXX
 SG_ MO_Oel_Temp  : 16|8@1+ (1.000000,-60.000000) [-60.000000|192.000000] "Unit_DegreCelsi" Vector__XXX
 SG_ MO_Kuehlmittel_Temp  : 24|8@1+ (0.750000,-48.000000) [-48.000000|141.750000] "Unit_DegreCelsi" Vector__XXX
 SG_ MO_Hoeheninfo  : 32|8@1+ (0.007810,0.000000) [0.000000|1.983740] "" Vector__XXX
 SG_ MO_Kennfeldk  : 40|1@1+ (1.000000,0.000000) [0.000000|1.000000] "" Vector__XXX
 SG_ MO_Versionsinfo_02  : 41|5@1+ (1.000000,0.000000) [0.000000|31.000000] "" Vector__XXX
 SG_ MO_QBit_Hoeheninfo  : 46|1@1+ (1.000000,0.000000) [0.000000|1.000000] "" Vector__XXX
 SG_ MO_Getriebe_kuehlen  : 47|1@1+ (1.000000,0.000000) [0.000000|1.000000] "" Vector__XXX
 SG_ MO_Mom_Traegheit_02  : 48|5@1+ (0.010000,0.000000) [0.000000|0.310000] "Unit_KiloGramMeterSquar" Vector__XXX
 SG_ MO_Heizungspumpenansteuerung  : 53|4@1+ (10.000000,0.000000) [0.000000|100.000000] "Unit_PerCent" Vector__XXX
 SG_ MO_SpannungsAnf  : 57|1@1+ (1.000000,0.000000) [0.000000|1.000000] "" Vector__XXX
 SG_ MO_Nachlaufzeit_Heizungspumpe  : 58|6@1+ (15.000000,0.000000) [0.000000|945.000000] "Unit_Secon" Vector__XXX

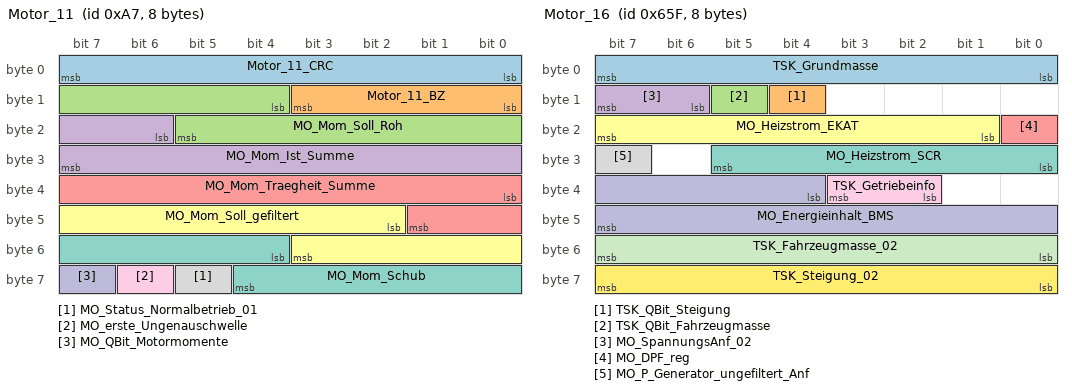
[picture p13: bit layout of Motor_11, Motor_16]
BO_ 167 Motor_11: 8 Motor_BEV
 SG_ Motor_11_CRC  : 0|8@1+ (1.000000,0.000000) [0.000000|255.000000] "" ICAS1_Gateway
 SG_ Motor_11_BZ  : 8|4@1+ (1.000000,0.000000) [0.000000|15.000000] "" ICAS1_Gateway
 SG_ MO_Mom_Soll_Roh  : 12|10@1+ (1.000000,-509.000000) [-509.000000|509.000000] "" ICAS1_Gateway
 SG_ MO_Mom_Ist_Summe  : 22|10@1+ (1.000000,-509.000000) [-509.000000|509.000000] "" ICAS1_Gateway
 SG_ MO_Mom_Traegheit_Summe  : 32|10@1+ (1.000000,-509.000000) [-509.000000|509.000000] "" ICAS1_Gateway
 SG_ MO_Mom_Soll_gefiltert  : 42|10@1+ (1.000000,-509.000000) [-509.000000|509.000000] "" ICAS1_Gateway
 SG_ MO_Mom_Schub  : 52|9@1+ (1.000000,-509.000000) [-509.000000|0.000000] "" ICAS1_Gateway
 SG_ MO_Status_Normalbetrieb_01  : 61|1@1+ (1.000000,0.000000) [0.000000|1.000000] "" ICAS1_Gateway
 SG_ MO_erste_Ungenauschwelle  : 62|1@1+ (1.000000,0.000000) [0.000000|1.000000] "" ICAS1_Gateway
 SG_ MO_QBit_Motormomente  : 63|1@1+ (1.000000,0.000000) [0.000000|1.000000] "" ICAS1_Gateway

BO_ 168 Motor_12: 8 Motor_BEV
 SG_ Motor_12_CRC  : 0|8@1+ (1.000000,0.000000) [0.000000|255.000000] "" ICAS1_Gateway
 SG_ Motor_12_BZ  : 8|4@1+ (1.000000,0.000000) [0.000000|15.000000] "" ICAS1_Gateway
 SG_ MO_Mom_neg_verfuegbar  : 12|9@1+ (1.000000,-509.000000) [-509.000000|0.000000] "" ICAS1_Gateway
 SG_ MO_Mom_Begr_Fahr  : 21|9@1+ (1.000000,0.000000) [0.000000|509.000000] "" ICAS1_Gateway
 SG_ MO_Mom_Begr_Schalt  : 30|10@1+ (1.000000,-509.000000) [-509.000000|509.000000] "" ICAS1_Gateway
 SG_ MO_Momentenintegral_02  : 40|7@1+ (1.000000,0.000000) [0.000000|100.000000] "Unit_PerCent" ICAS1_Gateway
 SG_ MO_QBit_Drehzahl_01  : 47|1@1+ (1.000000,0.000000) [0.000000|1.000000] "" Airbag ICAS1_Gateway LE2
 SG_ MO_Drehzahl_01  : 48|16@1+ (0.250000,0.000000) [0.000000|16383.000000] "Unit_MinutInver" ICAS1_Gateway

BO_ 958 Motor_14: 8 Motor_BEV
 SG_ Motor_14_CRC  : 0|8@1+ (1.000000,0.000000) [0.000000|255.000000] "" ICAS1_Gateway
 SG_ Motor_14_BZ  : 8|4@1+ (1.000000,0.000000) [0.000000|15.000000] "" ICAS1_Gateway
 SG_ MO_StartStopp_Status  : 12|2@1+ (1.000000,0.000000) [0.000000|3.000000] "" ICAS1_Gateway
 SG_ MO_StartStopp_Wiederstart  : 14|1@1+ (1.000000,0.000000) [0.000000|1.000000] "" ICAS1_Gateway
 SG_ MO_StartStopp_Motorstopp  : 15|1@1+ (1.000000,0.000000) [0.000000|1.000000] "" ICAS1_Gateway
 SG_ MO_Freig_Reku  : 16|2@1+ (1.000000,0.000000) [0.000000|3.000000] "" ICAS1_Gateway
 SG_ MO_Kl_75  : 18|1@1+ (1.000000,0.000000) [0.000000|1.000000] "" ICAS1_Gateway
 SG_ MO_Kl_50  : 19|1@1+ (1.000000,0.000000) [0.000000|1.000000] "" ICAS1_Gateway
 SG_ MO_Gangposition  : 20|4@1+ (1.000000,0.000000) [0.000000|15.000000] "" ICAS1_Gateway
 SG_ MO_StartStopp_Fahrerwunsch  : 24|2@1+ (1.000000,0.000000) [0.000000|3.000000] "" ICAS1_Gateway
 SG_ MO_HYB_Fahrbereitschaft  : 26|1@1+ (1.000000,0.000000) [0.000000|1.000000] "" ICAS1_Gateway
 SG_ MO_Ext_E_Fahrt_aktiv  : 27|1@1+ (1.000000,0.000000) [0.000000|1.000000] "" ICAS1_Gateway
 SG_ MO_Fahrer_bremst  : 28|1@1+ (1.000000,0.000000) [0.000000|1.000000] "" Airbag ICAS1_Gateway
 SG_ MO_QBit_Fahrer_bremst  : 29|1@1+ (1.000000,0.000000) [0.000000|1.000000] "" Airbag ICAS1_Gateway
 SG_ MO_BLS  : 30|1@1+ (1.000000,0.000000) [0.000000|1.000000] "" Airbag ICAS1_Gateway
 SG_ MO_Konsistenz_Bremsped  : 31|1@1+ (1.000000,0.000000) [0.000000|1.000000] "" ICAS1_Gateway
 SG_ MO_Timeout_ESP  : 32|1@1+ (1.000000,0.000000) [0.000000|1.000000] "" ICAS1_Gateway
 SG_ MO_Klima_Eingr  : 33|2@1+ (1.000000,0.000000) [0.000000|3.000000] "" ICAS1_Gateway
 SG_ MO_Aussp_Anlass  : 35|1@1+ (1.000000,0.000000) [0.000000|1.000000] "" ICAS1_Gateway
 SG_ MO_Freig_Anlass  : 36|1@1+ (1.000000,0.000000) [0.000000|1.000000] "" ICAS1_Gateway
 SG_ MO_Kuppl_schalter  : 37|1@1+ (1.000000,0.000000) [0.000000|1.000000] "" ICAS1_Gateway
 SG_ MO_Interlock  : 38|1@1+ (1.000000,0.000000) [0.000000|1.000000] "" ICAS1_Gateway
 SG_ MO_Motor_laeuft  : 39|1@1+ (1.000000,0.000000) [0.000000|1.000000] "" ICAS1_Gateway
 SG_ MO_Kickdown  : 40|1@1+ (1.000000,0.000000) [0.000000|1.000000] "" ICAS1_Gateway ICAS1_KommunikationsServer
 SG_ MO_QBit_KL_75  : 41|1@1+ (1.000000,0.000000) [0.000000|1.000000] "" ICAS1_Gateway
 SG_ MO_EKlKomLeiRed  : 42|2@1+ (1.000000,0.000000) [0.000000|3.000000] "" ICAS1_Gateway
 SG_ MO_Handshake_STH  : 44|1@1+ (1.000000,0.000000) [0.000000|1.000000] "" ICAS1_Gateway
 SG_ MO_BKV_Unterdruckwarnung  : 45|1@1+ (1.000000,0.000000) [0.000000|1.000000] "" ICAS1_Gateway
 SG_ MO_Freigabe_Segeln  : 46|1@1+ (1.000000,0.000000) [0.000000|1.000000] "" ICAS1_Gateway
 SG_ MO_PTC_Status  : 47|3@1+ (1.000000,0.000000) [0.000000|7.000000] "" ICAS1_Gateway
 SG_ MO_QBit_Gangposition  : 50|1@1+ (1.000000,0.000000) [0.000000|1.000000] "" ICAS1_Gateway
 SG_ MO_Signalquelle_Gangposition  : 51|1@1+ (1.000000,0.000000) [0.000000|1.000000] "" ICAS1_Gateway
 SG_ MO_Remotestart_Betrieb  : 52|1@1+ (1.000000,0.000000) [0.000000|1.000000] "" ICAS1_Gateway
 SG_ MO_Remotestart_moeglich  : 53|1@1+ (1.000000,0.000000) [0.000000|1.000000] "" ICAS1_Gateway
 SG_ MO_FMAus_aktiv  : 55|1@1+ (1.000000,0.000000) [0.000000|1.000000] "" ICAS1_Gateway
 SG_ MO_FMAus_Startvariante  : 56|2@1+ (1.000000,0.000000) [0.000000|3.000000] "" ICAS1_Gateway
 SG_ MO_BMS_NV_Anf_stuetzen  : 58|1@1+ (1.000000,0.000000) [0.000000|1.000000] "" ICAS1_Gateway
 SG_ MO_Zylinderabschaltung  : 59|2@1+ (1.000000,0.000000) [0.000000|3.000000] "" ICAS1_Gateway
 SG_ MO_HYB_VM_aktiv  : 61|1@1+ (1.000000,0.000000) [0.000000|1.000000] "" ICAS1_Gateway
 SG_ MO_StartVorauss_erfuellt  : 62|2@1+ (1.000000,0.000000) [0.000000|3.000000] "" ICAS1_Gateway

BO_ 1631 Motor_16: 8 Motor_BEV
 SG_ TSK_Grundmasse  : 0|8@1+ (32.000000,0.000000) [0.000000|8128.000000] "Unit_KiloGram" ICAS1_Gateway
 SG_ TSK_QBit_Steigung  : 12|1@1+ (1.000000,0.000000) [0.000000|1.000000] "" ICAS1_Gateway
 SG_ TSK_QBit_Fahrzeugmasse  : 13|1@1+ (1.000000,0.000000) [0.000000|1.000000] "" ICAS1_Gateway
 SG_ MO_SpannungsAnf_02  : 14|2@1+ (1.000000,0.000000) [0.000000|3.000000] "" ICAS1_Gateway
 SG_ MO_DPF_reg  : 16|1@1+ (1.000000,0.000000) [0.000000|1.000000] "" ICAS1_Gateway
 SG_ MO_Heizstrom_EKAT  : 17|7@1+ (1.000000,0.000000) [0.000000|126.000000] "Unit_Amper" ICAS1_Gateway
 SG_ MO_Heizstrom_SCR  : 24|6@1+ (1.000000,0.000000) [0.000000|62.000000] "Unit_Amper" ICAS1_Gateway
 SG_ MO_P_Generator_ungefiltert_Anf  : 31|1@1+ (1.000000,0.000000) [0.000000|1.000000] "" ICAS1_Gateway
 SG_ TSK_Getriebeinfo  : 34|2@1+ (1.000000,0.000000) [0.000000|3.000000] "" ICAS1_Gateway
 SG_ MO_Energieinhalt_BMS  : 36|12@1+ (25.000000,0.000000) [0.000000|102325.000000] "Unit_WattHour" ICAS1_Gateway
 SG_ TSK_Fahrzeugmasse_02  : 48|8@1+ (32.000000,0.000000) [0.000000|8128.000000] "Unit_KiloGram" ICAS1_Gateway
 SG_ TSK_Steigung_02  : 56|8@1+ (0.800000,-101.600000) [-100.800000|101.600000] "Unit_PerCent" ICAS1_Gateway

BO_ 1648 Motor_18: 8 Motor_BEV
 SG_ MO_max_Ladedruck  : 0|6@1+ (0.100000,0.000000) [0.000000|6.300000] "Unit_Bar" ICAS1_Gateway
 SG_ MO_ANC_Kennfeld_Anf  : 6|2@1+ (1.000000,0.000000) [0.000000|3.000000] "" ICAS1_Gateway
 SG_ MO_Bremslicht_Reku  : 8|1@1+ (1.000000,0.000000) [0.000000|1.000000] "" ICAS1_Gateway
 SG_ MO_StartStopp_PopUp  : 9|2@1+ (1.000000,0.000000) [0.000000|3.000000] "" ICAS1_Gateway
 SG_ MO1_Sperr_Info_WFS  : 11|1@1+ (1.000000,0.000000) [0.000000|1.000000] "" ICAS1_Gateway
 SG_ MO1_Freigabe_Info_WFS  : 12|1@1+ (1.000000,0.000000) [0.000000|1.000000] "" ICAS1_Gateway
 SG_ MO_EPCL  : 13|3@1+ (1.000000,0.000000) [0.000000|7.000000] "" ICAS1_Gateway ICAS1_KommunikationsServer
 SG_ MO_Zylabsch_Texte_02  : 16|4@1+ (1.000000,0.000000) [0.000000|15.000000] "" ICAS1_Gateway
 SG_ MO_Fahrzeugtyp  : 20|3@1+ (1.000000,0.000000) [0.000000|7.000000] "" ICAS1_Gateway ICAS1_KommunikationsServer
 SG_ MO_NMAX_Schaltanzeige  : 23|9@1+ (25.000000,0.000000) [0.000000|12775.000000] "Unit_MinutInver" ICAS1_Gateway
 SG_ MO_Abstellzeit  : 32|8@1+ (8.000000,0.000000) [0.000000|2024.000000] "Unit_Minut" ICAS1_Gateway
 SG_ MO_Abstellzeit_Status  : 40|2@1+ (1.000000,0.000000) [0.000000|3.000000] "" ICAS1_Gateway
 SG_ MO1_Freigabe_Verfallsinfo_WFS  : 42|1@1+ (1.000000,0.000000) [0.000000|1.000000] "" ICAS1_Gateway
 SG_ MO_Hybrid_StartStopp_LED  : 43|2@1+ (1.000000,0.000000) [0.000000|3.000000] "" ICAS1_Gateway
 SG_ MO_Fehler_Zylabsch  : 45|2@1+ (1.000000,0.000000) [0.000000|3.000000] "" ICAS1_Gateway
 SG_ MO_Anzahl_Abgesch_Zyl  : 47|3@1+ (1.000000,0.000000) [0.000000|7.000000] "" ICAS1_Gateway
 SG_ MO_Zylabsch_Texte  : 50|2@1+ (1.000000,0.000000) [0.000000|3.000000] "" ICAS1_Gateway
 SG_ MO_Ethanol_BS_Texte  : 52|3@1+ (1.000000,0.000000) [0.000000|7.000000] "" ICAS1_Gateway
 SG_ MO_Drehzahl_Warnung  : 55|1@1+ (1.000000,0.000000) [0.000000|1.000000] "" ICAS1_Gateway
 SG_ MO_obere_Drehzahlgrenze  : 56|8@1+ (50.000000,0.000000) [50.000000|12750.000000] "Unit_MinutInver" ICAS1_Gateway

BU_:  Airbag BAP_Tester ICAS1_Gateway ICAS1_KommunikationsServer LE1 LE2 Motor_BEV Schaltbetaetigung

BO_ 1505 Klima_Sensor_02: 8 ICAS1_Gateway
 SG_ BCM1_Aussen_Temp_ungef  : 0|8@1+ (0.500000,-50.000000) [-50.000000|76.000000] "Unit_DegreCelsi" LE1 LE2 Motor_BEV
 SG_ BCM_Heizungsabsperrventil_Status  : 8|2@1+ (1.000000,0.000000) [0.000000|3.000000] "" Vector__XXX
 SG_ BCM_Heizungspumpe_Status  : 10|2@1+ (1.000000,0.000000) [0.000000|3.000000] "" Vector__XXX
 SG_ BCM_Kompressorkupplung_Status  : 12|2@1+ (1.000000,0.000000) [0.000000|3.000000] "" Vector__XXX
 SG_ BCM1_PTC_stufig_Status  : 28|3@1+ (1.000000,0.000000) [0.000000|7.000000] "" Vector__XXX
 SG_ BCM1_FStatus_Aussentemp_ungef  : 31|1@1+ (1.000000,0.000000) [0.000000|1.000000] "" Vector__XXX
 SG_ BCM1_Kompressorstrom_ist  : 32|8@1+ (4.000000,0.000000) [0.000000|1000.000000] "Unit_MilliAmper" Vector__XXX
 SG_ BCM1_OBD_FStatus_ATemp  : 44|4@1+ (1.000000,0.000000) [0.000000|15.000000] "" Vector__XXX

BO_ 2549088277 KN_Airbag_01: 8 Airbag
 SG_ Airbag_01_KompSchutz  : 0|1@1+ (1.000000,0.000000) [0.000000|1.000000] "" Vector__XXX
 SG_ Airbag_01_Abschaltstufe  : 1|1@1+ (1.000000,0.000000) [0.000000|1.000000] "" Vector__XXX
 SG_ Airbag_01_Transport_Mode  : 2|1@1+ (1.000000,0.000000) [0.000000|1.000000] "" Vector__XXX
 SG_ Airbag_01_Nachlauftyp  : 4|4@1+ (1.000000,0.000000) [0.000000|15.000000] "" ICAS1_Gateway
 SG_ NM_Airbag_01_Wakeup  : 48|8@1+ (1.000000,0.000000) [0.000000|255.000000] "" Vector__XXX
 SG_ KN_AB_DiagPfad  : 60|1@1+ (1.000000,0.000000) [0.000000|1.000000] "" ICAS1_Gateway
 SG_ AB_KD_Fehler  : 63|1@1+ (1.000000,0.000000) [0.000000|1.000000] "" ICAS1_Gateway

BO_ 2549088380 KN_EMotor_01: 8 LE1
 SG_ EMotor_KompSchutz  : 0|1@1+ (1.000000,0.000000) [0.000000|1.000000] "" Vector__XXX
 SG_ EMotor_01_Abschaltstufe  : 1|1@1+ (1.000000,0.000000) [0.000000|1.000000] "" Vector__XXX
 SG_ EMotor_01_Transport_Mode  : 2|1@1+ (1.000000,0.000000) [0.000000|1.000000] "" Vector__XXX
 SG_ EMotor_Nachlauftyp  : 4|4@1+ (1.000000,0.000000) [0.000000|15.000000] "" ICAS1_Gateway
 SG_ NM_EMotor_01_Wakeup  : 48|8@1+ (1.000000,0.000000) [0.000000|255.000000] "" Vector__XXX
 SG_ KN_EM_HYB_DiagPfad  : 60|1@1+ (1.000000,0.000000) [0.000000|1.000000] "" ICAS1_Gateway
 SG_ EM_HYB_KD_Fehler  : 63|1@1+ (1.000000,0.000000) [0.000000|1.000000] "" ICAS1_Gateway

BO_ 2549088272 KN_Gateway: 8 ICAS1_Gateway
 SG_ Gateway_KompSchutz  : 0|1@1+ (1.000000,0.000000) [0.000000|1.000000] "" Vector__XXX
 SG_ Gateway_Abschaltstufe  : 1|1@1+ (1.000000,0.000000) [0.000000|1.000000] "" Vector__XXX
 SG_ Gateway_Transport_Mode  : 2|1@1+ (1.000000,0.000000) [0.000000|1.000000] "" Vector__XXX
 SG_ Gateway_Nachlauftyp  : 4|4@1+ (1.000000,0.000000) [0.000000|15.000000] "" Vector__XXX
 SG_ NM_Gateway_Wakeup  : 48|8@1+ (1.000000,0.000000) [0.000000|255.000000] "" Vector__XXX
 SG_ KN_GW_DiagPfad  : 60|1@1+ (1.000000,0.000000) [0.000000|1.000000] "" Vector__XXX
 SG_ GW_KD_Fehler  : 63|1@1+ (1.000000,0.000000) [0.000000|1.000000] "" Vector__XXX

BO_ 2549088440 KN_LE2: 8 LE2
 SG_ LE2_KompSchutz  : 0|1@1+ (1.000000,0.000000) [0.000000|1.000000] "" Vector__XXX
 SG_ LE2_Abschaltstufe  : 1|1@1+ (1.000000,0.000000) [0.000000|1.000000] "" Vector__XXX
 SG_ LE2_Transport_Mode  : 2|1@1+ (1.000000,0.000000) [0.000000|1.000000] "" Vector__XXX
 SG_ LE2_Nachlauftyp  : 4|4@1+ (1.000000,0.000000) [0.000000|15.000000] "" ICAS1_Gateway
 SG_ NM_LE2_Wakeup  : 48|8@1+ (1.000000,0.000000) [0.000000|255.000000] "" Vector__XXX
 SG_ KN_LE2_DiagPfad  : 60|1@1+ (1.000000,0.000000) [0.000000|1.000000] "" ICAS1_Gateway
 SG_ LE2_KD_Fehler  : 63|1@1+ (1.000000,0.000000) [0.000000|1.000000] "" ICAS1_Gateway

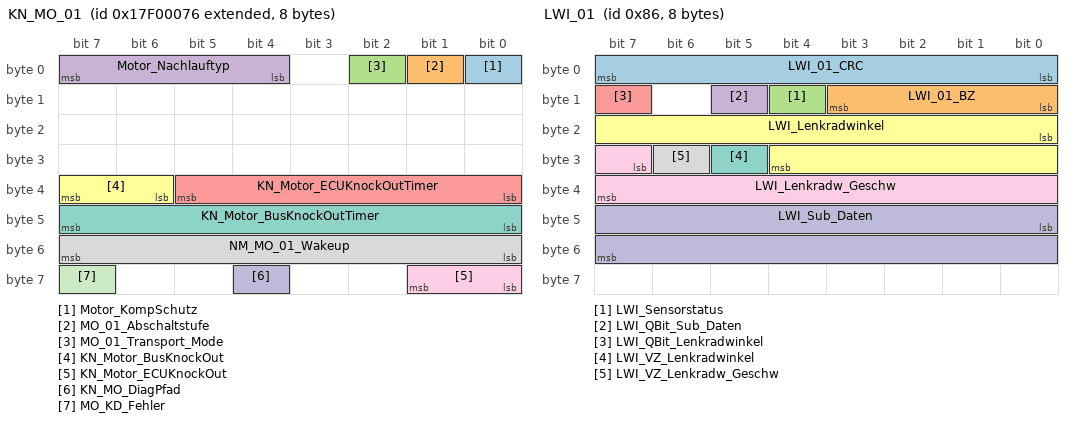
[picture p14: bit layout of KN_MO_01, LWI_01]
BO_ 2549088374 KN_MO_01: 8 Motor_BEV
 SG_ Motor_KompSchutz  : 0|1@1+ (1.000000,0.000000) [0.000000|1.000000] "" Vector__XXX
 SG_ MO_01_Abschaltstufe  : 1|1@1+ (1.000000,0.000000) [0.000000|1.000000] "" Vector__XXX
 SG_ MO_01_Transport_Mode  : 2|1@1+ (1.000000,0.000000) [0.000000|1.000000] "" Vector__XXX
 SG_ Motor_Nachlauftyp  : 4|4@1+ (1.000000,0.000000) [0.000000|15.000000] "" ICAS1_Gateway
 SG_ KN_Motor_ECUKnockOutTimer  : 32|6@1+ (1.000000,0.000000) [0.000000|62.000000] "Unit_Minut" Vector__XXX
 SG_ KN_Motor_BusKnockOut  : 38|2@1+ (1.000000,0.000000) [0.000000|3.000000] "" Vector__XXX
 SG_ KN_Motor_BusKnockOutTimer  : 40|8@1+ (1.000000,0.000000) [0.000000|254.000000] "" Vector__XXX
 SG_ NM_MO_01_Wakeup  : 48|8@1+ (1.000000,0.000000) [0.000000|255.000000] "" Vector__XXX
 SG_ KN_Motor_ECUKnockOut  : 56|2@1+ (1.000000,0.000000) [0.000000|3.000000] "" Vector__XXX
 SG_ KN_MO_DiagPfad  : 60|1@1+ (1.000000,0.000000) [0.000000|1.000000] "" ICAS1_Gateway
 SG_ MO_KD_Fehler  : 63|1@1+ (1.000000,0.000000) [0.000000|1.000000] "" ICAS1_Gateway

BO_ 2621440277 KS_Airbag_01_Req_FD: 16 ICAS1_Gateway
 SG_ KS_Airbag_01_Req_FD_Data  : 0|128@1+ (1.000000,0.000000) [0.000000|340282366920938463463374607431768211456.000000] "" Airbag

BO_ 2621571349 KS_Airbag_01_Resp_FD: 16 Airbag
 SG_ KS_Airbag_01_Resp_FD_Data  : 0|128@1+ (1.000000,0.000000) [0.000000|340282366920938463463374607431768211456.000000] "" ICAS1_Gateway

BO_ 982 Licht_hinten_01: 8 ICAS1_Gateway
 SG_ Licht_hinten_01_BZ  : 0|4@1+ (1.000000,0.000000) [0.000000|15.000000] "" Vector__XXX
 SG_ LH_Aussenlicht_def  : 7|1@1+ (1.000000,0.000000) [0.000000|1.000000] "" Vector__XXX
 SG_ LH_Standlicht_H_aktiv  : 8|1@1+ (1.000000,0.000000) [0.000000|1.000000] "" Vector__XXX
 SG_ LH_Parklicht_HL_aktiv  : 9|1@1+ (1.000000,0.000000) [0.000000|1.000000] "" Vector__XXX
 SG_ LH_Parklicht_HR_aktiv  : 10|1@1+ (1.000000,0.000000) [0.000000|1.000000] "" Vector__XXX
 SG_ LH_Bremslicht_H_aktiv  : 11|1@1+ (1.000000,0.000000) [0.000000|1.000000] "" Vector__XXX
 SG_ LH_Nebelschluss_aktiv  : 12|1@1+ (1.000000,0.000000) [0.000000|1.000000] "" Vector__XXX
 SG_ LH_Rueckfahrlicht_aktiv  : 13|1@1+ (1.000000,0.000000) [0.000000|1.000000] "" Vector__XXX
 SG_ LH_Blinker_HL_akt  : 14|1@1+ (1.000000,0.000000) [0.000000|1.000000] "" Vector__XXX
 SG_ LH_Blinker_HR_akt  : 15|1@1+ (1.000000,0.000000) [0.000000|1.000000] "" Vector__XXX
 SG_ LH_Blinker_li_def  : 16|1@1+ (1.000000,0.000000) [0.000000|1.000000] "" Vector__XXX
 SG_ LH_Bremsl_li_def  : 17|1@1+ (1.000000,0.000000) [0.000000|1.000000] "" Vector__XXX
 SG_ LH_Schlusslicht_li_def  : 18|1@1+ (1.000000,0.000000) [0.000000|1.000000] "" Vector__XXX
 SG_ LH_Rueckf_li_def  : 19|1@1+ (1.000000,0.000000) [0.000000|1.000000] "" Vector__XXX
 SG_ LH_Nebel_li_def  : 20|1@1+ (1.000000,0.000000) [0.000000|1.000000] "" Vector__XXX
 SG_ LH_Schluss_Brems_Nebel_li_def  : 21|1@1+ (1.000000,0.000000) [0.000000|1.000000] "" Vector__XXX
 SG_ LH_Schluss_Brems_Nebel_re_def  : 22|1@1+ (1.000000,0.000000) [0.000000|1.000000] "" Vector__XXX
 SG_ LH_Zusatzschlussl_def  : 23|1@1+ (1.000000,0.000000) [0.000000|1.000000] "" Vector__XXX
 SG_ LH_Schluss_Brems_li_def  : 24|1@1+ (1.000000,0.000000) [0.000000|1.000000] "" Vector__XXX
 SG_ LH_Schluss_Nebel_li_def  : 25|1@1+ (1.000000,0.000000) [0.000000|1.000000] "" Vector__XXX
 SG_ LH_SL_BRL_BLK_li_def  : 26|1@1+ (1.000000,0.000000) [0.000000|1.000000] "" Vector__XXX
 SG_ LH_Brems_Blk_li_def  : 27|1@1+ (1.000000,0.000000) [0.000000|1.000000] "" Vector__XXX
 SG_ LH_Diag_Status_re_def  : 28|1@1+ (1.000000,0.000000) [0.000000|1.000000] "" Vector__XXX
 SG_ LH_Diag_Status_li_def  : 29|1@1+ (1.000000,0.000000) [0.000000|1.000000] "" Vector__XXX
 SG_ LH_Diag_LED_li_def  : 30|1@1+ (1.000000,0.000000) [0.000000|1.000000] "" Vector__XXX
 SG_ LH_Diag_LED_re_def  : 31|1@1+ (1.000000,0.000000) [0.000000|1.000000] "" Vector__XXX
 SG_ LH_Blinker_re_def  : 32|1@1+ (1.000000,0.000000) [0.000000|1.000000] "" Vector__XXX
 SG_ LH_Bremsl_re_def  : 33|1@1+ (1.000000,0.000000) [0.000000|1.000000] "" Vector__XXX
 SG_ LH_Schlusslicht_re_def  : 34|1@1+ (1.000000,0.000000) [0.000000|1.000000] "" Vector__XXX
 SG_ LH_Rueckf_re_def  : 35|1@1+ (1.000000,0.000000) [0.000000|1.000000] "" Vector__XXX
 SG_ LH_Nebel_re_def  : 36|1@1+ (1.000000,0.000000) [0.000000|1.000000] "" Vector__XXX
 SG_ LH_Schluss_Brems_mi_def  : 37|1@1+ (1.000000,0.000000) [0.000000|1.000000] "" Vector__XXX
 SG_ LH_Schluss_Brems_re_def  : 40|1@1+ (1.000000,0.000000) [0.000000|1.000000] "" Vector__XXX
 SG_ LH_Schluss_Nebel_re_def  : 41|1@1+ (1.000000,0.000000) [0.000000|1.000000] "" Vector__XXX
 SG_ LH_SL_BRL_BLK_re_def  : 42|1@1+ (1.000000,0.000000) [0.000000|1.000000] "" Vector__XXX
 SG_ LH_Brems_Blk_re_def  : 43|1@1+ (1.000000,0.000000) [0.000000|1.000000] "" Vector__XXX
 SG_ LH_Kennzl_def  : 48|1@1+ (1.000000,0.000000) [0.000000|1.000000] "" Vector__XXX
 SG_ LH_3_Bremsl_def  : 49|1@1+ (1.000000,0.000000) [0.000000|1.000000] "" Motor_BEV
 SG_ LH_Nebel_mi_def  : 50|1@1+ (1.000000,0.000000) [0.000000|1.000000] "" Vector__XXX
 SG_ LH_Rueckf_mi_def  : 51|1@1+ (1.000000,0.000000) [0.000000|1.000000] "" Vector__XXX
 SG_ LH_Schlusslicht_mi_def  : 52|1@1+ (1.000000,0.000000) [0.000000|1.000000] "" Vector__XXX
 SG_ LH_Bremsl_li_ges_def  : 54|1@1+ (1.000000,0.000000) [0.000000|1.000000] "" Motor_BEV
 SG_ LH_Bremsl_re_ges_def  : 55|1@1+ (1.000000,0.000000) [0.000000|1.000000] "" Motor_BEV
 SG_ LH_Bremsl_mi_def  : 61|1@1+ (1.000000,0.000000) [0.000000|1.000000] "" Vector__XXX
 SG_ BRL_als_SHL  : 62|1@1+ (1.000000,0.000000) [0.000000|1.000000] "" Vector__XXX

BO_ 134 LWI_01: 8 ICAS1_Gateway
 SG_ LWI_01_CRC  : 0|8@1+ (1.000000,0.000000) [0.000000|255.000000] "" Airbag Motor_BEV
 SG_ LWI_01_BZ  : 8|4@1+ (1.000000,0.000000) [0.000000|15.000000] "" Airbag Motor_BEV
 SG_ LWI_Sensorstatus  : 12|1@1+ (1.000000,0.000000) [0.000000|1.000000] "" Airbag Motor_BEV
 SG_ LWI_QBit_Sub_Daten  : 13|1@1+ (1.000000,0.000000) [0.000000|1.000000] "" Vector__XXX
 SG_ LWI_QBit_Lenkradwinkel  : 15|1@1+ (1.000000,0.000000) [0.000000|1.000000] "" Airbag Motor_BEV
 SG_ LWI_Lenkradwinkel  : 16|13@1+ (0.100000,0.000000) [0.000000|800.000000] "Unit_DegreOfArc" Airbag Motor_BEV
 SG_ LWI_VZ_Lenkradwinkel  : 29|1@1+ (1.000000,0.000000) [0.000000|1.000000] "" Airbag Motor_BEV
 SG_ LWI_VZ_Lenkradw_Geschw  : 30|1@1+ (1.000000,0.000000) [0.000000|1.000000] "" Vector__XXX
 SG_ LWI_Lenkradw_Geschw  : 31|9@1+ (5.000000,0.000000) [0.000000|2500.000000] "Unit_DegreOfArcPerSecon" Airbag
 SG_ LWI_Sub_Daten  : 40|16@1+ (1.000000,0.000000) [0.000000|65535.000000] "" Vector__XXX

BO_ 817 MFL_01: 8 ICAS1_Gateway
 SG_ MFL_Zaehler  : 0|4@1+ (1.000000,0.000000) [0.000000|15.000000] "" Vector__XXX
 SG_ MFL_Toggle  : 4|1@1+ (1.000000,0.000000) [0.000000|1.000000] "" Vector__XXX
 SG_ MFL_Lokalaktiv  : 5|1@1+ (1.000000,0.000000) [0.000000|1.000000] "" Vector__XXX
 SG_ MFL_M_Taste  : 6|1@1+ (1.000000,0.000000) [0.000000|1.000000] "" Vector__XXX
 SG_ MFL_Paddle_Verbau  : 7|1@1+ (1.000000,0.000000) [0.000000|1.000000] "" Vector__XXX
 SG_ MFL_Tastencode_1  : 8|8@1+ (1.000000,0.000000) [0.000000|255.000000] "" Vector__XXX
 SG_ MFL_Tastencode_2  : 16|8@1+ (1.000000,0.000000) [0.000000|255.000000] "" Vector__XXX
 SG_ MFL_Eventcode_1  : 24|4@1+ (1.000000,0.000000) [0.000000|15.000000] "" Vector__XXX
 SG_ MFL_Eventcode_2  : 28|4@1+ (1.000000,0.000000) [0.000000|15.000000] "" Vector__XXX
 SG_ MFL_Marke  : 32|4@1+ (1.000000,0.000000) [0.000000|15.000000] "" Vector__XXX
 SG_ MFL_Variante  : 36|4@1+ (1.000000,0.000000) [0.000000|15.000000] "" Vector__XXX
 SG_ MFL_Dummy_0_Signal_1  : 40|8@1+ (1.000000,0.000000) [0.000000|255.000000] "" Vector__XXX
 SG_ MFL_Tip_Down  : 48|1@1+ (1.000000,0.000000) [0.000000|1.000000] "" Motor_BEV
 SG_ MFL_Tip_Up  : 49|1@1+ (1.000000,0.000000) [0.000000|1.000000] "" Motor_BEV
 SG_ MFL_SatModul_links_Err  : 50|1@1+ (1.000000,0.000000) [0.000000|1.000000] "" Vector__XXX
 SG_ MFL_SatModul_rechts_Err  : 51|1@1+ (1.000000,0.000000) [0.000000|1.000000] "" Vector__XXX
 SG_ MFL_Dummy_0_Signal_2  : 52|1@1+ (1.000000,0.000000) [0.000000|1.000000] "" Vector__XXX
 SG_ MFL_Dummy_0_Signal_3  : 53|1@1+ (1.000000,0.000000) [0.000000|1.000000] "" Vector__XXX
 SG_ MFL_LR_HZG_Status  : 54|1@1+ (1.000000,0.000000) [0.000000|1.000000] "" Vector__XXX
 SG_ MFL_LR_HZG_Err  : 55|1@1+ (1.000000,0.000000) [0.000000|1.000000] "" Vector__XXX
 SG_ MFL_Signalhorn  : 56|1@1+ (1.000000,0.000000) [0.000000|1.000000] "" Vector__XXX
 SG_ MFL_Signalhorn_Err  : 57|1@1+ (1.000000,0.000000) [0.000000|1.000000] "" Vector__XXX
 SG_ MFL_Tip_links_Err  : 58|1@1+ (1.000000,0.000000) [0.000000|1.000000] "" Vector__XXX
 SG_ MFL_Tip_rechts_Err  : 59|1@1+ (1.000000,0.000000) [0.000000|1.000000] "" Vector__XXX
 SG_ MFL_Taste_links_Err  : 60|1@1+ (1.000000,0.000000) [0.000000|1.000000] "" Vector__XXX
 SG_ MFL_Taste_rechts_Err  : 61|1@1+ (1.000000,0.000000) [0.000000|1.000000] "" Vector__XXX
 SG_ MFL_ECU_Err  : 62|1@1+ (1.000000,0.000000) [0.000000|1.000000] "" Vector__XXX
 SG_ MFL_Response_Err  : 63|1@1+ (1.000000,0.000000) [0.000000|1.000000] "" Vector__XXX

BO_ 15 MO_SOPC: 1 Motor_BEV
 SG_ MO_SOPC  : 0|1@1+ (1.000000,0.000000) [0.000000|1.000000] "" Vector__XXX

BO_ 1600 Motor_07: 8 Motor_BEV
 SG_ MO_QBit_Ansaugluft_Temp  : 0|1@1+ (1.000000,0.000000) [0.000000|1.000000] "" Vector__XXX
 SG_ MO_QBit_Oel_Temp  : 1|1@1+ (1.000000,0.000000) [0.000000|1.000000] "" Vector__XXX
 SG_ MO_QBit_Kuehlmittel_Temp  : 2|1@1+ (1.000000,0.000000) [0.000000|1.000000] "" Vector__XXX
 SG_ MO_KL15_Abschaltempfehlung  : 3|1@1+ (1.000000,0.000000) [0.000000|1.000000] "" Vector__XXX
 SG_ MO_HYB_Fehler_HV_Netz  : 4|1@1+ (1.000000,0.000000) [0.000000|1.000000] "" Vector__XXX
 SG_ MO_aktives_Getriebeheizen  : 5|1@1+ (1.000000,0.000000) [0.000000|1.000000] "" Vector__XXX
 SG_ MO_Absperrventil_oeffnen  : 6|2@1+ (1.000000,0.000000) [0.000000|3.000000] "" Vector__XXX
 SG_ MO_Ansaugluft_Temp  : 8|8@1+ (0.750000,-48.000000) [-48.000000|141.750000] "Unit_DegreCelsi" Vector__XXX
 SG_ MO_Oel_Temp  : 16|8@1+ (1.000000,-60.000000) [-60.000000|192.000000] "Unit_DegreCelsi" Vector__XXX
 SG_ MO_Kuehlmittel_Temp  : 24|8@1+ (0.750000,-48.000000) [-48.000000|141.750000] "Unit_DegreCelsi" Vector__XXX
 SG_ MO_Hoeheninfo  : 32|8@1+ (0.007810,0.000000) [0.000000|1.983740] "" Vector__XXX
 SG_ MO_Kennfeldk  : 40|1@1+ (1.000000,0.000000) [0.000000|1.000000] "" Vector__XXX
 SG_ MO_Versionsinfo_02  : 41|5@1+ (1.000000,0.000000) [0.000000|31.000000] "" Vector__XXX
 SG_ MO_QBit_Hoeheninfo  : 46|1@1+ (1.000000,0.000000) [0.000000|1.000000] "" Vector__XXX
 SG_ MO_Getriebe_kuehlen  : 47|1@1+ (1.000000,0.000000) [0.000000|1.000000] "" Vector__XXX
 SG_ MO_Mom_Traegheit_02  : 48|5@1+ (0.010000,0.000000) [0.000000|0.310000] "Unit_KiloGramMeterSquar" Vector__XXX
 SG_ MO_Heizungspumpenansteuerung  : 53|4@1+ (10.000000,0.000000) [0.000000|100.000000] "Unit_PerCent" Vector__XXX
 SG_ MO_SpannungsAnf  : 57|1@1+ (1.000000,0.000000) [0.000000|1.000000] "" Vector__XXX
 SG_ MO_Nachlaufzeit_Heizungspumpe  : 58|6@1+ (15.000000,0.000000) [0.000000|945.000000] "Unit_Secon" Vector__XXX

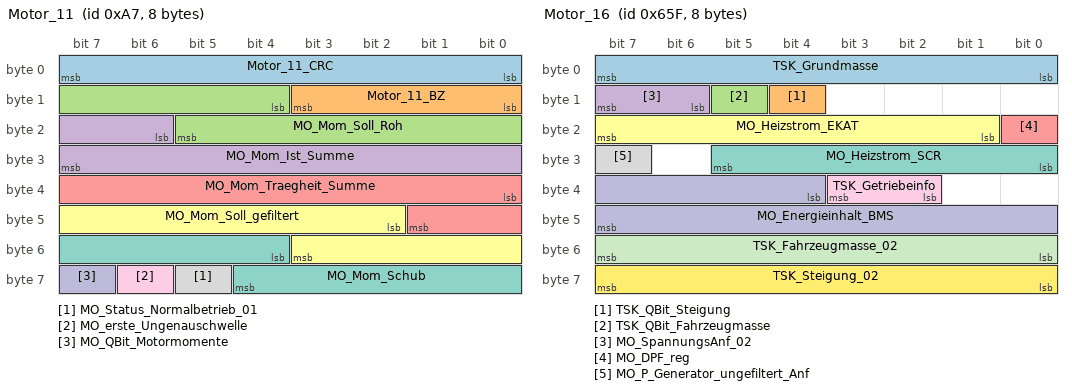
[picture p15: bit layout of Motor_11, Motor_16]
BO_ 167 Motor_11: 8 Motor_BEV
 SG_ Motor_11_CRC  : 0|8@1+ (1.000000,0.000000) [0.000000|255.000000] "" ICAS1_Gateway
 SG_ Motor_11_BZ  : 8|4@1+ (1.000000,0.000000) [0.000000|15.000000] "" ICAS1_Gateway
 SG_ MO_Mom_Soll_Roh  : 12|10@1+ (1.000000,-509.000000) [-509.000000|509.000000] "" ICAS1_Gateway
 SG_ MO_Mom_Ist_Summe  : 22|10@1+ (1.000000,-509.000000) [-509.000000|509.000000] "" ICAS1_Gateway
 SG_ MO_Mom_Traegheit_Summe  : 32|10@1+ (1.000000,-509.000000) [-509.000000|509.000000] "" ICAS1_Gateway
 SG_ MO_Mom_Soll_gefiltert  : 42|10@1+ (1.000000,-509.000000) [-509.000000|509.000000] "" ICAS1_Gateway
 SG_ MO_Mom_Schub  : 52|9@1+ (1.000000,-509.000000) [-509.000000|0.000000] "" ICAS1_Gateway
 SG_ MO_Status_Normalbetrieb_01  : 61|1@1+ (1.000000,0.000000) [0.000000|1.000000] "" ICAS1_Gateway
 SG_ MO_erste_Ungenauschwelle  : 62|1@1+ (1.000000,0.000000) [0.000000|1.000000] "" ICAS1_Gateway
 SG_ MO_QBit_Motormomente  : 63|1@1+ (1.000000,0.000000) [0.000000|1.000000] "" ICAS1_Gateway

BO_ 168 Motor_12: 8 Motor_BEV
 SG_ Motor_12_CRC  : 0|8@1+ (1.000000,0.000000) [0.000000|255.000000] "" ICAS1_Gateway
 SG_ Motor_12_BZ  : 8|4@1+ (1.000000,0.000000) [0.000000|15.000000] "" ICAS1_Gateway
 SG_ MO_Mom_neg_verfuegbar  : 12|9@1+ (1.000000,-509.000000) [-509.000000|0.000000] "" ICAS1_Gateway
 SG_ MO_Mom_Begr_Fahr  : 21|9@1+ (1.000000,0.000000) [0.000000|509.000000] "" ICAS1_Gateway
 SG_ MO_Mom_Begr_Schalt  : 30|10@1+ (1.000000,-509.000000) [-509.000000|509.000000] "" ICAS1_Gateway
 SG_ MO_Momentenintegral_02  : 40|7@1+ (1.000000,0.000000) [0.000000|100.000000] "Unit_PerCent" ICAS1_Gateway
 SG_ MO_QBit_Drehzahl_01  : 47|1@1+ (1.000000,0.000000) [0.000000|1.000000] "" Airbag ICAS1_Gateway LE2
 SG_ MO_Drehzahl_01  : 48|16@1+ (0.250000,0.000000) [0.000000|16383.000000] "Unit_MinutInver" ICAS1_Gateway

BO_ 958 Motor_14: 8 Motor_BEV
 SG_ Motor_14_CRC  : 0|8@1+ (1.000000,0.000000) [0.000000|255.000000] "" ICAS1_Gateway
 SG_ Motor_14_BZ  : 8|4@1+ (1.000000,0.000000) [0.000000|15.000000] "" ICAS1_Gateway
 SG_ MO_StartStopp_Status  : 12|2@1+ (1.000000,0.000000) [0.000000|3.000000] "" ICAS1_Gateway
 SG_ MO_StartStopp_Wiederstart  : 14|1@1+ (1.000000,0.000000) [0.000000|1.000000] "" ICAS1_Gateway
 SG_ MO_StartStopp_Motorstopp  : 15|1@1+ (1.000000,0.000000) [0.000000|1.000000] "" ICAS1_Gateway
 SG_ MO_Freig_Reku  : 16|2@1+ (1.000000,0.000000) [0.000000|3.000000] "" ICAS1_Gateway
 SG_ MO_Kl_75  : 18|1@1+ (1.000000,0.000000) [0.000000|1.000000] "" ICAS1_Gateway
 SG_ MO_Kl_50  : 19|1@1+ (1.000000,0.000000) [0.000000|1.000000] "" ICAS1_Gateway
 SG_ MO_Gangposition  : 20|4@1+ (1.000000,0.000000) [0.000000|15.000000] "" ICAS1_Gateway
 SG_ MO_StartStopp_Fahrerwunsch  : 24|2@1+ (1.000000,0.000000) [0.000000|3.000000] "" ICAS1_Gateway
 SG_ MO_HYB_Fahrbereitschaft  : 26|1@1+ (1.000000,0.000000) [0.000000|1.000000] "" ICAS1_Gateway
 SG_ MO_Ext_E_Fahrt_aktiv  : 27|1@1+ (1.000000,0.000000) [0.000000|1.000000] "" ICAS1_Gateway
 SG_ MO_Fahrer_bremst  : 28|1@1+ (1.000000,0.000000) [0.000000|1.000000] "" Airbag ICAS1_Gateway
 SG_ MO_QBit_Fahrer_bremst  : 29|1@1+ (1.000000,0.000000) [0.000000|1.000000] "" Airbag ICAS1_Gateway
 SG_ MO_BLS  : 30|1@1+ (1.000000,0.000000) [0.000000|1.000000] "" Airbag ICAS1_Gateway
 SG_ MO_Konsistenz_Bremsped  : 31|1@1+ (1.000000,0.000000) [0.000000|1.000000] "" ICAS1_Gateway
 SG_ MO_Timeout_ESP  : 32|1@1+ (1.000000,0.000000) [0.000000|1.000000] "" ICAS1_Gateway
 SG_ MO_Klima_Eingr  : 33|2@1+ (1.000000,0.000000) [0.000000|3.000000] "" ICAS1_Gateway
 SG_ MO_Aussp_Anlass  : 35|1@1+ (1.000000,0.000000) [0.000000|1.000000] "" ICAS1_Gateway
 SG_ MO_Freig_Anlass  : 36|1@1+ (1.000000,0.000000) [0.000000|1.000000] "" ICAS1_Gateway
 SG_ MO_Kuppl_schalter  : 37|1@1+ (1.000000,0.000000) [0.000000|1.000000] "" ICAS1_Gateway
 SG_ MO_Interlock  : 38|1@1+ (1.000000,0.000000) [0.000000|1.000000] "" ICAS1_Gateway
 SG_ MO_Motor_laeuft  : 39|1@1+ (1.000000,0.000000) [0.000000|1.000000] "" ICAS1_Gateway
 SG_ MO_Kickdown  : 40|1@1+ (1.000000,0.000000) [0.000000|1.000000] "" ICAS1_Gateway ICAS1_KommunikationsServer
 SG_ MO_QBit_KL_75  : 41|1@1+ (1.000000,0.000000) [0.000000|1.000000] "" ICAS1_Gateway
 SG_ MO_EKlKomLeiRed  : 42|2@1+ (1.000000,0.000000) [0.000000|3.000000] "" ICAS1_Gateway
 SG_ MO_Handshake_STH  : 44|1@1+ (1.000000,0.000000) [0.000000|1.000000] "" ICAS1_Gateway
 SG_ MO_BKV_Unterdruckwarnung  : 45|1@1+ (1.000000,0.000000) [0.000000|1.000000] "" ICAS1_Gateway
 SG_ MO_Freigabe_Segeln  : 46|1@1+ (1.000000,0.000000) [0.000000|1.000000] "" ICAS1_Gateway
 SG_ MO_PTC_Status  : 47|3@1+ (1.000000,0.000000) [0.000000|7.000000] "" ICAS1_Gateway
 SG_ MO_QBit_Gangposition  : 50|1@1+ (1.000000,0.000000) [0.000000|1.000000] "" ICAS1_Gateway
 SG_ MO_Signalquelle_Gangposition  : 51|1@1+ (1.000000,0.000000) [0.000000|1.000000] "" ICAS1_Gateway
 SG_ MO_Remotestart_Betrieb  : 52|1@1+ (1.000000,0.000000) [0.000000|1.000000] "" ICAS1_Gateway
 SG_ MO_Remotestart_moeglich  : 53|1@1+ (1.000000,0.000000) [0.000000|1.000000] "" ICAS1_Gateway
 SG_ MO_FMAus_aktiv  : 55|1@1+ (1.000000,0.000000) [0.000000|1.000000] "" ICAS1_Gateway
 SG_ MO_FMAus_Startvariante  : 56|2@1+ (1.000000,0.000000) [0.000000|3.000000] "" ICAS1_Gateway
 SG_ MO_BMS_NV_Anf_stuetzen  : 58|1@1+ (1.000000,0.000000) [0.000000|1.000000] "" ICAS1_Gateway
 SG_ MO_Zylinderabschaltung  : 59|2@1+ (1.000000,0.000000) [0.000000|3.000000] "" ICAS1_Gateway
 SG_ MO_HYB_VM_aktiv  : 61|1@1+ (1.000000,0.000000) [0.000000|1.000000] "" ICAS1_Gateway
 SG_ MO_StartVorauss_erfuellt  : 62|2@1+ (1.000000,0.000000) [0.000000|3.000000] "" ICAS1_Gateway

BO_ 1631 Motor_16: 8 Motor_BEV
 SG_ TSK_Grundmasse  : 0|8@1+ (32.000000,0.000000) [0.000000|8128.000000] "Unit_KiloGram" ICAS1_Gateway
 SG_ TSK_QBit_Steigung  : 12|1@1+ (1.000000,0.000000) [0.000000|1.000000] "" ICAS1_Gateway
 SG_ TSK_QBit_Fahrzeugmasse  : 13|1@1+ (1.000000,0.000000) [0.000000|1.000000] "" ICAS1_Gateway
 SG_ MO_SpannungsAnf_02  : 14|2@1+ (1.000000,0.000000) [0.000000|3.000000] "" ICAS1_Gateway
 SG_ MO_DPF_reg  : 16|1@1+ (1.000000,0.000000) [0.000000|1.000000] "" ICAS1_Gateway
 SG_ MO_Heizstrom_EKAT  : 17|7@1+ (1.000000,0.000000) [0.000000|126.000000] "Unit_Amper" ICAS1_Gateway
 SG_ MO_Heizstrom_SCR  : 24|6@1+ (1.000000,0.000000) [0.000000|62.000000] "Unit_Amper" ICAS1_Gateway
 SG_ MO_P_Generator_ungefiltert_Anf  : 31|1@1+ (1.000000,0.000000) [0.000000|1.000000] "" ICAS1_Gateway
 SG_ TSK_Getriebeinfo  : 34|2@1+ (1.000000,0.000000) [0.000000|3.000000] "" ICAS1_Gateway
 SG_ MO_Energieinhalt_BMS  : 36|12@1+ (25.000000,0.000000) [0.000000|102325.000000] "Unit_WattHour" ICAS1_Gateway
 SG_ TSK_Fahrzeugmasse_02  : 48|8@1+ (32.000000,0.000000) [0.000000|8128.000000] "Unit_KiloGram" ICAS1_Gateway
 SG_ TSK_Steigung_02  : 56|8@1+ (0.800000,-101.600000) [-100.800000|101.600000] "Unit_PerCent" ICAS1_Gateway

BO_ 1648 Motor_18: 8 Motor_BEV
 SG_ MO_max_Ladedruck  : 0|6@1+ (0.100000,0.000000) [0.000000|6.300000] "Unit_Bar" ICAS1_Gateway
 SG_ MO_ANC_Kennfeld_Anf  : 6|2@1+ (1.000000,0.000000) [0.000000|3.000000] "" ICAS1_Gateway
 SG_ MO_Bremslicht_Reku  : 8|1@1+ (1.000000,0.000000) [0.000000|1.000000] "" ICAS1_Gateway
 SG_ MO_StartStopp_PopUp  : 9|2@1+ (1.000000,0.000000) [0.000000|3.000000] "" ICAS1_Gateway
 SG_ MO1_Sperr_Info_WFS  : 11|1@1+ (1.000000,0.000000) [0.000000|1.000000] "" ICAS1_Gateway
 SG_ MO1_Freigabe_Info_WFS  : 12|1@1+ (1.000000,0.000000) [0.000000|1.000000] "" ICAS1_Gateway
 SG_ MO_EPCL  : 13|3@1+ (1.000000,0.000000) [0.000000|7.000000] "" ICAS1_Gateway ICAS1_KommunikationsServer
 SG_ MO_Zylabsch_Texte_02  : 16|4@1+ (1.000000,0.000000) [0.000000|15.000000] "" ICAS1_Gateway
 SG_ MO_Fahrzeugtyp  : 20|3@1+ (1.000000,0.000000) [0.000000|7.000000] "" ICAS1_Gateway ICAS1_KommunikationsServer
 SG_ MO_NMAX_Schaltanzeige  : 23|9@1+ (25.000000,0.000000) [0.000000|12775.000000] "Unit_MinutInver" ICAS1_Gateway
 SG_ MO_Abstellzeit  : 32|8@1+ (8.000000,0.000000) [0.000000|2024.000000] "Unit_Minut" ICAS1_Gateway
 SG_ MO_Abstellzeit_Status  : 40|2@1+ (1.000000,0.000000) [0.000000|3.000000] "" ICAS1_Gateway
 SG_ MO1_Freigabe_Verfallsinfo_WFS  : 42|1@1+ (1.000000,0.000000) [0.000000|1.000000] "" ICAS1_Gateway
 SG_ MO_Hybrid_StartStopp_LED  : 43|2@1+ (1.000000,0.000000) [0.000000|3.000000] "" ICAS1_Gateway
 SG_ MO_Fehler_Zylabsch  : 45|2@1+ (1.000000,0.000000) [0.000000|3.000000] "" ICAS1_Gateway
 SG_ MO_Anzahl_Abgesch_Zyl  : 47|3@1+ (1.000000,0.000000) [0.000000|7.000000] "" ICAS1_Gateway
 SG_ MO_Zylabsch_Texte  : 50|2@1+ (1.000000,0.000000) [0.000000|3.000000] "" ICAS1_Gateway
 SG_ MO_Ethanol_BS_Texte  : 52|3@1+ (1.000000,0.000000) [0.000000|7.000000] "" ICAS1_Gateway
 SG_ MO_Drehzahl_Warnung  : 55|1@1+ (1.000000,0.000000) [0.000000|1.000000] "" ICAS1_Gateway
 SG_ MO_obere_Drehzahlgrenze  : 56|8@1+ (50.000000,0.000000) [50.000000|12750.000000] "Unit_MinutInver" ICAS1_Gateway

BU_:  Airbag BAP_Tester ICAS1_Gateway ICAS1_KommunikationsServer LE1 LE2 Motor_BEV Schaltbetaetigung

BO_ 1505 Klima_Sensor_02: 8 ICAS1_Gateway
 SG_ BCM1_Aussen_Temp_ungef  : 0|8@1+ (0.500000,-50.000000) [-50.000000|76.000000] "Unit_DegreCelsi" LE1 LE2 Motor_BEV
 SG_ BCM_Heizungsabsperrventil_Status  : 8|2@1+ (1.000000,0.000000) [0.000000|3.000000] "" Vector__XXX
 SG_ BCM_Heizungspumpe_Status  : 10|2@1+ (1.000000,0.000000) [0.000000|3.000000] "" Vector__XXX
 SG_ BCM_Kompressorkupplung_Status  : 12|2@1+ (1.000000,0.000000) [0.000000|3.000000] "" Vector__XXX
 SG_ BCM1_PTC_stufig_Status  : 28|3@1+ (1.000000,0.000000) [0.000000|7.000000] "" Vector__XXX
 SG_ BCM1_FStatus_Aussentemp_ungef  : 31|1@1+ (1.000000,0.000000) [0.000000|1.000000] "" Vector__XXX
 SG_ BCM1_Kompressorstrom_ist  : 32|8@1+ (4.000000,0.000000) [0.000000|1000.000000] "Unit_MilliAmper" Vector__XXX
 SG_ BCM1_OBD_FStatus_ATemp  : 44|4@1+ (1.000000,0.000000) [0.000000|15.000000] "" Vector__XXX

BO_ 2549088277 KN_Airbag_01: 8 Airbag
 SG_ Airbag_01_KompSchutz  : 0|1@1+ (1.000000,0.000000) [0.000000|1.000000] "" Vector__XXX
 SG_ Airbag_01_Abschaltstufe  : 1|1@1+ (1.000000,0.000000) [0.000000|1.000000] "" Vector__XXX
 SG_ Airbag_01_Transport_Mode  : 2|1@1+ (1.000000,0.000000) [0.000000|1.000000] "" Vector__XXX
 SG_ Airbag_01_Nachlauftyp  : 4|4@1+ (1.000000,0.000000) [0.000000|15.000000] "" ICAS1_Gateway
 SG_ NM_Airbag_01_Wakeup  : 48|8@1+ (1.000000,0.000000) [0.000000|255.000000] "" Vector__XXX
 SG_ KN_AB_DiagPfad  : 60|1@1+ (1.000000,0.000000) [0.000000|1.000000] "" ICAS1_Gateway
 SG_ AB_KD_Fehler  : 63|1@1+ (1.000000,0.000000) [0.000000|1.000000] "" ICAS1_Gateway

BO_ 2549088380 KN_EMotor_01: 8 LE1
 SG_ EMotor_KompSchutz  : 0|1@1+ (1.000000,0.000000) [0.000000|1.000000] "" Vector__XXX
 SG_ EMotor_01_Abschaltstufe  : 1|1@1+ (1.000000,0.000000) [0.000000|1.000000] "" Vector__XXX
 SG_ EMotor_01_Transport_Mode  : 2|1@1+ (1.000000,0.000000) [0.000000|1.000000] "" Vector__XXX
 SG_ EMotor_Nachlauftyp  : 4|4@1+ (1.000000,0.000000) [0.000000|15.000000] "" ICAS1_Gateway
 SG_ NM_EMotor_01_Wakeup  : 48|8@1+ (1.000000,0.000000) [0.000000|255.000000] "" Vector__XXX
 SG_ KN_EM_HYB_DiagPfad  : 60|1@1+ (1.000000,0.000000) [0.000000|1.000000] "" ICAS1_Gateway
 SG_ EM_HYB_KD_Fehler  : 63|1@1+ (1.000000,0.000000) [0.000000|1.000000] "" ICAS1_Gateway

BO_ 2549088272 KN_Gateway: 8 ICAS1_Gateway
 SG_ Gateway_KompSchutz  : 0|1@1+ (1.000000,0.000000) [0.000000|1.000000] "" Vector__XXX
 SG_ Gateway_Abschaltstufe  : 1|1@1+ (1.000000,0.000000) [0.000000|1.000000] "" Vector__XXX
 SG_ Gateway_Transport_Mode  : 2|1@1+ (1.000000,0.000000) [0.000000|1.000000] "" Vector__XXX
 SG_ Gateway_Nachlauftyp  : 4|4@1+ (1.000000,0.000000) [0.000000|15.000000] "" Vector__XXX
 SG_ NM_Gateway_Wakeup  : 48|8@1+ (1.000000,0.000000) [0.000000|255.000000] "" Vector__XXX
 SG_ KN_GW_DiagPfad  : 60|1@1+ (1.000000,0.000000) [0.000000|1.000000] "" Vector__XXX
 SG_ GW_KD_Fehler  : 63|1@1+ (1.000000,0.000000) [0.000000|1.000000] "" Vector__XXX

BO_ 2549088440 KN_LE2: 8 LE2
 SG_ LE2_KompSchutz  : 0|1@1+ (1.000000,0.000000) [0.000000|1.000000] "" Vector__XXX
 SG_ LE2_Abschaltstufe  : 1|1@1+ (1.000000,0.000000) [0.000000|1.000000] "" Vector__XXX
 SG_ LE2_Transport_Mode  : 2|1@1+ (1.000000,0.000000) [0.000000|1.000000] "" Vector__XXX
 SG_ LE2_Nachlauftyp  : 4|4@1+ (1.000000,0.000000) [0.000000|15.000000] "" ICAS1_Gateway
 SG_ NM_LE2_Wakeup  : 48|8@1+ (1.000000,0.000000) [0.000000|255.000000] "" Vector__XXX
 SG_ KN_LE2_DiagPfad  : 60|1@1+ (1.000000,0.000000) [0.000000|1.000000] "" ICAS1_Gateway
 SG_ LE2_KD_Fehler  : 63|1@1+ (1.000000,0.000000) [0.000000|1.000000] "" ICAS1_Gateway

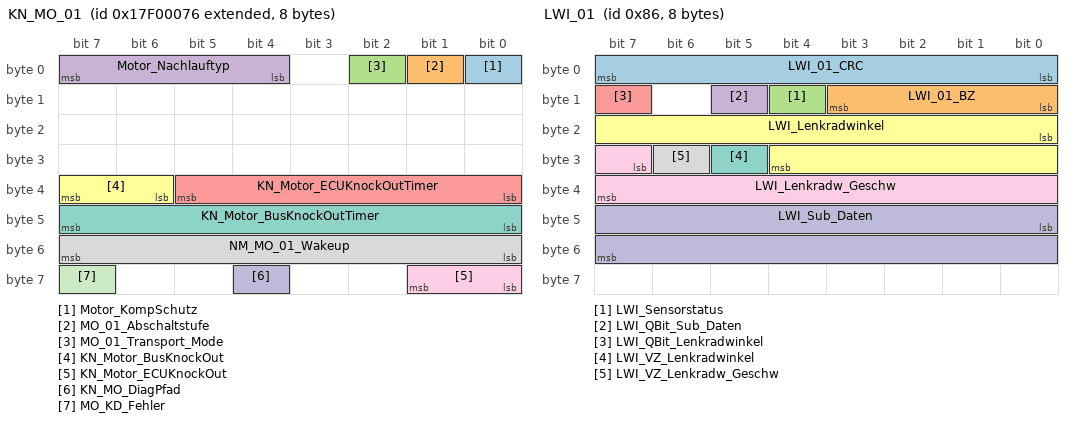
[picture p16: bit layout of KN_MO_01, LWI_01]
BO_ 2549088374 KN_MO_01: 8 Motor_BEV
 SG_ Motor_KompSchutz  : 0|1@1+ (1.000000,0.000000) [0.000000|1.000000] "" Vector__XXX
 SG_ MO_01_Abschaltstufe  : 1|1@1+ (1.000000,0.000000) [0.000000|1.000000] "" Vector__XXX
 SG_ MO_01_Transport_Mode  : 2|1@1+ (1.000000,0.000000) [0.000000|1.000000] "" Vector__XXX
 SG_ Motor_Nachlauftyp  : 4|4@1+ (1.000000,0.000000) [0.000000|15.000000] "" ICAS1_Gateway
 SG_ KN_Motor_ECUKnockOutTimer  : 32|6@1+ (1.000000,0.000000) [0.000000|62.000000] "Unit_Minut" Vector__XXX
 SG_ KN_Motor_BusKnockOut  : 38|2@1+ (1.000000,0.000000) [0.000000|3.000000] "" Vector__XXX
 SG_ KN_Motor_BusKnockOutTimer  : 40|8@1+ (1.000000,0.000000) [0.000000|254.000000] "" Vector__XXX
 SG_ NM_MO_01_Wakeup  : 48|8@1+ (1.000000,0.000000) [0.000000|255.000000] "" Vector__XXX
 SG_ KN_Motor_ECUKnockOut  : 56|2@1+ (1.000000,0.000000) [0.000000|3.000000] "" Vector__XXX
 SG_ KN_MO_DiagPfad  : 60|1@1+ (1.000000,0.000000) [0.000000|1.000000] "" ICAS1_Gateway
 SG_ MO_KD_Fehler  : 63|1@1+ (1.000000,0.000000) [0.000000|1.000000] "" ICAS1_Gateway

BO_ 2621440277 KS_Airbag_01_Req_FD: 16 ICAS1_Gateway
 SG_ KS_Airbag_01_Req_FD_Data  : 0|128@1+ (1.000000,0.000000) [0.000000|340282366920938463463374607431768211456.000000] "" Airbag

BO_ 2621571349 KS_Airbag_01_Resp_FD: 16 Airbag
 SG_ KS_Airbag_01_Resp_FD_Data  : 0|128@1+ (1.000000,0.000000) [0.000000|340282366920938463463374607431768211456.000000] "" ICAS1_Gateway

BO_ 982 Licht_hinten_01: 8 ICAS1_Gateway
 SG_ Licht_hinten_01_BZ  : 0|4@1+ (1.000000,0.000000) [0.000000|15.000000] "" Vector__XXX
 SG_ LH_Aussenlicht_def  : 7|1@1+ (1.000000,0.000000) [0.000000|1.000000] "" Vector__XXX
 SG_ LH_Standlicht_H_aktiv  : 8|1@1+ (1.000000,0.000000) [0.000000|1.000000] "" Vector__XXX
 SG_ LH_Parklicht_HL_aktiv  : 9|1@1+ (1.000000,0.000000) [0.000000|1.000000] "" Vector__XXX
 SG_ LH_Parklicht_HR_aktiv  : 10|1@1+ (1.000000,0.000000) [0.000000|1.000000] "" Vector__XXX
 SG_ LH_Bremslicht_H_aktiv  : 11|1@1+ (1.000000,0.000000) [0.000000|1.000000] "" Vector__XXX
 SG_ LH_Nebelschluss_aktiv  : 12|1@1+ (1.000000,0.000000) [0.000000|1.000000] "" Vector__XXX
 SG_ LH_Rueckfahrlicht_aktiv  : 13|1@1+ (1.000000,0.000000) [0.000000|1.000000] "" Vector__XXX
 SG_ LH_Blinker_HL_akt  : 14|1@1+ (1.000000,0.000000) [0.000000|1.000000] "" Vector__XXX
 SG_ LH_Blinker_HR_akt  : 15|1@1+ (1.000000,0.000000) [0.000000|1.000000] "" Vector__XXX
 SG_ LH_Blinker_li_def  : 16|1@1+ (1.000000,0.000000) [0.000000|1.000000] "" Vector__XXX
 SG_ LH_Bremsl_li_def  : 17|1@1+ (1.000000,0.000000) [0.000000|1.000000] "" Vector__XXX
 SG_ LH_Schlusslicht_li_def  : 18|1@1+ (1.000000,0.000000) [0.000000|1.000000] "" Vector__XXX
 SG_ LH_Rueckf_li_def  : 19|1@1+ (1.000000,0.000000) [0.000000|1.000000] "" Vector__XXX
 SG_ LH_Nebel_li_def  : 20|1@1+ (1.000000,0.000000) [0.000000|1.000000] "" Vector__XXX
 SG_ LH_Schluss_Brems_Nebel_li_def  : 21|1@1+ (1.000000,0.000000) [0.000000|1.000000] "" Vector__XXX
 SG_ LH_Schluss_Brems_Nebel_re_def  : 22|1@1+ (1.000000,0.000000) [0.000000|1.000000] "" Vector__XXX
 SG_ LH_Zusatzschlussl_def  : 23|1@1+ (1.000000,0.000000) [0.000000|1.000000] "" Vector__XXX
 SG_ LH_Schluss_Brems_li_def  : 24|1@1+ (1.000000,0.000000) [0.000000|1.000000] "" Vector__XXX
 SG_ LH_Schluss_Nebel_li_def  : 25|1@1+ (1.000000,0.000000) [0.000000|1.000000] "" Vector__XXX
 SG_ LH_SL_BRL_BLK_li_def  : 26|1@1+ (1.000000,0.000000) [0.000000|1.000000] "" Vector__XXX
 SG_ LH_Brems_Blk_li_def  : 27|1@1+ (1.000000,0.000000) [0.000000|1.000000] "" Vector__XXX
 SG_ LH_Diag_Status_re_def  : 28|1@1+ (1.000000,0.000000) [0.000000|1.000000] "" Vector__XXX
 SG_ LH_Diag_Status_li_def  : 29|1@1+ (1.000000,0.000000) [0.000000|1.000000] "" Vector__XXX
 SG_ LH_Diag_LED_li_def  : 30|1@1+ (1.000000,0.000000) [0.000000|1.000000] "" Vector__XXX
 SG_ LH_Diag_LED_re_def  : 31|1@1+ (1.000000,0.000000) [0.000000|1.000000] "" Vector__XXX
 SG_ LH_Blinker_re_def  : 32|1@1+ (1.000000,0.000000) [0.000000|1.000000] "" Vector__XXX
 SG_ LH_Bremsl_re_def  : 33|1@1+ (1.000000,0.000000) [0.000000|1.000000] "" Vector__XXX
 SG_ LH_Schlusslicht_re_def  : 34|1@1+ (1.000000,0.000000) [0.000000|1.000000] "" Vector__XXX
 SG_ LH_Rueckf_re_def  : 35|1@1+ (1.000000,0.000000) [0.000000|1.000000] "" Vector__XXX
 SG_ LH_Nebel_re_def  : 36|1@1+ (1.000000,0.000000) [0.000000|1.000000] "" Vector__XXX
 SG_ LH_Schluss_Brems_mi_def  : 37|1@1+ (1.000000,0.000000) [0.000000|1.000000] "" Vector__XXX
 SG_ LH_Schluss_Brems_re_def  : 40|1@1+ (1.000000,0.000000) [0.000000|1.000000] "" Vector__XXX
 SG_ LH_Schluss_Nebel_re_def  : 41|1@1+ (1.000000,0.000000) [0.000000|1.000000] "" Vector__XXX
 SG_ LH_SL_BRL_BLK_re_def  : 42|1@1+ (1.000000,0.000000) [0.000000|1.000000] "" Vector__XXX
 SG_ LH_Brems_Blk_re_def  : 43|1@1+ (1.000000,0.000000) [0.000000|1.000000] "" Vector__XXX
 SG_ LH_Kennzl_def  : 48|1@1+ (1.000000,0.000000) [0.000000|1.000000] "" Vector__XXX
 SG_ LH_3_Bremsl_def  : 49|1@1+ (1.000000,0.000000) [0.000000|1.000000] "" Motor_BEV
 SG_ LH_Nebel_mi_def  : 50|1@1+ (1.000000,0.000000) [0.000000|1.000000] "" Vector__XXX
 SG_ LH_Rueckf_mi_def  : 51|1@1+ (1.000000,0.000000) [0.000000|1.000000] "" Vector__XXX
 SG_ LH_Schlusslicht_mi_def  : 52|1@1+ (1.000000,0.000000) [0.000000|1.000000] "" Vector__XXX
 SG_ LH_Bremsl_li_ges_def  : 54|1@1+ (1.000000,0.000000) [0.000000|1.000000] "" Motor_BEV
 SG_ LH_Bremsl_re_ges_def  : 55|1@1+ (1.000000,0.000000) [0.000000|1.000000] "" Motor_BEV
 SG_ LH_Bremsl_mi_def  : 61|1@1+ (1.000000,0.000000) [0.000000|1.000000] "" Vector__XXX
 SG_ BRL_als_SHL  : 62|1@1+ (1.000000,0.000000) [0.000000|1.000000] "" Vector__XXX

BO_ 134 LWI_01: 8 ICAS1_Gateway
 SG_ LWI_01_CRC  : 0|8@1+ (1.000000,0.000000) [0.000000|255.000000] "" Airbag Motor_BEV
 SG_ LWI_01_BZ  : 8|4@1+ (1.000000,0.000000) [0.000000|15.000000] "" Airbag Motor_BEV
 SG_ LWI_Sensorstatus  : 12|1@1+ (1.000000,0.000000) [0.000000|1.000000] "" Airbag Motor_BEV
 SG_ LWI_QBit_Sub_Daten  : 13|1@1+ (1.000000,0.000000) [0.000000|1.000000] "" Vector__XXX
 SG_ LWI_QBit_Lenkradwinkel  : 15|1@1+ (1.000000,0.000000) [0.000000|1.000000] "" Airbag Motor_BEV
 SG_ LWI_Lenkradwinkel  : 16|13@1+ (0.100000,0.000000) [0.000000|800.000000] "Unit_DegreOfArc" Airbag Motor_BEV
 SG_ LWI_VZ_Lenkradwinkel  : 29|1@1+ (1.000000,0.000000) [0.000000|1.000000] "" Airbag Motor_BEV
 SG_ LWI_VZ_Lenkradw_Geschw  : 30|1@1+ (1.000000,0.000000) [0.000000|1.000000] "" Vector__XXX
 SG_ LWI_Lenkradw_Geschw  : 31|9@1+ (5.000000,0.000000) [0.000000|2500.000000] "Unit_DegreOfArcPerSecon" Airbag
 SG_ LWI_Sub_Daten  : 40|16@1+ (1.000000,0.000000) [0.000000|65535.000000] "" Vector__XXX

BO_ 817 MFL_01: 8 ICAS1_Gateway
 SG_ MFL_Zaehler  : 0|4@1+ (1.000000,0.000000) [0.000000|15.000000] "" Vector__XXX
 SG_ MFL_Toggle  : 4|1@1+ (1.000000,0.000000) [0.000000|1.000000] "" Vector__XXX
 SG_ MFL_Lokalaktiv  : 5|1@1+ (1.000000,0.000000) [0.000000|1.000000] "" Vector__XXX
 SG_ MFL_M_Taste  : 6|1@1+ (1.000000,0.000000) [0.000000|1.000000] "" Vector__XXX
 SG_ MFL_Paddle_Verbau  : 7|1@1+ (1.000000,0.000000) [0.000000|1.000000] "" Vector__XXX
 SG_ MFL_Tastencode_1  : 8|8@1+ (1.000000,0.000000) [0.000000|255.000000] "" Vector__XXX
 SG_ MFL_Tastencode_2  : 16|8@1+ (1.000000,0.000000) [0.000000|255.000000] "" Vector__XXX
 SG_ MFL_Eventcode_1  : 24|4@1+ (1.000000,0.000000) [0.000000|15.000000] "" Vector__XXX
 SG_ MFL_Eventcode_2  : 28|4@1+ (1.000000,0.000000) [0.000000|15.000000] "" Vector__XXX
 SG_ MFL_Marke  : 32|4@1+ (1.000000,0.000000) [0.000000|15.000000] "" Vector__XXX
 SG_ MFL_Variante  : 36|4@1+ (1.000000,0.000000) [0.000000|15.000000] "" Vector__XXX
 SG_ MFL_Dummy_0_Signal_1  : 40|8@1+ (1.000000,0.000000) [0.000000|255.000000] "" Vector__XXX
 SG_ MFL_Tip_Down  : 48|1@1+ (1.000000,0.000000) [0.000000|1.000000] "" Motor_BEV
 SG_ MFL_Tip_Up  : 49|1@1+ (1.000000,0.000000) [0.000000|1.000000] "" Motor_BEV
 SG_ MFL_SatModul_links_Err  : 50|1@1+ (1.000000,0.000000) [0.000000|1.000000] "" Vector__XXX
 SG_ MFL_SatModul_rechts_Err  : 51|1@1+ (1.000000,0.000000) [0.000000|1.000000] "" Vector__XXX
 SG_ MFL_Dummy_0_Signal_2  : 52|1@1+ (1.000000,0.000000) [0.000000|1.000000] "" Vector__XXX
 SG_ MFL_Dummy_0_Signal_3  : 53|1@1+ (1.000000,0.000000) [0.000000|1.000000] "" Vector__XXX
 SG_ MFL_LR_HZG_Status  : 54|1@1+ (1.000000,0.000000) [0.000000|1.000000] "" Vector__XXX
 SG_ MFL_LR_HZG_Err  : 55|1@1+ (1.000000,0.000000) [0.000000|1.000000] "" Vector__XXX
 SG_ MFL_Signalhorn  : 56|1@1+ (1.000000,0.000000) [0.000000|1.000000] "" Vector__XXX
 SG_ MFL_Signalhorn_Err  : 57|1@1+ (1.000000,0.000000) [0.000000|1.000000] "" Vector__XXX
 SG_ MFL_Tip_links_Err  : 58|1@1+ (1.000000,0.000000) [0.000000|1.000000] "" Vector__XXX
 SG_ MFL_Tip_rechts_Err  : 59|1@1+ (1.000000,0.000000) [0.000000|1.000000] "" Vector__XXX
 SG_ MFL_Taste_links_Err  : 60|1@1+ (1.000000,0.000000) [0.000000|1.000000] "" Vector__XXX
 SG_ MFL_Taste_rechts_Err  : 61|1@1+ (1.000000,0.000000) [0.000000|1.000000] "" Vector__XXX
 SG_ MFL_ECU_Err  : 62|1@1+ (1.000000,0.000000) [0.000000|1.000000] "" Vector__XXX
 SG_ MFL_Response_Err  : 63|1@1+ (1.000000,0.000000) [0.000000|1.000000] "" Vector__XXX

BO_ 15 MO_SOPC: 1 Motor_BEV
 SG_ MO_SOPC  : 0|1@1+ (1.000000,0.000000) [0.000000|1.000000] "" Vector__XXX

BO_ 1600 Motor_07: 8 Motor_BEV
 SG_ MO_QBit_Ansaugluft_Temp  : 0|1@1+ (1.000000,0.000000) [0.000000|1.000000] "" Vector__XXX
 SG_ MO_QBit_Oel_Temp  : 1|1@1+ (1.000000,0.000000) [0.000000|1.000000] "" Vector__XXX
 SG_ MO_QBit_Kuehlmittel_Temp  : 2|1@1+ (1.000000,0.000000) [0.000000|1.000000] "" Vector__XXX
 SG_ MO_KL15_Abschaltempfehlung  : 3|1@1+ (1.000000,0.000000) [0.000000|1.000000] "" Vector__XXX
 SG_ MO_HYB_Fehler_HV_Netz  : 4|1@1+ (1.000000,0.000000) [0.000000|1.000000] "" Vector__XXX
 SG_ MO_aktives_Getriebeheizen  : 5|1@1+ (1.000000,0.000000) [0.000000|1.000000] "" Vector__XXX
 SG_ MO_Absperrventil_oeffnen  : 6|2@1+ (1.000000,0.000000) [0.000000|3.000000] "" Vector__XXX
 SG_ MO_Ansaugluft_Temp  : 8|8@1+ (0.750000,-48.000000) [-48.000000|141.750000] "Unit_DegreCelsi" Vector__XXX
 SG_ MO_Oel_Temp  : 16|8@1+ (1.000000,-60.000000) [-60.000000|192.000000] "Unit_DegreCelsi" Vector__XXX
 SG_ MO_Kuehlmittel_Temp  : 24|8@1+ (0.750000,-48.000000) [-48.000000|141.750000] "Unit_DegreCelsi" Vector__XXX
 SG_ MO_Hoeheninfo  : 32|8@1+ (0.007810,0.000000) [0.000000|1.983740] "" Vector__XXX
 SG_ MO_Kennfeldk  : 40|1@1+ (1.000000,0.000000) [0.000000|1.000000] "" Vector__XXX
 SG_ MO_Versionsinfo_02  : 41|5@1+ (1.000000,0.000000) [0.000000|31.000000] "" Vector__XXX
 SG_ MO_QBit_Hoeheninfo  : 46|1@1+ (1.000000,0.000000) [0.000000|1.000000] "" Vector__XXX
 SG_ MO_Getriebe_kuehlen  : 47|1@1+ (1.000000,0.000000) [0.000000|1.000000] "" Vector__XXX
 SG_ MO_Mom_Traegheit_02  : 48|5@1+ (0.010000,0.000000) [0.000000|0.310000] "Unit_KiloGramMeterSquar" Vector__XXX
 SG_ MO_Heizungspumpenansteuerung  : 53|4@1+ (10.000000,0.000000) [0.000000|100.000000] "Unit_PerCent" Vector__XXX
 SG_ MO_SpannungsAnf  : 57|1@1+ (1.000000,0.000000) [0.000000|1.000000] "" Vector__XXX
 SG_ MO_Nachlaufzeit_Heizungspumpe  : 58|6@1+ (15.000000,0.000000) [0.000000|945.000000] "Unit_Secon" Vector__XXX

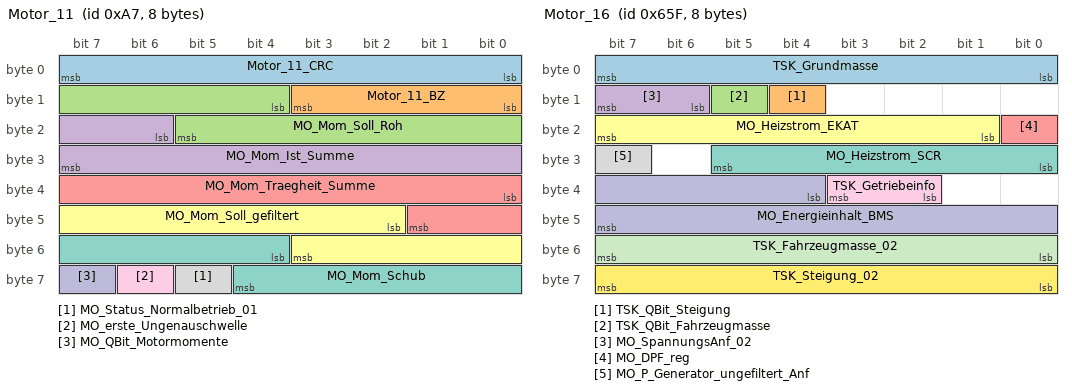
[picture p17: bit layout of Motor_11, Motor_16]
BO_ 167 Motor_11: 8 Motor_BEV
 SG_ Motor_11_CRC  : 0|8@1+ (1.000000,0.000000) [0.000000|255.000000] "" ICAS1_Gateway
 SG_ Motor_11_BZ  : 8|4@1+ (1.000000,0.000000) [0.000000|15.000000] "" ICAS1_Gateway
 SG_ MO_Mom_Soll_Roh  : 12|10@1+ (1.000000,-509.000000) [-509.000000|509.000000] "" ICAS1_Gateway
 SG_ MO_Mom_Ist_Summe  : 22|10@1+ (1.000000,-509.000000) [-509.000000|509.000000] "" ICAS1_Gateway
 SG_ MO_Mom_Traegheit_Summe  : 32|10@1+ (1.000000,-509.000000) [-509.000000|509.000000] "" ICAS1_Gateway
 SG_ MO_Mom_Soll_gefiltert  : 42|10@1+ (1.000000,-509.000000) [-509.000000|509.000000] "" ICAS1_Gateway
 SG_ MO_Mom_Schub  : 52|9@1+ (1.000000,-509.000000) [-509.000000|0.000000] "" ICAS1_Gateway
 SG_ MO_Status_Normalbetrieb_01  : 61|1@1+ (1.000000,0.000000) [0.000000|1.000000] "" ICAS1_Gateway
 SG_ MO_erste_Ungenauschwelle  : 62|1@1+ (1.000000,0.000000) [0.000000|1.000000] "" ICAS1_Gateway
 SG_ MO_QBit_Motormomente  : 63|1@1+ (1.000000,0.000000) [0.000000|1.000000] "" ICAS1_Gateway

BO_ 168 Motor_12: 8 Motor_BEV
 SG_ Motor_12_CRC  : 0|8@1+ (1.000000,0.000000) [0.000000|255.000000] "" ICAS1_Gateway
 SG_ Motor_12_BZ  : 8|4@1+ (1.000000,0.000000) [0.000000|15.000000] "" ICAS1_Gateway
 SG_ MO_Mom_neg_verfuegbar  : 12|9@1+ (1.000000,-509.000000) [-509.000000|0.000000] "" ICAS1_Gateway
 SG_ MO_Mom_Begr_Fahr  : 21|9@1+ (1.000000,0.000000) [0.000000|509.000000] "" ICAS1_Gateway
 SG_ MO_Mom_Begr_Schalt  : 30|10@1+ (1.000000,-509.000000) [-509.000000|509.000000] "" ICAS1_Gateway
 SG_ MO_Momentenintegral_02  : 40|7@1+ (1.000000,0.000000) [0.000000|100.000000] "Unit_PerCent" ICAS1_Gateway
 SG_ MO_QBit_Drehzahl_01  : 47|1@1+ (1.000000,0.000000) [0.000000|1.000000] "" Airbag ICAS1_Gateway LE2
 SG_ MO_Drehzahl_01  : 48|16@1+ (0.250000,0.000000) [0.000000|16383.000000] "Unit_MinutInver" ICAS1_Gateway

BO_ 958 Motor_14: 8 Motor_BEV
 SG_ Motor_14_CRC  : 0|8@1+ (1.000000,0.000000) [0.000000|255.000000] "" ICAS1_Gateway
 SG_ Motor_14_BZ  : 8|4@1+ (1.000000,0.000000) [0.000000|15.000000] "" ICAS1_Gateway
 SG_ MO_StartStopp_Status  : 12|2@1+ (1.000000,0.000000) [0.000000|3.000000] "" ICAS1_Gateway
 SG_ MO_StartStopp_Wiederstart  : 14|1@1+ (1.000000,0.000000) [0.000000|1.000000] "" ICAS1_Gateway
 SG_ MO_StartStopp_Motorstopp  : 15|1@1+ (1.000000,0.000000) [0.000000|1.000000] "" ICAS1_Gateway
 SG_ MO_Freig_Reku  : 16|2@1+ (1.000000,0.000000) [0.000000|3.000000] "" ICAS1_Gateway
 SG_ MO_Kl_75  : 18|1@1+ (1.000000,0.000000) [0.000000|1.000000] "" ICAS1_Gateway
 SG_ MO_Kl_50  : 19|1@1+ (1.000000,0.000000) [0.000000|1.000000] "" ICAS1_Gateway
 SG_ MO_Gangposition  : 20|4@1+ (1.000000,0.000000) [0.000000|15.000000] "" ICAS1_Gateway
 SG_ MO_StartStopp_Fahrerwunsch  : 24|2@1+ (1.000000,0.000000) [0.000000|3.000000] "" ICAS1_Gateway
 SG_ MO_HYB_Fahrbereitschaft  : 26|1@1+ (1.000000,0.000000) [0.000000|1.000000] "" ICAS1_Gateway
 SG_ MO_Ext_E_Fahrt_aktiv  : 27|1@1+ (1.000000,0.000000) [0.000000|1.000000] "" ICAS1_Gateway
 SG_ MO_Fahrer_bremst  : 28|1@1+ (1.000000,0.000000) [0.000000|1.000000] "" Airbag ICAS1_Gateway
 SG_ MO_QBit_Fahrer_bremst  : 29|1@1+ (1.000000,0.000000) [0.000000|1.000000] "" Airbag ICAS1_Gateway
 SG_ MO_BLS  : 30|1@1+ (1.000000,0.000000) [0.000000|1.000000] "" Airbag ICAS1_Gateway
 SG_ MO_Konsistenz_Bremsped  : 31|1@1+ (1.000000,0.000000) [0.000000|1.000000] "" ICAS1_Gateway
 SG_ MO_Timeout_ESP  : 32|1@1+ (1.000000,0.000000) [0.000000|1.000000] "" ICAS1_Gateway
 SG_ MO_Klima_Eingr  : 33|2@1+ (1.000000,0.000000) [0.000000|3.000000] "" ICAS1_Gateway
 SG_ MO_Aussp_Anlass  : 35|1@1+ (1.000000,0.000000) [0.000000|1.000000] "" ICAS1_Gateway
 SG_ MO_Freig_Anlass  : 36|1@1+ (1.000000,0.000000) [0.000000|1.000000] "" ICAS1_Gateway
 SG_ MO_Kuppl_schalter  : 37|1@1+ (1.000000,0.000000) [0.000000|1.000000] "" ICAS1_Gateway
 SG_ MO_Interlock  : 38|1@1+ (1.000000,0.000000) [0.000000|1.000000] "" ICAS1_Gateway
 SG_ MO_Motor_laeuft  : 39|1@1+ (1.000000,0.000000) [0.000000|1.000000] "" ICAS1_Gateway
 SG_ MO_Kickdown  : 40|1@1+ (1.000000,0.000000) [0.000000|1.000000] "" ICAS1_Gateway ICAS1_KommunikationsServer
 SG_ MO_QBit_KL_75  : 41|1@1+ (1.000000,0.000000) [0.000000|1.000000] "" ICAS1_Gateway
 SG_ MO_EKlKomLeiRed  : 42|2@1+ (1.000000,0.000000) [0.000000|3.000000] "" ICAS1_Gateway
 SG_ MO_Handshake_STH  : 44|1@1+ (1.000000,0.000000) [0.000000|1.000000] "" ICAS1_Gateway
 SG_ MO_BKV_Unterdruckwarnung  : 45|1@1+ (1.000000,0.000000) [0.000000|1.000000] "" ICAS1_Gateway
 SG_ MO_Freigabe_Segeln  : 46|1@1+ (1.000000,0.000000) [0.000000|1.000000] "" ICAS1_Gateway
 SG_ MO_PTC_Status  : 47|3@1+ (1.000000,0.000000) [0.000000|7.000000] "" ICAS1_Gateway
 SG_ MO_QBit_Gangposition  : 50|1@1+ (1.000000,0.000000) [0.000000|1.000000] "" ICAS1_Gateway
 SG_ MO_Signalquelle_Gangposition  : 51|1@1+ (1.000000,0.000000) [0.000000|1.000000] "" ICAS1_Gateway
 SG_ MO_Remotestart_Betrieb  : 52|1@1+ (1.000000,0.000000) [0.000000|1.000000] "" ICAS1_Gateway
 SG_ MO_Remotestart_moeglich  : 53|1@1+ (1.000000,0.000000) [0.000000|1.000000] "" ICAS1_Gateway
 SG_ MO_FMAus_aktiv  : 55|1@1+ (1.000000,0.000000) [0.000000|1.000000] "" ICAS1_Gateway
 SG_ MO_FMAus_Startvariante  : 56|2@1+ (1.000000,0.000000) [0.000000|3.000000] "" ICAS1_Gateway
 SG_ MO_BMS_NV_Anf_stuetzen  : 58|1@1+ (1.000000,0.000000) [0.000000|1.000000] "" ICAS1_Gateway
 SG_ MO_Zylinderabschaltung  : 59|2@1+ (1.000000,0.000000) [0.000000|3.000000] "" ICAS1_Gateway
 SG_ MO_HYB_VM_aktiv  : 61|1@1+ (1.000000,0.000000) [0.000000|1.000000] "" ICAS1_Gateway
 SG_ MO_StartVorauss_erfuellt  : 62|2@1+ (1.000000,0.000000) [0.000000|3.000000] "" ICAS1_Gateway

BO_ 1631 Motor_16: 8 Motor_BEV
 SG_ TSK_Grundmasse  : 0|8@1+ (32.000000,0.000000) [0.000000|8128.000000] "Unit_KiloGram" ICAS1_Gateway
 SG_ TSK_QBit_Steigung  : 12|1@1+ (1.000000,0.000000) [0.000000|1.000000] "" ICAS1_Gateway
 SG_ TSK_QBit_Fahrzeugmasse  : 13|1@1+ (1.000000,0.000000) [0.000000|1.000000] "" ICAS1_Gateway
 SG_ MO_SpannungsAnf_02  : 14|2@1+ (1.000000,0.000000) [0.000000|3.000000] "" ICAS1_Gateway
 SG_ MO_DPF_reg  : 16|1@1+ (1.000000,0.000000) [0.000000|1.000000] "" ICAS1_Gateway
 SG_ MO_Heizstrom_EKAT  : 17|7@1+ (1.000000,0.000000) [0.000000|126.000000] "Unit_Amper" ICAS1_Gateway
 SG_ MO_Heizstrom_SCR  : 24|6@1+ (1.000000,0.000000) [0.000000|62.000000] "Unit_Amper" ICAS1_Gateway
 SG_ MO_P_Generator_ungefiltert_Anf  : 31|1@1+ (1.000000,0.000000) [0.000000|1.000000] "" ICAS1_Gateway
 SG_ TSK_Getriebeinfo  : 34|2@1+ (1.000000,0.000000) [0.000000|3.000000] "" ICAS1_Gateway
 SG_ MO_Energieinhalt_BMS  : 36|12@1+ (25.000000,0.000000) [0.000000|102325.000000] "Unit_WattHour" ICAS1_Gateway
 SG_ TSK_Fahrzeugmasse_02  : 48|8@1+ (32.000000,0.000000) [0.000000|8128.000000] "Unit_KiloGram" ICAS1_Gateway
 SG_ TSK_Steigung_02  : 56|8@1+ (0.800000,-101.600000) [-100.800000|101.600000] "Unit_PerCent" ICAS1_Gateway

BO_ 1648 Motor_18: 8 Motor_BEV
 SG_ MO_max_Ladedruck  : 0|6@1+ (0.100000,0.000000) [0.000000|6.300000] "Unit_Bar" ICAS1_Gateway
 SG_ MO_ANC_Kennfeld_Anf  : 6|2@1+ (1.000000,0.000000) [0.000000|3.000000] "" ICAS1_Gateway
 SG_ MO_Bremslicht_Reku  : 8|1@1+ (1.000000,0.000000) [0.000000|1.000000] "" ICAS1_Gateway
 SG_ MO_StartStopp_PopUp  : 9|2@1+ (1.000000,0.000000) [0.000000|3.000000] "" ICAS1_Gateway
 SG_ MO1_Sperr_Info_WFS  : 11|1@1+ (1.000000,0.000000) [0.000000|1.000000] "" ICAS1_Gateway
 SG_ MO1_Freigabe_Info_WFS  : 12|1@1+ (1.000000,0.000000) [0.000000|1.000000] "" ICAS1_Gateway
 SG_ MO_EPCL  : 13|3@1+ (1.000000,0.000000) [0.000000|7.000000] "" ICAS1_Gateway ICAS1_KommunikationsServer
 SG_ MO_Zylabsch_Texte_02  : 16|4@1+ (1.000000,0.000000) [0.000000|15.000000] "" ICAS1_Gateway
 SG_ MO_Fahrzeugtyp  : 20|3@1+ (1.000000,0.000000) [0.000000|7.000000] "" ICAS1_Gateway ICAS1_KommunikationsServer
 SG_ MO_NMAX_Schaltanzeige  : 23|9@1+ (25.000000,0.000000) [0.000000|12775.000000] "Unit_MinutInver" ICAS1_Gateway
 SG_ MO_Abstellzeit  : 32|8@1+ (8.000000,0.000000) [0.000000|2024.000000] "Unit_Minut" ICAS1_Gateway
 SG_ MO_Abstellzeit_Status  : 40|2@1+ (1.000000,0.000000) [0.000000|3.000000] "" ICAS1_Gateway
 SG_ MO1_Freigabe_Verfallsinfo_WFS  : 42|1@1+ (1.000000,0.000000) [0.000000|1.000000] "" ICAS1_Gateway
 SG_ MO_Hybrid_StartStopp_LED  : 43|2@1+ (1.000000,0.000000) [0.000000|3.000000] "" ICAS1_Gateway
 SG_ MO_Fehler_Zylabsch  : 45|2@1+ (1.000000,0.000000) [0.000000|3.000000] "" ICAS1_Gateway
 SG_ MO_Anzahl_Abgesch_Zyl  : 47|3@1+ (1.000000,0.000000) [0.000000|7.000000] "" ICAS1_Gateway
 SG_ MO_Zylabsch_Texte  : 50|2@1+ (1.000000,0.000000) [0.000000|3.000000] "" ICAS1_Gateway
 SG_ MO_Ethanol_BS_Texte  : 52|3@1+ (1.000000,0.000000) [0.000000|7.000000] "" ICAS1_Gateway
 SG_ MO_Drehzahl_Warnung  : 55|1@1+ (1.000000,0.000000) [0.000000|1.000000] "" ICAS1_Gateway
 SG_ MO_obere_Drehzahlgrenze  : 56|8@1+ (50.000000,0.000000) [50.000000|12750.000000] "Unit_MinutInver" ICAS1_Gateway

BU_:  Airbag BAP_Tester ICAS1_Gateway ICAS1_KommunikationsServer LE1 LE2 Motor_BEV Schaltbetaetigung

BO_ 1505 Klima_Sensor_02: 8 ICAS1_Gateway
 SG_ BCM1_Aussen_Temp_ungef  : 0|8@1+ (0.500000,-50.000000) [-50.000000|76.000000] "Unit_DegreCelsi" LE1 LE2 Motor_BEV
 SG_ BCM_Heizungsabsperrventil_Status  : 8|2@1+ (1.000000,0.000000) [0.000000|3.000000] "" Vector__XXX
 SG_ BCM_Heizungspumpe_Status  : 10|2@1+ (1.000000,0.000000) [0.000000|3.000000] "" Vector__XXX
 SG_ BCM_Kompressorkupplung_Status  : 12|2@1+ (1.000000,0.000000) [0.000000|3.000000] "" Vector__XXX
 SG_ BCM1_PTC_stufig_Status  : 28|3@1+ (1.000000,0.000000) [0.000000|7.000000] "" Vector__XXX
 SG_ BCM1_FStatus_Aussentemp_ungef  : 31|1@1+ (1.000000,0.000000) [0.000000|1.000000] "" Vector__XXX
 SG_ BCM1_Kompressorstrom_ist  : 32|8@1+ (4.000000,0.000000) [0.000000|1000.000000] "Unit_MilliAmper" Vector__XXX
 SG_ BCM1_OBD_FStatus_ATemp  : 44|4@1+ (1.000000,0.000000) [0.000000|15.000000] "" Vector__XXX

BO_ 2549088277 KN_Airbag_01: 8 Airbag
 SG_ Airbag_01_KompSchutz  : 0|1@1+ (1.000000,0.000000) [0.000000|1.000000] "" Vector__XXX
 SG_ Airbag_01_Abschaltstufe  : 1|1@1+ (1.000000,0.000000) [0.000000|1.000000] "" Vector__XXX
 SG_ Airbag_01_Transport_Mode  : 2|1@1+ (1.000000,0.000000) [0.000000|1.000000] "" Vector__XXX
 SG_ Airbag_01_Nachlauftyp  : 4|4@1+ (1.000000,0.000000) [0.000000|15.000000] "" ICAS1_Gateway
 SG_ NM_Airbag_01_Wakeup  : 48|8@1+ (1.000000,0.000000) [0.000000|255.000000] "" Vector__XXX
 SG_ KN_AB_DiagPfad  : 60|1@1+ (1.000000,0.000000) [0.000000|1.000000] "" ICAS1_Gateway
 SG_ AB_KD_Fehler  : 63|1@1+ (1.000000,0.000000) [0.000000|1.000000] "" ICAS1_Gateway

BO_ 2549088380 KN_EMotor_01: 8 LE1
 SG_ EMotor_KompSchutz  : 0|1@1+ (1.000000,0.000000) [0.000000|1.000000] "" Vector__XXX
 SG_ EMotor_01_Abschaltstufe  : 1|1@1+ (1.000000,0.000000) [0.000000|1.000000] "" Vector__XXX
 SG_ EMotor_01_Transport_Mode  : 2|1@1+ (1.000000,0.000000) [0.000000|1.000000] "" Vector__XXX
 SG_ EMotor_Nachlauftyp  : 4|4@1+ (1.000000,0.000000) [0.000000|15.000000] "" ICAS1_Gateway
 SG_ NM_EMotor_01_Wakeup  : 48|8@1+ (1.000000,0.000000) [0.000000|255.000000] "" Vector__XXX
 SG_ KN_EM_HYB_DiagPfad  : 60|1@1+ (1.000000,0.000000) [0.000000|1.000000] "" ICAS1_Gateway
 SG_ EM_HYB_KD_Fehler  : 63|1@1+ (1.000000,0.000000) [0.000000|1.000000] "" ICAS1_Gateway

BO_ 2549088272 KN_Gateway: 8 ICAS1_Gateway
 SG_ Gateway_KompSchutz  : 0|1@1+ (1.000000,0.000000) [0.000000|1.000000] "" Vector__XXX
 SG_ Gateway_Abschaltstufe  : 1|1@1+ (1.000000,0.000000) [0.000000|1.000000] "" Vector__XXX
 SG_ Gateway_Transport_Mode  : 2|1@1+ (1.000000,0.000000) [0.000000|1.000000] "" Vector__XXX
 SG_ Gateway_Nachlauftyp  : 4|4@1+ (1.000000,0.000000) [0.000000|15.000000] "" Vector__XXX
 SG_ NM_Gateway_Wakeup  : 48|8@1+ (1.000000,0.000000) [0.000000|255.000000] "" Vector__XXX
 SG_ KN_GW_DiagPfad  : 60|1@1+ (1.000000,0.000000) [0.000000|1.000000] "" Vector__XXX
 SG_ GW_KD_Fehler  : 63|1@1+ (1.000000,0.000000) [0.000000|1.000000] "" Vector__XXX

BO_ 2549088440 KN_LE2: 8 LE2
 SG_ LE2_KompSchutz  : 0|1@1+ (1.000000,0.000000) [0.000000|1.000000] "" Vector__XXX
 SG_ LE2_Abschaltstufe  : 1|1@1+ (1.000000,0.000000) [0.000000|1.000000] "" Vector__XXX
 SG_ LE2_Transport_Mode  : 2|1@1+ (1.000000,0.000000) [0.000000|1.000000] "" Vector__XXX
 SG_ LE2_Nachlauftyp  : 4|4@1+ (1.000000,0.000000) [0.000000|15.000000] "" ICAS1_Gateway
 SG_ NM_LE2_Wakeup  : 48|8@1+ (1.000000,0.000000) [0.000000|255.000000] "" Vector__XXX
 SG_ KN_LE2_DiagPfad  : 60|1@1+ (1.000000,0.000000) [0.000000|1.000000] "" ICAS1_Gateway
 SG_ LE2_KD_Fehler  : 63|1@1+ (1.000000,0.000000) [0.000000|1.000000] "" ICAS1_Gateway

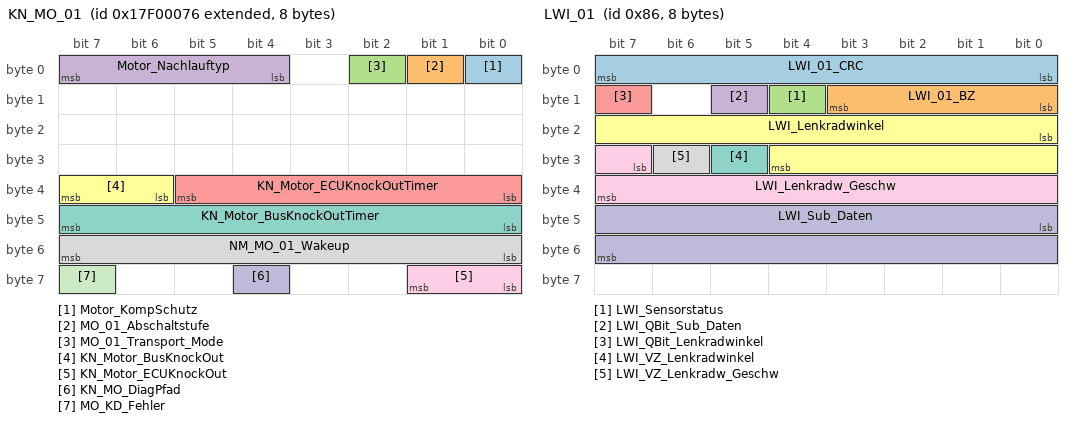
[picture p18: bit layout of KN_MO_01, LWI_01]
BO_ 2549088374 KN_MO_01: 8 Motor_BEV
 SG_ Motor_KompSchutz  : 0|1@1+ (1.000000,0.000000) [0.000000|1.000000] "" Vector__XXX
 SG_ MO_01_Abschaltstufe  : 1|1@1+ (1.000000,0.000000) [0.000000|1.000000] "" Vector__XXX
 SG_ MO_01_Transport_Mode  : 2|1@1+ (1.000000,0.000000) [0.000000|1.000000] "" Vector__XXX
 SG_ Motor_Nachlauftyp  : 4|4@1+ (1.000000,0.000000) [0.000000|15.000000] "" ICAS1_Gateway
 SG_ KN_Motor_ECUKnockOutTimer  : 32|6@1+ (1.000000,0.000000) [0.000000|62.000000] "Unit_Minut" Vector__XXX
 SG_ KN_Motor_BusKnockOut  : 38|2@1+ (1.000000,0.000000) [0.000000|3.000000] "" Vector__XXX
 SG_ KN_Motor_BusKnockOutTimer  : 40|8@1+ (1.000000,0.000000) [0.000000|254.000000] "" Vector__XXX
 SG_ NM_MO_01_Wakeup  : 48|8@1+ (1.000000,0.000000) [0.000000|255.000000] "" Vector__XXX
 SG_ KN_Motor_ECUKnockOut  : 56|2@1+ (1.000000,0.000000) [0.000000|3.000000] "" Vector__XXX
 SG_ KN_MO_DiagPfad  : 60|1@1+ (1.000000,0.000000) [0.000000|1.000000] "" ICAS1_Gateway
 SG_ MO_KD_Fehler  : 63|1@1+ (1.000000,0.000000) [0.000000|1.000000] "" ICAS1_Gateway

BO_ 2621440277 KS_Airbag_01_Req_FD: 16 ICAS1_Gateway
 SG_ KS_Airbag_01_Req_FD_Data  : 0|128@1+ (1.000000,0.000000) [0.000000|340282366920938463463374607431768211456.000000] "" Airbag

BO_ 2621571349 KS_Airbag_01_Resp_FD: 16 Airbag
 SG_ KS_Airbag_01_Resp_FD_Data  : 0|128@1+ (1.000000,0.000000) [0.000000|340282366920938463463374607431768211456.000000] "" ICAS1_Gateway

BO_ 982 Licht_hinten_01: 8 ICAS1_Gateway
 SG_ Licht_hinten_01_BZ  : 0|4@1+ (1.000000,0.000000) [0.000000|15.000000] "" Vector__XXX
 SG_ LH_Aussenlicht_def  : 7|1@1+ (1.000000,0.000000) [0.000000|1.000000] "" Vector__XXX
 SG_ LH_Standlicht_H_aktiv  : 8|1@1+ (1.000000,0.000000) [0.000000|1.000000] "" Vector__XXX
 SG_ LH_Parklicht_HL_aktiv  : 9|1@1+ (1.000000,0.000000) [0.000000|1.000000] "" Vector__XXX
 SG_ LH_Parklicht_HR_aktiv  : 10|1@1+ (1.000000,0.000000) [0.000000|1.000000] "" Vector__XXX
 SG_ LH_Bremslicht_H_aktiv  : 11|1@1+ (1.000000,0.000000) [0.000000|1.000000] "" Vector__XXX
 SG_ LH_Nebelschluss_aktiv  : 12|1@1+ (1.000000,0.000000) [0.000000|1.000000] "" Vector__XXX
 SG_ LH_Rueckfahrlicht_aktiv  : 13|1@1+ (1.000000,0.000000) [0.000000|1.000000] "" Vector__XXX
 SG_ LH_Blinker_HL_akt  : 14|1@1+ (1.000000,0.000000) [0.000000|1.000000] "" Vector__XXX
 SG_ LH_Blinker_HR_akt  : 15|1@1+ (1.000000,0.000000) [0.000000|1.000000] "" Vector__XXX
 SG_ LH_Blinker_li_def  : 16|1@1+ (1.000000,0.000000) [0.000000|1.000000] "" Vector__XXX
 SG_ LH_Bremsl_li_def  : 17|1@1+ (1.000000,0.000000) [0.000000|1.000000] "" Vector__XXX
 SG_ LH_Schlusslicht_li_def  : 18|1@1+ (1.000000,0.000000) [0.000000|1.000000] "" Vector__XXX
 SG_ LH_Rueckf_li_def  : 19|1@1+ (1.000000,0.000000) [0.000000|1.000000] "" Vector__XXX
 SG_ LH_Nebel_li_def  : 20|1@1+ (1.000000,0.000000) [0.000000|1.000000] "" Vector__XXX
 SG_ LH_Schluss_Brems_Nebel_li_def  : 21|1@1+ (1.000000,0.000000) [0.000000|1.000000] "" Vector__XXX
 SG_ LH_Schluss_Brems_Nebel_re_def  : 22|1@1+ (1.000000,0.000000) [0.000000|1.000000] "" Vector__XXX
 SG_ LH_Zusatzschlussl_def  : 23|1@1+ (1.000000,0.000000) [0.000000|1.000000] "" Vector__XXX
 SG_ LH_Schluss_Brems_li_def  : 24|1@1+ (1.000000,0.000000) [0.000000|1.000000] "" Vector__XXX
 SG_ LH_Schluss_Nebel_li_def  : 25|1@1+ (1.000000,0.000000) [0.000000|1.000000] "" Vector__XXX
 SG_ LH_SL_BRL_BLK_li_def  : 26|1@1+ (1.000000,0.000000) [0.000000|1.000000] "" Vector__XXX
 SG_ LH_Brems_Blk_li_def  : 27|1@1+ (1.000000,0.000000) [0.000000|1.000000] "" Vector__XXX
 SG_ LH_Diag_Status_re_def  : 28|1@1+ (1.000000,0.000000) [0.000000|1.000000] "" Vector__XXX
 SG_ LH_Diag_Status_li_def  : 29|1@1+ (1.000000,0.000000) [0.000000|1.000000] "" Vector__XXX
 SG_ LH_Diag_LED_li_def  : 30|1@1+ (1.000000,0.000000) [0.000000|1.000000] "" Vector__XXX
 SG_ LH_Diag_LED_re_def  : 31|1@1+ (1.000000,0.000000) [0.000000|1.000000] "" Vector__XXX
 SG_ LH_Blinker_re_def  : 32|1@1+ (1.000000,0.000000) [0.000000|1.000000] "" Vector__XXX
 SG_ LH_Bremsl_re_def  : 33|1@1+ (1.000000,0.000000) [0.000000|1.000000] "" Vector__XXX
 SG_ LH_Schlusslicht_re_def  : 34|1@1+ (1.000000,0.000000) [0.000000|1.000000] "" Vector__XXX
 SG_ LH_Rueckf_re_def  : 35|1@1+ (1.000000,0.000000) [0.000000|1.000000] "" Vector__XXX
 SG_ LH_Nebel_re_def  : 36|1@1+ (1.000000,0.000000) [0.000000|1.000000] "" Vector__XXX
 SG_ LH_Schluss_Brems_mi_def  : 37|1@1+ (1.000000,0.000000) [0.000000|1.000000] "" Vector__XXX
 SG_ LH_Schluss_Brems_re_def  : 40|1@1+ (1.000000,0.000000) [0.000000|1.000000] "" Vector__XXX
 SG_ LH_Schluss_Nebel_re_def  : 41|1@1+ (1.000000,0.000000) [0.000000|1.000000] "" Vector__XXX
 SG_ LH_SL_BRL_BLK_re_def  : 42|1@1+ (1.000000,0.000000) [0.000000|1.000000] "" Vector__XXX
 SG_ LH_Brems_Blk_re_def  : 43|1@1+ (1.000000,0.000000) [0.000000|1.000000] "" Vector__XXX
 SG_ LH_Kennzl_def  : 48|1@1+ (1.000000,0.000000) [0.000000|1.000000] "" Vector__XXX
 SG_ LH_3_Bremsl_def  : 49|1@1+ (1.000000,0.000000) [0.000000|1.000000] "" Motor_BEV
 SG_ LH_Nebel_mi_def  : 50|1@1+ (1.000000,0.000000) [0.000000|1.000000] "" Vector__XXX
 SG_ LH_Rueckf_mi_def  : 51|1@1+ (1.000000,0.000000) [0.000000|1.000000] "" Vector__XXX
 SG_ LH_Schlusslicht_mi_def  : 52|1@1+ (1.000000,0.000000) [0.000000|1.000000] "" Vector__XXX
 SG_ LH_Bremsl_li_ges_def  : 54|1@1+ (1.000000,0.000000) [0.000000|1.000000] "" Motor_BEV
 SG_ LH_Bremsl_re_ges_def  : 55|1@1+ (1.000000,0.000000) [0.000000|1.000000] "" Motor_BEV
 SG_ LH_Bremsl_mi_def  : 61|1@1+ (1.000000,0.000000) [0.000000|1.000000] "" Vector__XXX
 SG_ BRL_als_SHL  : 62|1@1+ (1.000000,0.000000) [0.000000|1.000000] "" Vector__XXX

BO_ 134 LWI_01: 8 ICAS1_Gateway
 SG_ LWI_01_CRC  : 0|8@1+ (1.000000,0.000000) [0.000000|255.000000] "" Airbag Motor_BEV
 SG_ LWI_01_BZ  : 8|4@1+ (1.000000,0.000000) [0.000000|15.000000] "" Airbag Motor_BEV
 SG_ LWI_Sensorstatus  : 12|1@1+ (1.000000,0.000000) [0.000000|1.000000] "" Airbag Motor_BEV
 SG_ LWI_QBit_Sub_Daten  : 13|1@1+ (1.000000,0.000000) [0.000000|1.000000] "" Vector__XXX
 SG_ LWI_QBit_Lenkradwinkel  : 15|1@1+ (1.000000,0.000000) [0.000000|1.000000] "" Airbag Motor_BEV
 SG_ LWI_Lenkradwinkel  : 16|13@1+ (0.100000,0.000000) [0.000000|800.000000] "Unit_DegreOfArc" Airbag Motor_BEV
 SG_ LWI_VZ_Lenkradwinkel  : 29|1@1+ (1.000000,0.000000) [0.000000|1.000000] "" Airbag Motor_BEV
 SG_ LWI_VZ_Lenkradw_Geschw  : 30|1@1+ (1.000000,0.000000) [0.000000|1.000000] "" Vector__XXX
 SG_ LWI_Lenkradw_Geschw  : 31|9@1+ (5.000000,0.000000) [0.000000|2500.000000] "Unit_DegreOfArcPerSecon" Airbag
 SG_ LWI_Sub_Daten  : 40|16@1+ (1.000000,0.000000) [0.000000|65535.000000] "" Vector__XXX

BO_ 817 MFL_01: 8 ICAS1_Gateway
 SG_ MFL_Zaehler  : 0|4@1+ (1.000000,0.000000) [0.000000|15.000000] "" Vector__XXX
 SG_ MFL_Toggle  : 4|1@1+ (1.000000,0.000000) [0.000000|1.000000] "" Vector__XXX
 SG_ MFL_Lokalaktiv  : 5|1@1+ (1.000000,0.000000) [0.000000|1.000000] "" Vector__XXX
 SG_ MFL_M_Taste  : 6|1@1+ (1.000000,0.000000) [0.000000|1.000000] "" Vector__XXX
 SG_ MFL_Paddle_Verbau  : 7|1@1+ (1.000000,0.000000) [0.000000|1.000000] "" Vector__XXX
 SG_ MFL_Tastencode_1  : 8|8@1+ (1.000000,0.000000) [0.000000|255.000000] "" Vector__XXX
 SG_ MFL_Tastencode_2  : 16|8@1+ (1.000000,0.000000) [0.000000|255.000000] "" Vector__XXX
 SG_ MFL_Eventcode_1  : 24|4@1+ (1.000000,0.000000) [0.000000|15.000000] "" Vector__XXX
 SG_ MFL_Eventcode_2  : 28|4@1+ (1.000000,0.000000) [0.000000|15.000000] "" Vector__XXX
 SG_ MFL_Marke  : 32|4@1+ (1.000000,0.000000) [0.000000|15.000000] "" Vector__XXX
 SG_ MFL_Variante  : 36|4@1+ (1.000000,0.000000) [0.000000|15.000000] "" Vector__XXX
 SG_ MFL_Dummy_0_Signal_1  : 40|8@1+ (1.000000,0.000000) [0.000000|255.000000] "" Vector__XXX
 SG_ MFL_Tip_Down  : 48|1@1+ (1.000000,0.000000) [0.000000|1.000000] "" Motor_BEV
 SG_ MFL_Tip_Up  : 49|1@1+ (1.000000,0.000000) [0.000000|1.000000] "" Motor_BEV
 SG_ MFL_SatModul_links_Err  : 50|1@1+ (1.000000,0.000000) [0.000000|1.000000] "" Vector__XXX
 SG_ MFL_SatModul_rechts_Err  : 51|1@1+ (1.000000,0.000000) [0.000000|1.000000] "" Vector__XXX
 SG_ MFL_Dummy_0_Signal_2  : 52|1@1+ (1.000000,0.000000) [0.000000|1.000000] "" Vector__XXX
 SG_ MFL_Dummy_0_Signal_3  : 53|1@1+ (1.000000,0.000000) [0.000000|1.000000] "" Vector__XXX
 SG_ MFL_LR_HZG_Status  : 54|1@1+ (1.000000,0.000000) [0.000000|1.000000] "" Vector__XXX
 SG_ MFL_LR_HZG_Err  : 55|1@1+ (1.000000,0.000000) [0.000000|1.000000] "" Vector__XXX
 SG_ MFL_Signalhorn  : 56|1@1+ (1.000000,0.000000) [0.000000|1.000000] "" Vector__XXX
 SG_ MFL_Signalhorn_Err  : 57|1@1+ (1.000000,0.000000) [0.000000|1.000000] "" Vector__XXX
 SG_ MFL_Tip_links_Err  : 58|1@1+ (1.000000,0.000000) [0.000000|1.000000] "" Vector__XXX
 SG_ MFL_Tip_rechts_Err  : 59|1@1+ (1.000000,0.000000) [0.000000|1.000000] "" Vector__XXX
 SG_ MFL_Taste_links_Err  : 60|1@1+ (1.000000,0.000000) [0.000000|1.000000] "" Vector__XXX
 SG_ MFL_Taste_rechts_Err  : 61|1@1+ (1.000000,0.000000) [0.000000|1.000000] "" Vector__XXX
 SG_ MFL_ECU_Err  : 62|1@1+ (1.000000,0.000000) [0.000000|1.000000] "" Vector__XXX
 SG_ MFL_Response_Err  : 63|1@1+ (1.000000,0.000000) [0.000000|1.000000] "" Vector__XXX

BO_ 15 MO_SOPC: 1 Motor_BEV
 SG_ MO_SOPC  : 0|1@1+ (1.000000,0.000000) [0.000000|1.000000] "" Vector__XXX

BO_ 1600 Motor_07: 8 Motor_BEV
 SG_ MO_QBit_Ansaugluft_Temp  : 0|1@1+ (1.000000,0.000000) [0.000000|1.000000] "" Vector__XXX
 SG_ MO_QBit_Oel_Temp  : 1|1@1+ (1.000000,0.000000) [0.000000|1.000000] "" Vector__XXX
 SG_ MO_QBit_Kuehlmittel_Temp  : 2|1@1+ (1.000000,0.000000) [0.000000|1.000000] "" Vector__XXX
 SG_ MO_KL15_Abschaltempfehlung  : 3|1@1+ (1.000000,0.000000) [0.000000|1.000000] "" Vector__XXX
 SG_ MO_HYB_Fehler_HV_Netz  : 4|1@1+ (1.000000,0.000000) [0.000000|1.000000] "" Vector__XXX
 SG_ MO_aktives_Getriebeheizen  : 5|1@1+ (1.000000,0.000000) [0.000000|1.000000] "" Vector__XXX
 SG_ MO_Absperrventil_oeffnen  : 6|2@1+ (1.000000,0.000000) [0.000000|3.000000] "" Vector__XXX
 SG_ MO_Ansaugluft_Temp  : 8|8@1+ (0.750000,-48.000000) [-48.000000|141.750000] "Unit_DegreCelsi" Vector__XXX
 SG_ MO_Oel_Temp  : 16|8@1+ (1.000000,-60.000000) [-60.000000|192.000000] "Unit_DegreCelsi" Vector__XXX
 SG_ MO_Kuehlmittel_Temp  : 24|8@1+ (0.750000,-48.000000) [-48.000000|141.750000] "Unit_DegreCelsi" Vector__XXX
 SG_ MO_Hoeheninfo  : 32|8@1+ (0.007810,0.000000) [0.000000|1.983740] "" Vector__XXX
 SG_ MO_Kennfeldk  : 40|1@1+ (1.000000,0.000000) [0.000000|1.000000] "" Vector__XXX
 SG_ MO_Versionsinfo_02  : 41|5@1+ (1.000000,0.000000) [0.000000|31.000000] "" Vector__XXX
 SG_ MO_QBit_Hoeheninfo  : 46|1@1+ (1.000000,0.000000) [0.000000|1.000000] "" Vector__XXX
 SG_ MO_Getriebe_kuehlen  : 47|1@1+ (1.000000,0.000000) [0.000000|1.000000] "" Vector__XXX
 SG_ MO_Mom_Traegheit_02  : 48|5@1+ (0.010000,0.000000) [0.000000|0.310000] "Unit_KiloGramMeterSquar" Vector__XXX
 SG_ MO_Heizungspumpenansteuerung  : 53|4@1+ (10.000000,0.000000) [0.000000|100.000000] "Unit_PerCent" Vector__XXX
 SG_ MO_SpannungsAnf  : 57|1@1+ (1.000000,0.000000) [0.000000|1.000000] "" Vector__XXX
 SG_ MO_Nachlaufzeit_Heizungspumpe  : 58|6@1+ (15.000000,0.000000) [0.000000|945.000000] "Unit_Secon" Vector__XXX

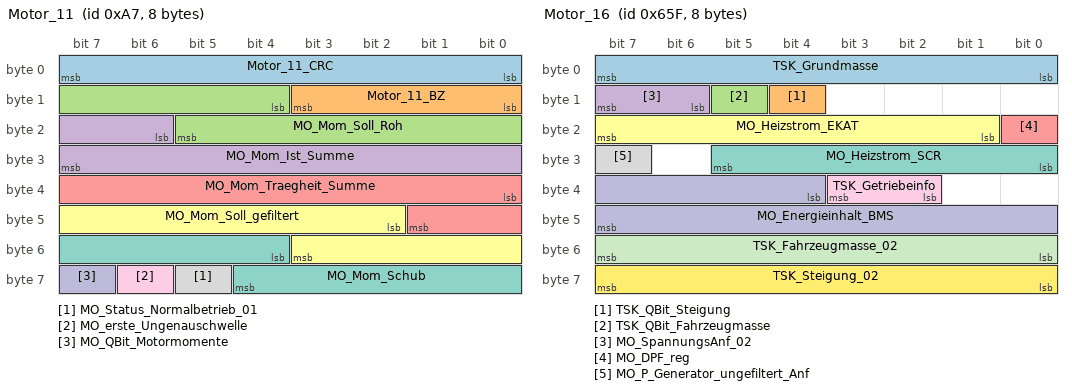
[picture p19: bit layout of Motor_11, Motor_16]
BO_ 167 Motor_11: 8 Motor_BEV
 SG_ Motor_11_CRC  : 0|8@1+ (1.000000,0.000000) [0.000000|255.000000] "" ICAS1_Gateway
 SG_ Motor_11_BZ  : 8|4@1+ (1.000000,0.000000) [0.000000|15.000000] "" ICAS1_Gateway
 SG_ MO_Mom_Soll_Roh  : 12|10@1+ (1.000000,-509.000000) [-509.000000|509.000000] "" ICAS1_Gateway
 SG_ MO_Mom_Ist_Summe  : 22|10@1+ (1.000000,-509.000000) [-509.000000|509.000000] "" ICAS1_Gateway
 SG_ MO_Mom_Traegheit_Summe  : 32|10@1+ (1.000000,-509.000000) [-509.000000|509.000000] "" ICAS1_Gateway
 SG_ MO_Mom_Soll_gefiltert  : 42|10@1+ (1.000000,-509.000000) [-509.000000|509.000000] "" ICAS1_Gateway
 SG_ MO_Mom_Schub  : 52|9@1+ (1.000000,-509.000000) [-509.000000|0.000000] "" ICAS1_Gateway
 SG_ MO_Status_Normalbetrieb_01  : 61|1@1+ (1.000000,0.000000) [0.000000|1.000000] "" ICAS1_Gateway
 SG_ MO_erste_Ungenauschwelle  : 62|1@1+ (1.000000,0.000000) [0.000000|1.000000] "" ICAS1_Gateway
 SG_ MO_QBit_Motormomente  : 63|1@1+ (1.000000,0.000000) [0.000000|1.000000] "" ICAS1_Gateway

BO_ 168 Motor_12: 8 Motor_BEV
 SG_ Motor_12_CRC  : 0|8@1+ (1.000000,0.000000) [0.000000|255.000000] "" ICAS1_Gateway
 SG_ Motor_12_BZ  : 8|4@1+ (1.000000,0.000000) [0.000000|15.000000] "" ICAS1_Gateway
 SG_ MO_Mom_neg_verfuegbar  : 12|9@1+ (1.000000,-509.000000) [-509.000000|0.000000] "" ICAS1_Gateway
 SG_ MO_Mom_Begr_Fahr  : 21|9@1+ (1.000000,0.000000) [0.000000|509.000000] "" ICAS1_Gateway
 SG_ MO_Mom_Begr_Schalt  : 30|10@1+ (1.000000,-509.000000) [-509.000000|509.000000] "" ICAS1_Gateway
 SG_ MO_Momentenintegral_02  : 40|7@1+ (1.000000,0.000000) [0.000000|100.000000] "Unit_PerCent" ICAS1_Gateway
 SG_ MO_QBit_Drehzahl_01  : 47|1@1+ (1.000000,0.000000) [0.000000|1.000000] "" Airbag ICAS1_Gateway LE2
 SG_ MO_Drehzahl_01  : 48|16@1+ (0.250000,0.000000) [0.000000|16383.000000] "Unit_MinutInver" ICAS1_Gateway

BO_ 958 Motor_14: 8 Motor_BEV
 SG_ Motor_14_CRC  : 0|8@1+ (1.000000,0.000000) [0.000000|255.000000] "" ICAS1_Gateway
 SG_ Motor_14_BZ  : 8|4@1+ (1.000000,0.000000) [0.000000|15.000000] "" ICAS1_Gateway
 SG_ MO_StartStopp_Status  : 12|2@1+ (1.000000,0.000000) [0.000000|3.000000] "" ICAS1_Gateway
 SG_ MO_StartStopp_Wiederstart  : 14|1@1+ (1.000000,0.000000) [0.000000|1.000000] "" ICAS1_Gateway
 SG_ MO_StartStopp_Motorstopp  : 15|1@1+ (1.000000,0.000000) [0.000000|1.000000] "" ICAS1_Gateway
 SG_ MO_Freig_Reku  : 16|2@1+ (1.000000,0.000000) [0.000000|3.000000] "" ICAS1_Gateway
 SG_ MO_Kl_75  : 18|1@1+ (1.000000,0.000000) [0.000000|1.000000] "" ICAS1_Gateway
 SG_ MO_Kl_50  : 19|1@1+ (1.000000,0.000000) [0.000000|1.000000] "" ICAS1_Gateway
 SG_ MO_Gangposition  : 20|4@1+ (1.000000,0.000000) [0.000000|15.000000] "" ICAS1_Gateway
 SG_ MO_StartStopp_Fahrerwunsch  : 24|2@1+ (1.000000,0.000000) [0.000000|3.000000] "" ICAS1_Gateway
 SG_ MO_HYB_Fahrbereitschaft  : 26|1@1+ (1.000000,0.000000) [0.000000|1.000000] "" ICAS1_Gateway
 SG_ MO_Ext_E_Fahrt_aktiv  : 27|1@1+ (1.000000,0.000000) [0.000000|1.000000] "" ICAS1_Gateway
 SG_ MO_Fahrer_bremst  : 28|1@1+ (1.000000,0.000000) [0.000000|1.000000] "" Airbag ICAS1_Gateway
 SG_ MO_QBit_Fahrer_bremst  : 29|1@1+ (1.000000,0.000000) [0.000000|1.000000] "" Airbag ICAS1_Gateway
 SG_ MO_BLS  : 30|1@1+ (1.000000,0.000000) [0.000000|1.000000] "" Airbag ICAS1_Gateway
 SG_ MO_Konsistenz_Bremsped  : 31|1@1+ (1.000000,0.000000) [0.000000|1.000000] "" ICAS1_Gateway
 SG_ MO_Timeout_ESP  : 32|1@1+ (1.000000,0.000000) [0.000000|1.000000] "" ICAS1_Gateway
 SG_ MO_Klima_Eingr  : 33|2@1+ (1.000000,0.000000) [0.000000|3.000000] "" ICAS1_Gateway
 SG_ MO_Aussp_Anlass  : 35|1@1+ (1.000000,0.000000) [0.000000|1.000000] "" ICAS1_Gateway
 SG_ MO_Freig_Anlass  : 36|1@1+ (1.000000,0.000000) [0.000000|1.000000] "" ICAS1_Gateway
 SG_ MO_Kuppl_schalter  : 37|1@1+ (1.000000,0.000000) [0.000000|1.000000] "" ICAS1_Gateway
 SG_ MO_Interlock  : 38|1@1+ (1.000000,0.000000) [0.000000|1.000000] "" ICAS1_Gateway
 SG_ MO_Motor_laeuft  : 39|1@1+ (1.000000,0.000000) [0.000000|1.000000] "" ICAS1_Gateway
 SG_ MO_Kickdown  : 40|1@1+ (1.000000,0.000000) [0.000000|1.000000] "" ICAS1_Gateway ICAS1_KommunikationsServer
 SG_ MO_QBit_KL_75  : 41|1@1+ (1.000000,0.000000) [0.000000|1.000000] "" ICAS1_Gateway
 SG_ MO_EKlKomLeiRed  : 42|2@1+ (1.000000,0.000000) [0.000000|3.000000] "" ICAS1_Gateway
 SG_ MO_Handshake_STH  : 44|1@1+ (1.000000,0.000000) [0.000000|1.000000] "" ICAS1_Gateway
 SG_ MO_BKV_Unterdruckwarnung  : 45|1@1+ (1.000000,0.000000) [0.000000|1.000000] "" ICAS1_Gateway
 SG_ MO_Freigabe_Segeln  : 46|1@1+ (1.000000,0.000000) [0.000000|1.000000] "" ICAS1_Gateway
 SG_ MO_PTC_Status  : 47|3@1+ (1.000000,0.000000) [0.000000|7.000000] "" ICAS1_Gateway
 SG_ MO_QBit_Gangposition  : 50|1@1+ (1.000000,0.000000) [0.000000|1.000000] "" ICAS1_Gateway
 SG_ MO_Signalquelle_Gangposition  : 51|1@1+ (1.000000,0.000000) [0.000000|1.000000] "" ICAS1_Gateway
 SG_ MO_Remotestart_Betrieb  : 52|1@1+ (1.000000,0.000000) [0.000000|1.000000] "" ICAS1_Gateway
 SG_ MO_Remotestart_moeglich  : 53|1@1+ (1.000000,0.000000) [0.000000|1.000000] "" ICAS1_Gateway
 SG_ MO_FMAus_aktiv  : 55|1@1+ (1.000000,0.000000) [0.000000|1.000000] "" ICAS1_Gateway
 SG_ MO_FMAus_Startvariante  : 56|2@1+ (1.000000,0.000000) [0.000000|3.000000] "" ICAS1_Gateway
 SG_ MO_BMS_NV_Anf_stuetzen  : 58|1@1+ (1.000000,0.000000) [0.000000|1.000000] "" ICAS1_Gateway
 SG_ MO_Zylinderabschaltung  : 59|2@1+ (1.000000,0.000000) [0.000000|3.000000] "" ICAS1_Gateway
 SG_ MO_HYB_VM_aktiv  : 61|1@1+ (1.000000,0.000000) [0.000000|1.000000] "" ICAS1_Gateway
 SG_ MO_StartVorauss_erfuellt  : 62|2@1+ (1.000000,0.000000) [0.000000|3.000000] "" ICAS1_Gateway

BO_ 1631 Motor_16: 8 Motor_BEV
 SG_ TSK_Grundmasse  : 0|8@1+ (32.000000,0.000000) [0.000000|8128.000000] "Unit_KiloGram" ICAS1_Gateway
 SG_ TSK_QBit_Steigung  : 12|1@1+ (1.000000,0.000000) [0.000000|1.000000] "" ICAS1_Gateway
 SG_ TSK_QBit_Fahrzeugmasse  : 13|1@1+ (1.000000,0.000000) [0.000000|1.000000] "" ICAS1_Gateway
 SG_ MO_SpannungsAnf_02  : 14|2@1+ (1.000000,0.000000) [0.000000|3.000000] "" ICAS1_Gateway
 SG_ MO_DPF_reg  : 16|1@1+ (1.000000,0.000000) [0.000000|1.000000] "" ICAS1_Gateway
 SG_ MO_Heizstrom_EKAT  : 17|7@1+ (1.000000,0.000000) [0.000000|126.000000] "Unit_Amper" ICAS1_Gateway
 SG_ MO_Heizstrom_SCR  : 24|6@1+ (1.000000,0.000000) [0.000000|62.000000] "Unit_Amper" ICAS1_Gateway
 SG_ MO_P_Generator_ungefiltert_Anf  : 31|1@1+ (1.000000,0.000000) [0.000000|1.000000] "" ICAS1_Gateway
 SG_ TSK_Getriebeinfo  : 34|2@1+ (1.000000,0.000000) [0.000000|3.000000] "" ICAS1_Gateway
 SG_ MO_Energieinhalt_BMS  : 36|12@1+ (25.000000,0.000000) [0.000000|102325.000000] "Unit_WattHour" ICAS1_Gateway
 SG_ TSK_Fahrzeugmasse_02  : 48|8@1+ (32.000000,0.000000) [0.000000|8128.000000] "Unit_KiloGram" ICAS1_Gateway
 SG_ TSK_Steigung_02  : 56|8@1+ (0.800000,-101.600000) [-100.800000|101.600000] "Unit_PerCent" ICAS1_Gateway

BO_ 1648 Motor_18: 8 Motor_BEV
 SG_ MO_max_Ladedruck  : 0|6@1+ (0.100000,0.000000) [0.000000|6.300000] "Unit_Bar" ICAS1_Gateway
 SG_ MO_ANC_Kennfeld_Anf  : 6|2@1+ (1.000000,0.000000) [0.000000|3.000000] "" ICAS1_Gateway
 SG_ MO_Bremslicht_Reku  : 8|1@1+ (1.000000,0.000000) [0.000000|1.000000] "" ICAS1_Gateway
 SG_ MO_StartStopp_PopUp  : 9|2@1+ (1.000000,0.000000) [0.000000|3.000000] "" ICAS1_Gateway
 SG_ MO1_Sperr_Info_WFS  : 11|1@1+ (1.000000,0.000000) [0.000000|1.000000] "" ICAS1_Gateway
 SG_ MO1_Freigabe_Info_WFS  : 12|1@1+ (1.000000,0.000000) [0.000000|1.000000] "" ICAS1_Gateway
 SG_ MO_EPCL  : 13|3@1+ (1.000000,0.000000) [0.000000|7.000000] "" ICAS1_Gateway ICAS1_KommunikationsServer
 SG_ MO_Zylabsch_Texte_02  : 16|4@1+ (1.000000,0.000000) [0.000000|15.000000] "" ICAS1_Gateway
 SG_ MO_Fahrzeugtyp  : 20|3@1+ (1.000000,0.000000) [0.000000|7.000000] "" ICAS1_Gateway ICAS1_KommunikationsServer
 SG_ MO_NMAX_Schaltanzeige  : 23|9@1+ (25.000000,0.000000) [0.000000|12775.000000] "Unit_MinutInver" ICAS1_Gateway
 SG_ MO_Abstellzeit  : 32|8@1+ (8.000000,0.000000) [0.000000|2024.000000] "Unit_Minut" ICAS1_Gateway
 SG_ MO_Abstellzeit_Status  : 40|2@1+ (1.000000,0.000000) [0.000000|3.000000] "" ICAS1_Gateway
 SG_ MO1_Freigabe_Verfallsinfo_WFS  : 42|1@1+ (1.000000,0.000000) [0.000000|1.000000] "" ICAS1_Gateway
 SG_ MO_Hybrid_StartStopp_LED  : 43|2@1+ (1.000000,0.000000) [0.000000|3.000000] "" ICAS1_Gateway
 SG_ MO_Fehler_Zylabsch  : 45|2@1+ (1.000000,0.000000) [0.000000|3.000000] "" ICAS1_Gateway
 SG_ MO_Anzahl_Abgesch_Zyl  : 47|3@1+ (1.000000,0.000000) [0.000000|7.000000] "" ICAS1_Gateway
 SG_ MO_Zylabsch_Texte  : 50|2@1+ (1.000000,0.000000) [0.000000|3.000000] "" ICAS1_Gateway
 SG_ MO_Ethanol_BS_Texte  : 52|3@1+ (1.000000,0.000000) [0.000000|7.000000] "" ICAS1_Gateway
 SG_ MO_Drehzahl_Warnung  : 55|1@1+ (1.000000,0.000000) [0.000000|1.000000] "" ICAS1_Gateway
 SG_ MO_obere_Drehzahlgrenze  : 56|8@1+ (50.000000,0.000000) [50.000000|12750.000000] "Unit_MinutInver" ICAS1_Gateway
